VERSION "created by canmatrix"

NS_ :

BS_:

BU_: IPD

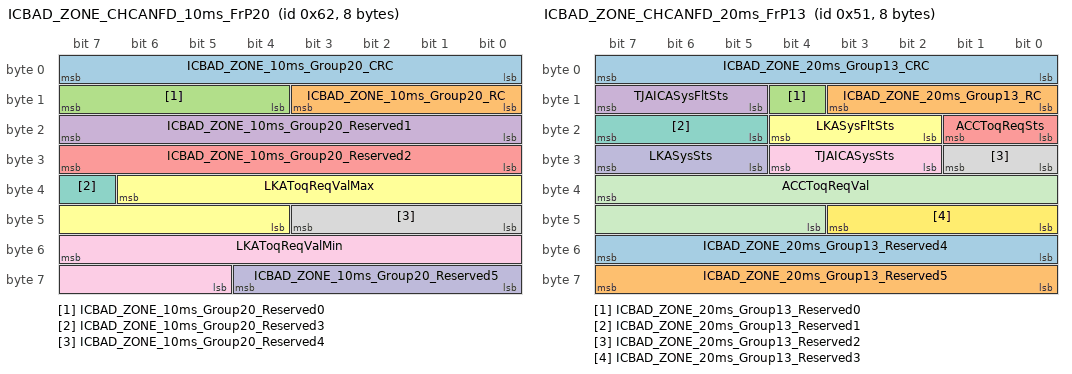
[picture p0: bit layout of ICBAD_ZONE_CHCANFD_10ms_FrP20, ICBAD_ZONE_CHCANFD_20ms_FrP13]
BO_ 98 ICBAD_ZONE_CHCANFD_10ms_FrP20: 8 IPD
 SG_ ICBAD_ZONE_10ms_Group20_CRC : 7|8@0+ (1,0) [0|255] "null" Vector__XXX
 SG_ ICBAD_ZONE_10ms_Group20_RC : 11|4@0+ (1,0) [0|15] "null" Vector__XXX
 SG_ ICBAD_ZONE_10ms_Group20_Reserved0 : 15|4@0+ (1,0) [0|15] "null" Vector__XXX
 SG_ ICBAD_ZONE_10ms_Group20_Reserved1 : 23|8@0+ (1,0) [0|255] "null" Vector__XXX
 SG_ ICBAD_ZONE_10ms_Group20_Reserved2 : 31|8@0+ (1,0) [0|255] "null" Vector__XXX
 SG_ LKAToqReqValMax : 38|11@0+ (0.01,-10.24) [-10.24|10.23] "Nm" Vector__XXX
 SG_ ICBAD_ZONE_10ms_Group20_Reserved3 : 39|1@0+ (1,0) [0|1] "null" Vector__XXX
 SG_ ICBAD_ZONE_10ms_Group20_Reserved4 : 43|4@0+ (1,0) [0|15] "null" Vector__XXX
 SG_ LKAToqReqValMin : 55|11@0+ (0.01,-10.24) [-10.24|10.23] "Nm" Vector__XXX
 SG_ ICBAD_ZONE_10ms_Group20_Reserved5 : 60|5@0+ (1,0) [0|31] "null" Vector__XXX

BO_ 81 ICBAD_ZONE_CHCANFD_20ms_FrP13: 8 IPD
 SG_ ICBAD_ZONE_20ms_Group13_CRC : 7|8@0+ (1,0) [0|255] "null" Vector__XXX
 SG_ ICBAD_ZONE_20ms_Group13_RC : 11|4@0+ (1,0) [0|15] "null" Vector__XXX
 SG_ ICBAD_ZONE_20ms_Group13_Reserved0 : 12|1@0+ (1,0) [0|1] "null" Vector__XXX
 SG_ TJAICASysFltSts : 15|3@0+ (1,0) [0|7] "null" Vector__XXX
 SG_ ACCToqReqSts : 17|2@0+ (1,0) [0|3] "null" Vector__XXX
 SG_ LKASysFltSts : 20|3@0+ (1,0) [0|7] "null" Vector__XXX
 SG_ ICBAD_ZONE_20ms_Group13_Reserved1 : 23|3@0+ (1,0) [0|7] "null" Vector__XXX
 SG_ ICBAD_ZONE_20ms_Group13_Reserved2 : 25|2@0+ (1,0) [0|3] "null" Vector__XXX
 SG_ TJAICASysSts : 28|3@0+ (1,0) [0|7] "null" Vector__XXX
 SG_ LKASysSts : 31|3@0+ (1,0) [0|7] "null" Vector__XXX
 SG_ ACCToqReqVal : 39|12@0+ (0.5,-848) [-848|1199.5] "null" Vector__XXX
 SG_ ICBAD_ZONE_20ms_Group13_Reserved3 : 43|4@0+ (1,0) [0|15] "null" Vector__XXX
 SG_ ICBAD_ZONE_20ms_Group13_Reserved4 : 55|8@0+ (1,0) [0|255] "null" Vector__XXX
 SG_ ICBAD_ZONE_20ms_Group13_Reserved5 : 63|8@0+ (1,0) [0|255] "null" Vector__XXX

BO_ 807 IPD_BKPCANFD_100ms_FrP35: 64 IPD
 SG_ TSRTrgtWarnSign : 23|7@0+ (1,0) [0|127] "null" Vector__XXX
 SG_ SpdAstSysTrgtSpd_IPD : 55|15@0+ (0.015625,0) [0.000000|511.984375] "null" Vector__XXX
 SG_ TSRTrgtBanSign : 77|6@0+ (1,0) [0|63] "null" Vector__XXX
 SG_ TSRSwReqResp : 97|2@0+ (1,0) [0|3] "null" Vector__XXX
 SG_ SLIFSts_IPD : 100|3@0+ (1,0) [0|7] "null" Vector__XXX
 SG_ TSRSts : 111|3@0+ (1,0) [0|7] "null" Vector__XXX
 SG_ PilotSysAVCamrF1FltSts : 244|3@0+ (1,0) [0|7] "null" Vector__XXX
 SG_ PilotSysADASFltSts : 247|3@0+ (1,0) [0|7] "null" Vector__XXX
 SG_ AIParkngSSPLotSwSts : 249|2@0+ (1,0) [0|3] "null" Vector__XXX
 SG_ PilotSysAVCamrRFltSts : 252|3@0+ (1,0) [0|7] "null" Vector__XXX
 SG_ PilotSysAVCamrF3FltSts : 255|3@0+ (1,0) [0|7] "null" Vector__XXX
 SG_ PilotSysAVCamrFRSFltSts : 260|3@0+ (1,0) [0|7] "null" Vector__XXX
 SG_ PilotSysAVCamrFLSFltSts : 263|3@0+ (1,0) [0|7] "null" Vector__XXX
 SG_ PilotSysAVCamrRRSFltSts : 268|3@0+ (1,0) [0|7] "null" Vector__XXX
 SG_ PilotSysAVCamrRLSFltSts : 271|3@0+ (1,0) [0|7] "null" Vector__XXX
 SG_ PilotSysHDAVMCamrRFltSts : 276|3@0+ (1,0) [0|7] "null" Vector__XXX
 SG_ PilotSysHDAVMCamrFFltSts : 279|3@0+ (1,0) [0|7] "null" Vector__XXX
 SG_ PilotSysHDAVMCamrRHFltSts : 284|3@0+ (1,0) [0|7] "null" Vector__XXX
 SG_ PilotSysHDAVMCamrLHFltSts : 287|3@0+ (1,0) [0|7] "null" Vector__XXX
 SG_ SLIFWrnngMdResp : 289|2@0+ (1,0) [0|3] "null" Vector__XXX
 SG_ PilotSysLFSDAFltSts : 292|3@0+ (1,0) [0|7] "null" Vector__XXX
 SG_ PilotSysFDRFltSts : 295|3@0+ (1,0) [0|7] "null" Vector__XXX
 SG_ TrgtSpdSrcSts_IPD : 297|2@0+ (1,0) [0|3] "null" Vector__XXX
 SG_ PilotSysLHRDAFltSts : 300|3@0+ (1,0) [0|7] "null" Vector__XXX
 SG_ PilotSysRFSDAFltSts : 303|3@0+ (1,0) [0|7] "null" Vector__XXX
 SG_ SLIFAudWrnng_IPD : 304|1@0+ (1,0) [0|1] "null" Vector__XXX
 SG_ SLIFUpdtInd_IPD : 305|1@0+ (1,0) [0|1] "null" Vector__XXX
 SG_ PilotSysFLIDARFltSts : 308|3@0+ (1,0) [0|7] "null" Vector__XXX
 SG_ PilotSysRHRDAFltSts : 311|3@0+ (1,0) [0|7] "null" Vector__XXX
 SG_ PilotSysUSSFltSts : 319|3@0+ (1,0) [0|7] "null" Vector__XXX
 SG_ HORWarningEvtSts : 338|3@0+ (1,0) [0|7] "null" Vector__XXX
 SG_ EORWarningEvtSts : 341|3@0+ (1,0) [0|7] "null" Vector__XXX
 SG_ PosALCFailed : 351|8@0+ (1,0) [0|255] "null" Vector__XXX
 SG_ SLIFSysFltSts : 355|3@0+ (1,0) [0|7] "null" Vector__XXX
 SG_ ADS_ISAMsgReq : 359|4@0+ (1,0) [0|15] "null" Vector__XXX
 SG_ SLIFUpdtIndResp_IPD : 361|2@0+ (1,0) [0|3] "null" Vector__XXX
 SG_ ADS_ISASysFltSts : 364|3@0+ (1,0) [0|7] "null" Vector__XXX
 SG_ ADS_ISASysSts : 367|3@0+ (1,0) [0|7] "null" Vector__XXX
 SG_ ParkngSpdSwResp : 375|2@0+ (1,0) [0|3] "null" Vector__XXX

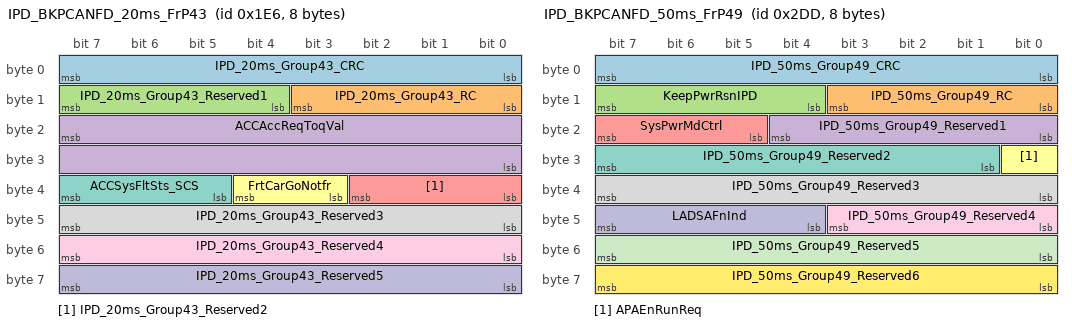
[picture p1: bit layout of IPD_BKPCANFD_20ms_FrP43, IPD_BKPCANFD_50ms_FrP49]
BO_ 486 IPD_BKPCANFD_20ms_FrP43: 8 IPD
 SG_ IPD_20ms_Group43_CRC : 7|8@0+ (1,0) [0|255] "null" Vector__XXX
 SG_ IPD_20ms_Group43_RC : 11|4@0+ (1,0) [0|15] "null" Vector__XXX
 SG_ IPD_20ms_Group43_Reserved1 : 15|4@0+ (1,0) [0|15] "null" Vector__XXX
 SG_ ACCAccReqToqVal : 23|16@0+ (1,0) [0|65535] "Nm" Vector__XXX
 SG_ IPD_20ms_Group43_Reserved2 : 34|3@0+ (1,0) [0|7] "null" Vector__XXX
 SG_ FrtCarGoNotfr : 36|2@0+ (1,0) [0|3] "null" Vector__XXX
 SG_ ACCSysFltSts_SCS : 39|3@0+ (1,0) [0|7] "null" Vector__XXX
 SG_ IPD_20ms_Group43_Reserved3 : 47|8@0+ (1,0) [0|255] "null" Vector__XXX
 SG_ IPD_20ms_Group43_Reserved4 : 55|8@0+ (1,0) [0|255] "null" Vector__XXX
 SG_ IPD_20ms_Group43_Reserved5 : 63|8@0+ (1,0) [0|255] "null" Vector__XXX

BO_ 337 IPD_BKPCANFD_20ms_FrP60: 20 IPD
 SG_ IPD_20ms_Group60_CRC : 7|8@0+ (1,0) [0|255] "null" Vector__XXX
 SG_ IPD_20ms_Group60_RC : 11|4@0+ (1,0) [0|15] "null" Vector__XXX
 SG_ AutoLaneChngRLaneSts : 15|4@0+ (1,0) [0|15] "null" Vector__XXX
 SG_ IPD_20ms_Group60_Reserved1 : 23|8@0+ (1,0) [0|255] "null" Vector__XXX
 SG_ IPD_20ms_Group60_Reserved2 : 31|8@0+ (1,0) [0|255] "null" Vector__XXX
 SG_ APASCSToqReqVal : 39|16@0+ (1,0) [0|65535] "Nm" Vector__XXX
 SG_ APAVehCrdnatPosY : 55|13@0+ (1,-4096) [-4096|4095] "cm" Vector__XXX
 SG_ APAVehCrdnatAzmth : 56|9@0+ (1,0) [0|511] "degree" Vector__XXX
 SG_ ESSDirInd : 58|2@0+ (1,0) [0|3] "null" Vector__XXX
 SG_ PilotTkovMsgReq : 75|4@0+ (1,0) [0|15] "null" Vector__XXX
 SG_ NOPSysSts_ZPD : 79|4@0+ (1,0) [0|15] "null" Vector__XXX
 SG_ PrkgDstCtrlSwResp : 81|2@0+ (1,0) [0|3] "null" Vector__XXX
 SG_ ALCSysSts : 84|3@0+ (1,0) [0|7] "null" Vector__XXX
 SG_ ALCSysFltSts : 87|3@0+ (1,0) [0|7] "null" Vector__XXX
 SG_ APAVehCrdnatPosX : 95|12@0+ (1,-2048) [-2048|2047] "cm" Vector__XXX
 SG_ AutoLaneChngLLaneSts : 99|4@0+ (1,0) [0|15] "null" Vector__XXX
 SG_ IPD_20ms_Group60_Reserved4 : 105|2@0+ (1,0) [0|3] "null" Vector__XXX
 SG_ ESSSysSts : 108|3@0+ (1,0) [0|7] "null" Vector__XXX
 SG_ ESSSysFltSts : 111|3@0+ (1,0) [0|7] "null" Vector__XXX
 SG_ IPD_20ms_Group60_Reserved6 : 112|1@0+ (1,0) [0|1] "null" Vector__XXX
 SG_ ESSDrvrTkovReq : 113|1@0+ (1,0) [0|1] "null" Vector__XXX
 SG_ IPD_20ms_Group60_Reserved5 : 116|3@0+ (1,0) [0|7] "null" Vector__XXX
 SG_ Parkngslottype : 119|3@0+ (1,0) [0|7] "null" Vector__XXX
 SG_ IPD_20ms_Group60_Reserved7 : 124|5@0+ (1,0) [0|31] "null" Vector__XXX
 SG_ NOPSysFltSts : 127|3@0+ (1,0) [0|7] "null" Vector__XXX
 SG_ IPD_20ms_Group60_Reserved8 : 135|8@0+ (1,0) [0|255] "null" Vector__XXX
 SG_ IPD_20ms_Group60_Reserved9 : 143|8@0+ (1,0) [0|255] "null" Vector__XXX
 SG_ IPD_20ms_Group60_Reserved10 : 151|8@0+ (1,0) [0|255] "null" Vector__XXX
 SG_ IPD_20ms_Group60_Reserved11 : 159|8@0+ (1,0) [0|255] "null" Vector__XXX

BO_ 733 IPD_BKPCANFD_50ms_FrP49: 8 IPD
 SG_ IPD_50ms_Group49_CRC : 7|8@0+ (1,0) [0|255] "null" Vector__XXX
 SG_ IPD_50ms_Group49_RC : 11|4@0+ (1,0) [0|15] "null" Vector__XXX
 SG_ KeepPwrRsnIPD : 15|4@0+ (1,0) [0|15] "null" Vector__XXX
 SG_ IPD_50ms_Group49_Reserved1 : 20|5@0+ (1,0) [0|31] "null" Vector__XXX
 SG_ SysPwrMdCtrl : 23|3@0+ (1,0) [0|7] "null" Vector__XXX
 SG_ APAEnRunReq : 24|1@0+ (1,0) [0|1] "null" Vector__XXX
 SG_ IPD_50ms_Group49_Reserved2 : 31|7@0+ (1,0) [0|127] "null" Vector__XXX
 SG_ IPD_50ms_Group49_Reserved3 : 39|8@0+ (1,0) [0|255] "null" Vector__XXX
 SG_ IPD_50ms_Group49_Reserved4 : 43|4@0+ (1,0) [0|15] "null" Vector__XXX
 SG_ LADSAFnInd : 47|4@0+ (1,0) [0|15] "null" Vector__XXX
 SG_ IPD_50ms_Group49_Reserved5 : 55|8@0+ (1,0) [0|255] "null" Vector__XXX
 SG_ IPD_50ms_Group49_Reserved6 : 63|8@0+ (1,0) [0|255] "null" Vector__XXX

BO_ 590 IPD_BKPCANFD_50ms_FrP62: 32 IPD
 SG_ RoadProfileShockDistL1 : 23|10@0+ (0.05,0) [0.00|51.15] "null" Vector__XXX
 SG_ RoadProfileShockDistL2 : 25|10@0+ (0.05,0) [0.00|51.15] "null" Vector__XXX
 SG_ RoadProfileShockDetectedL1 : 29|4@0+ (1,0) [0|15] "null" Vector__XXX
 SG_ RoadProfileShockDistL3 : 47|10@0+ (0.05,0) [0.00|51.15] "null" Vector__XXX
 SG_ RoadProfileShockDistR1 : 49|10@0+ (0.05,0) [0.00|51.15] "null" Vector__XXX
 SG_ RoadProfileShockDetectedL2 : 53|4@0+ (1,0) [0|15] "null" Vector__XXX
 SG_ RoadProfileShockDistR2 : 71|10@0+ (0.05,0) [0.00|51.15] "null" Vector__XXX
 SG_ RoadProfileShockDistR3 : 73|10@0+ (0.05,0) [0.00|51.15] "null" Vector__XXX
 SG_ RoadProfileShockDetectedL3 : 77|4@0+ (1,0) [0|15] "null" Vector__XXX
 SG_ RoadProfileShockHeightL1 : 95|9@0- (0.002,0) [-0.512|0.510] "null" Vector__XXX
 SG_ RoadProfileShockConfidenceL1 : 102|7@0+ (0.01,0) [0.00|1.27] "percent" Vector__XXX
 SG_ RoadProfileShockHeightL2 : 111|9@0- (0.002,0) [-0.512|0.510] "null" Vector__XXX
 SG_ RoadProfileShockConfidenceL2 : 118|7@0+ (0.01,0) [0.00|1.27] "percent" Vector__XXX
 SG_ RoadProfileShockHeightL3 : 127|9@0- (0.002,0) [-0.512|0.510] "null" Vector__XXX
 SG_ RoadProfileShockConfidenceL3 : 134|7@0+ (0.01,0) [0.00|1.27] "percent" Vector__XXX
 SG_ RoadProfileShockHeightR1 : 143|9@0- (0.002,0) [-0.512|0.510] "null" Vector__XXX
 SG_ RoadProfileShockConfidenceR1 : 150|7@0+ (0.01,0) [0.00|1.27] "percent" Vector__XXX
 SG_ RoadProfileShockHeightR2 : 159|9@0- (0.002,0) [-0.512|0.510] "null" Vector__XXX
 SG_ RoadProfileShockConfidenceR2 : 166|7@0+ (0.01,0) [0.00|1.27] "percent" Vector__XXX
 SG_ RoadProfileShockHeightR3 : 175|9@0- (0.002,0) [-0.512|0.510] "null" Vector__XXX
 SG_ RoadProfileShockConfidenceR3 : 182|7@0+ (0.01,0) [0.00|1.27] "percent" Vector__XXX
 SG_ RoadHeightL : 191|9@0- (0.002,0) [-0.512|0.510] "null" Vector__XXX
 SG_ PrvOutSts : 194|2@0+ (1,0) [0|3] "null" Vector__XXX
 SG_ RoadProfileShockDetectedR1 : 198|4@0+ (1,0) [0|15] "null" Vector__XXX
 SG_ RoadHeightR : 207|9@0- (0.002,0) [-0.512|0.510] "null" Vector__XXX
 SG_ RoadProfileShockDetectedR3 : 219|4@0+ (1,0) [0|15] "null" Vector__XXX
 SG_ RoadProfileShockDetectedR2 : 223|4@0+ (1,0) [0|15] "null" Vector__XXX

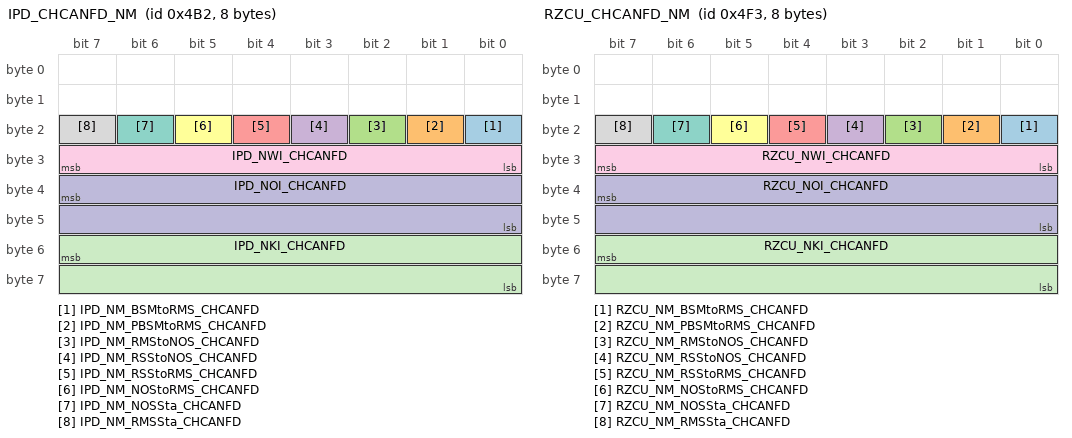
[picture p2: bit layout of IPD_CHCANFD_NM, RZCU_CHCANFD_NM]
BO_ 1202 IPD_CHCANFD_NM: 8 IPD
 SG_ IPD_NM_BSMtoRMS_CHCANFD : 16|1@0+ (1,0) [0|1] "null" Vector__XXX
 SG_ IPD_NM_PBSMtoRMS_CHCANFD : 17|1@0+ (1,0) [0|1] "null" Vector__XXX
 SG_ IPD_NM_RMStoNOS_CHCANFD : 18|1@0+ (1,0) [0|1] "null" Vector__XXX
 SG_ IPD_NM_RSStoNOS_CHCANFD : 19|1@0+ (1,0) [0|1] "null" Vector__XXX
 SG_ IPD_NM_RSStoRMS_CHCANFD : 20|1@0+ (1,0) [0|1] "null" Vector__XXX
 SG_ IPD_NM_NOStoRMS_CHCANFD : 21|1@0+ (1,0) [0|1] "null" Vector__XXX
 SG_ IPD_NM_NOSSta_CHCANFD : 22|1@0+ (1,0) [0|1] "null" Vector__XXX
 SG_ IPD_NM_RMSSta_CHCANFD : 23|1@0+ (1,0) [0|1] "null" Vector__XXX
 SG_ IPD_NWI_CHCANFD : 31|8@0+ (1,0) [0|255] "null" Vector__XXX
 SG_ IPD_NOI_CHCANFD : 39|16@0+ (1,0) [0|65535] "null" Vector__XXX
 SG_ IPD_NKI_CHCANFD : 55|16@0+ (1,0) [0|65535] "null" Vector__XXX

BO_ 1267 RZCU_CHCANFD_NM: 8 Vector__XXX
 SG_ RZCU_NM_BSMtoRMS_CHCANFD : 16|1@0+ (1,0) [0|1] "null" Vector__XXX
 SG_ RZCU_NM_PBSMtoRMS_CHCANFD : 17|1@0+ (1,0) [0|1] "null" Vector__XXX
 SG_ RZCU_NM_RMStoNOS_CHCANFD : 18|1@0+ (1,0) [0|1] "null" Vector__XXX
 SG_ RZCU_NM_RSStoNOS_CHCANFD : 19|1@0+ (1,0) [0|1] "null" Vector__XXX
 SG_ RZCU_NM_RSStoRMS_CHCANFD : 20|1@0+ (1,0) [0|1] "null" Vector__XXX
 SG_ RZCU_NM_NOStoRMS_CHCANFD : 21|1@0+ (1,0) [0|1] "null" Vector__XXX
 SG_ RZCU_NM_NOSSta_CHCANFD : 22|1@0+ (1,0) [0|1] "null" Vector__XXX
 SG_ RZCU_NM_RMSSta_CHCANFD : 23|1@0+ (1,0) [0|1] "null" Vector__XXX
 SG_ RZCU_NWI_CHCANFD : 31|8@0+ (1,0) [0|255] "null" Vector__XXX
 SG_ RZCU_NOI_CHCANFD : 39|16@0+ (1,0) [0|65535] "null" Vector__XXX
 SG_ RZCU_NKI_CHCANFD : 55|16@0+ (1,0) [0|65535] "null" Vector__XXX

BO_ 143 RZCU_RZCUCANFD_10ms_FrP64: 32 Vector__XXX
 SG_ RZCU_ZONE_10ms_Group64_CRC : 7|8@0+ (1,0) [0|255] "null" IPD
 SG_ RZCU_ZONE_10ms_Group64_RC : 11|4@0+ (1,0) [0|15] "null" IPD
 SG_ AngularRateXsecinfoV : 12|1@0+ (1,0) [0|1] "null" IPD
 SG_ AccelerationZsecinfoV : 13|1@0+ (1,0) [0|1] "null" IPD
 SG_ AccelerationYsecinfoV : 14|1@0+ (1,0) [0|1] "null" IPD
 SG_ AccelerationXsecinfoV : 15|1@0+ (1,0) [0|1] "null" IPD
 SG_ AccelerationXsecinfo : 23|24@0- (0.00010,0) [-838.86080|838.86070] "m/s2" IPD
 SG_ AccelerationYsecinfo : 47|24@0- (0.00010,0) [-838.86080|838.86070] "m/s2" IPD
 SG_ AccelerationZsecinfo : 71|24@0- (0.00010,0) [-838.86080|838.86070] "m/s2" IPD
 SG_ AngularRateXsecinfo : 95|24@0- (0.000010,0) [-83.886080|83.886070] "°/s" IPD
 SG_ AngularRateYsecinfo : 119|24@0- (0.000010,0) [-83.886080|83.886070] "°/s" IPD
 SG_ AngularRateZsecinfo : 143|24@0- (0.000010,0) [-83.886080|83.886070] "°/s" IPD
 SG_ IMUTmp : 163|12@0- (0.1,0) [-204.8|204.7] "degreecelslus" IPD
 SG_ TireBlowoutStabCtrlSts : 165|2@0+ (1,0) [0|3] "null" IPD
 SG_ AngularRateZsecinfoV : 166|1@0+ (1,0) [0|1] "null" IPD
 SG_ AngularRateYsecinfoV : 167|1@0+ (1,0) [0|1] "null" IPD
 SG_ IMUseq : 183|32@0+ (1,0) [0|4294967295] "/" IPD
 SG_ RZCU_ZONE_10ms_Group64_Reserved1 : 211|4@0+ (1,0) [0|15] "null" IPD
 SG_ TireBlowoutPos : 215|4@0+ (1,0) [0|15] "null" IPD
 SG_ RZCU_ZONE_10ms_Group64_Reserved2 : 223|8@0+ (1,0) [0|255] "null" IPD
 SG_ RZCU_ZONE_10ms_Group64_Reserved3 : 231|8@0+ (1,0) [0|255] "null" IPD
 SG_ RZCU_ZONE_10ms_Group64_Reserved4 : 239|8@0+ (1,0) [0|255] "null" IPD
 SG_ RZCU_ZONE_10ms_Group64_Reserved5 : 247|8@0+ (1,0) [0|255] "null" IPD
 SG_ RZCU_ZONE_10ms_Group64_Reserved6 : 255|8@0+ (1,0) [0|255] "null" IPD

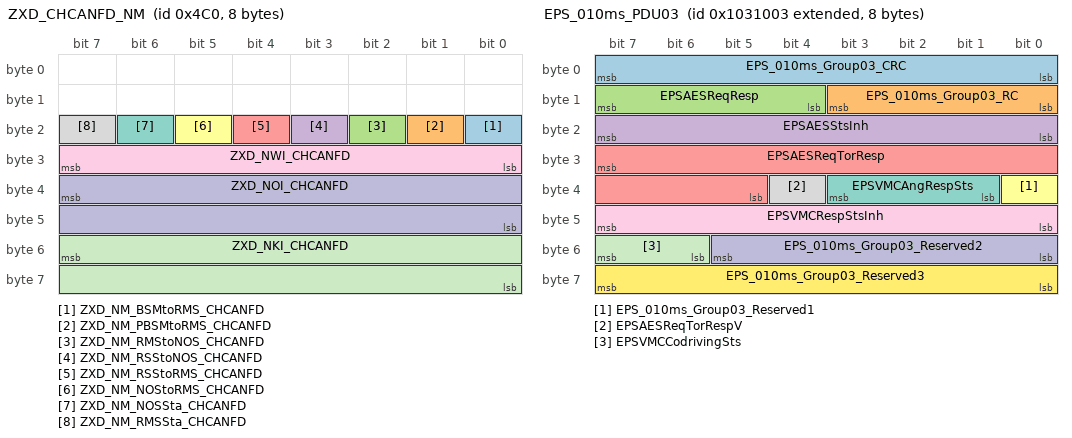
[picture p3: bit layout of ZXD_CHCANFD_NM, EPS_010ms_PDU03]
BO_ 1216 ZXD_CHCANFD_NM: 8 Vector__XXX
 SG_ ZXD_NM_BSMtoRMS_CHCANFD : 16|1@0+ (1,0) [0|1] "null" Vector__XXX
 SG_ ZXD_NM_PBSMtoRMS_CHCANFD : 17|1@0+ (1,0) [0|1] "null" Vector__XXX
 SG_ ZXD_NM_RMStoNOS_CHCANFD : 18|1@0+ (1,0) [0|1] "null" Vector__XXX
 SG_ ZXD_NM_RSStoNOS_CHCANFD : 19|1@0+ (1,0) [0|1] "null" Vector__XXX
 SG_ ZXD_NM_RSStoRMS_CHCANFD : 20|1@0+ (1,0) [0|1] "null" Vector__XXX
 SG_ ZXD_NM_NOStoRMS_CHCANFD : 21|1@0+ (1,0) [0|1] "null" Vector__XXX
 SG_ ZXD_NM_NOSSta_CHCANFD : 22|1@0+ (1,0) [0|1] "null" Vector__XXX
 SG_ ZXD_NM_RMSSta_CHCANFD : 23|1@0+ (1,0) [0|1] "null" Vector__XXX
 SG_ ZXD_NWI_CHCANFD : 31|8@0+ (1,0) [0|255] "null" Vector__XXX
 SG_ ZXD_NOI_CHCANFD : 39|16@0+ (1,0) [0|65535] "null" Vector__XXX
 SG_ ZXD_NKI_CHCANFD : 55|16@0+ (1,0) [0|65535] "null" Vector__XXX

BO_ 2164461571 EPS_010ms_PDU03: 8 Vector__XXX
 SG_ EPS_010ms_Group03_CRC : 7|8@0+ (1,0) [0|255] "null" IPD
 SG_ EPS_010ms_Group03_RC : 11|4@0+ (1,0) [0|15] "null" IPD
 SG_ EPSAESReqResp : 15|4@0+ (1,0) [0|15] "null" IPD
 SG_ EPSAESStsInh : 23|8@0+ (1,0) [0|255] "null" IPD
 SG_ EPSAESReqTorResp : 31|11@0+ (0.01,-10.24) [-10.24|10.23] "Nm" IPD
 SG_ EPS_010ms_Group03_Reserved1 : 32|1@0+ (1,0) [0|1] "null" IPD
 SG_ EPSVMCAngRespSts : 35|3@0+ (1,0) [0|7] "null" IPD
 SG_ EPSAESReqTorRespV : 36|1@0+ (1,0) [0|1] "null" IPD
 SG_ EPSVMCRespStsInh : 47|8@0+ (1,0) [0|255] "null" IPD
 SG_ EPS_010ms_Group03_Reserved2 : 53|6@0+ (1,0) [0|63] "null" IPD
 SG_ EPSVMCCodrivingSts : 55|2@0+ (1,0) [0|3] "null" IPD
 SG_ EPS_010ms_Group03_Reserved3 : 63|8@0+ (1,0) [0|255] "null" IPD

BO_ 2164729093 EPS_10ms_PDU01: 24 Vector__XXX
 SG_ EPS_10ms_Group01_CRC : 7|8@0+ (1,0) [0|255] "null" IPD
 SG_ EPS_10ms_Group01_RC : 11|4@0+ (1,0) [0|15] "null" IPD
 SG_ ActuRoadWhlAngV : 12|1@0+ (1,0) [0|1] "null" IPD
 SG_ ADASStrgDlvrdToqV : 13|1@0+ (1,0) [0|1] "null" IPD
 SG_ EPSDrvngMdCtrlInh : 14|1@0+ (1,0) [0|1] "null" IPD
 SG_ DrvrStrgDlvrdToqV : 15|1@0+ (1,0) [0|1] "null" IPD
 SG_ ActuPnonAng : 23|16@0+ (0.0625,-2048) [-2048.0000|2047.9375] "degree" IPD
 SG_ ActuRoadWhlAng : 39|16@0+ (0.005,-163) [-163.000|164.675] "degree" IPD
 SG_ StrgCustSetngDspCmd : 49|2@0+ (1,0) [0|3] "null" IPD
 SG_ EPSPriyChnlFlrSts : 51|2@0+ (1,0) [0|3] "null" IPD
 SG_ EPSFlrSts : 53|2@0+ (1,0) [0|3] "null" IPD
 SG_ EPSCurntDrvMd : 55|2@0+ (1,0) [0|3] "null" IPD
 SG_ ActuPnonAngV : 56|1@0+ (1,0) [0|1] "null" IPD
 SG_ EPSToqValAldMaxV : 57|1@0+ (1,0) [0|1] "null" IPD
 SG_ EPSLimMotToqV : 58|1@0+ (1,0) [0|1] "null" IPD
 SG_ EPSActRetMotToqV : 59|1@0+ (1,0) [0|1] "null" IPD
 SG_ EPS_10ms_Group01_Reserved1 : 60|1@0+ (1,0) [0|1] "null" IPD
 SG_ ChLKAAngReqResp : 63|3@0+ (1,0) [0|7] "null" IPD
 SG_ EPS_10ms_Group01_Reserved2 : 67|4@0+ (1,0) [0|15] "null" IPD
 SG_ EPSToqValAldMinV : 68|1@0+ (1,0) [0|1] "null" IPD
 SG_ CHLKAHptResp : 71|3@0+ (1,0) [0|7] "null" IPD
 SG_ EPS_10ms_Group01_Reserved3 : 79|8@0+ (1,0) [0|255] "null" IPD
 SG_ ADASStrgDlvrdToq : 82|11@0+ (0.01,-10.24) [-10.24|10.23] "Nm" IPD
 SG_ EPS_10ms_Group01_Reserved4 : 84|2@0+ (1,0) [0|3] "null" IPD
 SG_ ChLKAToqReqResp : 87|3@0+ (1,0) [0|7] "null" IPD
 SG_ EPSToqValAldMax : 98|11@0+ (0.01,-10.24) [-10.24|10.23] "Nm" IPD
 SG_ EPSCoDrivingSts : 100|2@0+ (1,0) [0|3] "null" IPD
 SG_ EPS_10ms_Group01_Reserved5 : 103|3@0+ (1,0) [0|7] "null" IPD
 SG_ EPSToqValAldMin : 114|11@0+ (0.01,-10.24) [-10.24|10.23] "Nm" IPD
 SG_ EPS_10ms_Group01_Reserved6 : 119|5@0+ (1,0) [0|31] "null" IPD
 SG_ EPSActRetMotToq : 135|16@0+ (0.00097656,-32) [-32.00000000|31.99885960] "Nm" IPD
 SG_ EPS_10ms_Group01_Reserved7 : 151|8@0+ (1,0) [0|255] "null" IPD
 SG_ DrvrStrgDlvrdToq : 159|12@0+ (0.01,-20.48) [-20.48|20.47] "Nm" IPD
 SG_ EPS_10ms_Group01_Reserved8 : 163|4@0+ (1,0) [0|15] "null" IPD
 SG_ EPS_10ms_Group01_Reserved9 : 175|8@0+ (1,0) [0|255] "null" IPD
 SG_ EPSLimMotToq : 183|16@0+ (0.00097656,-32) [-32.00000000|31.99885960] "Nm" IPD

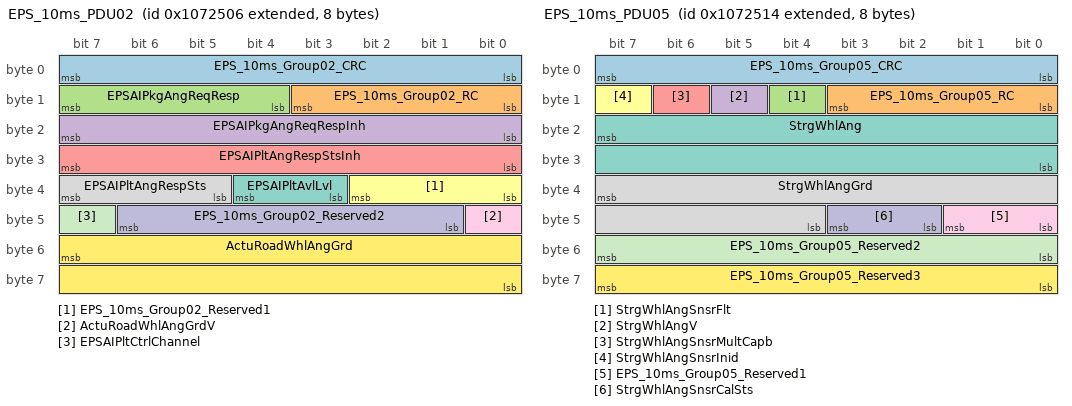
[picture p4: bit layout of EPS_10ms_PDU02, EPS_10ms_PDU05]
BO_ 2164729094 EPS_10ms_PDU02: 8 Vector__XXX
 SG_ EPS_10ms_Group02_CRC : 7|8@0+ (1,0) [0|255] "null" IPD
 SG_ EPS_10ms_Group02_RC : 11|4@0+ (1,0) [0|15] "null" IPD
 SG_ EPSAIPkgAngReqResp : 15|4@0+ (1,0) [0|15] "null" IPD
 SG_ EPSAIPkgAngReqRespInh : 23|8@0+ (1,0) [0|255] "null" IPD
 SG_ EPSAIPltAngRespStsInh : 31|8@0+ (1,0) [0|255] "null" IPD
 SG_ EPS_10ms_Group02_Reserved1 : 34|3@0+ (1,0) [0|7] "null" IPD
 SG_ EPSAIPltAvlLvl : 36|2@0+ (1,0) [0|3] "null" IPD
 SG_ EPSAIPltAngRespSts : 39|3@0+ (1,0) [0|7] "null" IPD
 SG_ ActuRoadWhlAngGrdV : 40|1@0+ (1,0) [0|1] "null" IPD
 SG_ EPS_10ms_Group02_Reserved2 : 46|6@0+ (1,0) [0|63] "null" IPD
 SG_ EPSAIPltCtrlChannel : 47|1@0+ (1,0) [0|1] "null" IPD
 SG_ ActuRoadWhlAngGrd : 55|16@0+ (0.005,-163) [-163.000|164.675] "deg_s" IPD

BO_ 2164729108 EPS_10ms_PDU05: 8 Vector__XXX
 SG_ EPS_10ms_Group05_CRC : 7|8@0+ (1,0) [0|255] "null" IPD
 SG_ EPS_10ms_Group05_RC : 11|4@0+ (1,0) [0|15] "null" IPD
 SG_ StrgWhlAngSnsrFlt : 12|1@0+ (1,0) [0|1] "null" IPD
 SG_ StrgWhlAngV : 13|1@0+ (1,0) [0|1] "null" IPD
 SG_ StrgWhlAngSnsrMultCapb : 14|1@0+ (1,0) [0|1] "null" IPD
 SG_ StrgWhlAngSnsrInid : 15|1@0+ (1,0) [0|1] "null" IPD
 SG_ StrgWhlAng : 23|16@0+ (0.0625,-2048) [-2048.0000|2047.9375] "degree" IPD
 SG_ StrgWhlAngGrd : 39|12@0+ (1,-2048) [-2048|2047] "degree/s" IPD
 SG_ EPS_10ms_Group05_Reserved1 : 41|2@0+ (1,0) [0|3] "null" IPD
 SG_ StrgWhlAngSnsrCalSts : 43|2@0+ (1,0) [0|3] "null" IPD
 SG_ EPS_10ms_Group05_Reserved2 : 55|8@0+ (1,0) [0|255] "null" IPD
 SG_ EPS_10ms_Group05_Reserved3 : 63|8@0+ (1,0) [0|255] "null" IPD

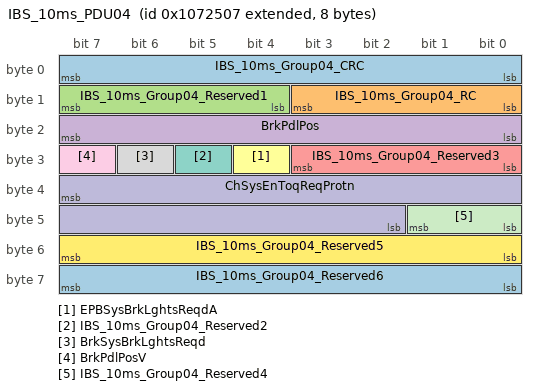
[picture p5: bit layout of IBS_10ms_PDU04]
BO_ 2164729095 IBS_10ms_PDU04: 8 Vector__XXX
 SG_ IBS_10ms_Group04_CRC : 7|8@0+ (1,0) [0|255] "null" IPD
 SG_ IBS_10ms_Group04_RC : 11|4@0+ (1,0) [0|15] "null" IPD
 SG_ IBS_10ms_Group04_Reserved1 : 15|4@0+ (1,0) [0|15] "null" IPD
 SG_ BrkPdlPos : 23|8@0+ (0.392157,0) [0.000000|100.000035] "Percent" IPD
 SG_ IBS_10ms_Group04_Reserved3 : 27|4@0+ (1,0) [0|15] "null" IPD
 SG_ EPBSysBrkLghtsReqdA : 28|1@0+ (1,0) [0|1] "null" IPD
 SG_ IBS_10ms_Group04_Reserved2 : 29|1@0+ (1,0) [0|1] "null" IPD
 SG_ BrkSysBrkLghtsReqd : 30|1@0+ (1,0) [0|1] "null" IPD
 SG_ BrkPdlPosV : 31|1@0+ (1,0) [0|1] "null" IPD
 SG_ ChSysEnToqReqProtn : 39|14@0+ (1,0) [0|16383] "null" IPD
 SG_ IBS_10ms_Group04_Reserved4 : 41|2@0+ (1,0) [0|3] "null" IPD
 SG_ IBS_10ms_Group04_Reserved5 : 55|8@0+ (1,0) [0|255] "null" IPD
 SG_ IBS_10ms_Group04_Reserved6 : 63|8@0+ (1,0) [0|255] "null" IPD

BO_ 2164729097 IBS_20ms_PDU10: 8 Vector__XXX
 SG_ IBS_20ms_Group10_CRC : 7|8@0+ (1,0) [0|255] "null" IPD
 SG_ IBS_20ms_Group10_RC : 11|4@0+ (1,0) [0|15] "null" IPD
 SG_ BrkPdlDrvrAppdPrsV : 12|1@0+ (1,0) [0|1] "null" IPD
 SG_ BrkPdlDrvrAppdPrsDetV : 13|1@0+ (1,0) [0|1] "null" IPD
 SG_ BrkPdlDrvrAppdPrsDet : 14|1@0+ (1,0) [0|1] "null" IPD
 SG_ BrkDiscTemSts : 15|1@0+ (1,0) [0|1] "null" IPD
 SG_ BrkPdlDrvrAppdPrs : 23|8@0+ (75,0) [0|19125] "kPa" IPD
 SG_ BrkPdlMdlSts : 25|2@0+ (1,0) [0|3] "null" IPD
 SG_ DrvrReqOtptRodTrvlSts : 27|2@0+ (1,0) [0|3] "null" IPD
 SG_ BrkPdlSimltdPrsV : 28|1@0+ (1,0) [0|1] "null" IPD
 SG_ BrkPdlAppd : 29|1@0+ (1,0) [0|1] "null" IPD
 SG_ BrkPdlAppdV : 31|2@0+ (1,0) [0|3] "null" IPD
 SG_ BrkPdlSimltdPrs : 39|8@0+ (75,0) [0|19125] "kPa" IPD
 SG_ BrkFludLvlLowV : 40|1@0+ (1,0) [0|1] "null" IPD
 SG_ BrkFludLvlLow : 41|1@0+ (1,0) [0|1] "null" IPD
 SG_ BrkPdlMdlActSts : 43|2@0+ (1,0) [0|3] "null" IPD
 SG_ IBS_20ms_Group10_Reserved1 : 47|4@0+ (1,0) [0|15] "null" IPD
 SG_ DrvrReqOtptRodTrvl : 51|12@0+ (0.015625,-5) [-5.000000|58.984375] "mm" IPD
 SG_ IBS_20ms_Group10_Reserved2 : 55|4@0+ (1,0) [0|15] "null" IPD

BO_ 2164729104 IBS_20ms_PDU13: 8 Vector__XXX
 SG_ IBS_20ms_Group13_CRC : 7|8@0+ (1,0) [0|255] "null" IPD
 SG_ IBS_20ms_Group13_RC : 11|4@0+ (1,0) [0|15] "null" IPD
 SG_ ACCBrkngA : 12|1@0+ (1,0) [0|1] "null" IPD
 SG_ ChAEBDclReqResp : 15|3@0+ (1,0) [0|7] "null" IPD
 SG_ ChACCReqFlrSts : 17|2@0+ (1,0) [0|3] "null" IPD
 SG_ ChACCAccReqResp : 20|3@0+ (1,0) [0|7] "null" IPD
 SG_ ChAEBPrflReqResp : 23|3@0+ (1,0) [0|7] "null" IPD
 SG_ AutodDrvngSysMdReqRespV : 24|1@0+ (1,0) [0|1] "null" IPD
 SG_ AutodDrvngSysMdReqResp : 25|1@0+ (1,0) [0|1] "null" IPD
 SG_ ChAEBHydBrkAstReqResp : 28|3@0+ (1,0) [0|7] "null" IPD
 SG_ ChAEBBrkJerkReqResp : 31|3@0+ (1,0) [0|7] "null" IPD
 SG_ SCSAutodDrvngSysSts : 34|3@0+ (1,0) [0|7] "null" IPD
 SG_ SCSAPAAcclAV : 35|1@0+ (1,0) [0|1] "null" IPD
 SG_ SCSAPAAcclA : 36|1@0+ (1,0) [0|1] "null" IPD
 SG_ ExtnlBrkPrioV : 37|1@0+ (1,0) [0|1] "null" IPD
 SG_ ExtnlBrkPrio : 38|1@0+ (1,0) [0|1] "null" IPD
 SG_ EmgcBrkReqdByIECUSts : 39|1@0+ (1,0) [0|1] "null" IPD
 SG_ TCSDrvrItnt : 40|1@0+ (1,0) [0|1] "null" IPD
 SG_ MultColBrkAvlblySts : 41|1@0+ (1,0) [0|1] "null" IPD
 SG_ ChRCTBDclReqResp : 44|3@0+ (1,0) [0|7] "null" IPD
 SG_ SCSVehHoldAV : 45|1@0+ (1,0) [0|1] "null" IPD
 SG_ SCSVehHoldA : 46|1@0+ (1,0) [0|1] "null" IPD
 SG_ SCSAutodDrvngSysStsV : 47|1@0+ (1,0) [0|1] "null" IPD
 SG_ VehSdslStsV : 48|1@0+ (1,0) [0|1] "null" IPD
 SG_ ChRCTBPrflReqResp : 51|3@0+ (1,0) [0|7] "null" IPD
 SG_ WhlBrkPrsSts : 52|1@0+ (1,0) [0|1] "null" IPD
 SG_ BrkSysRddySysSts : 53|1@0+ (1,0) [0|1] "null" IPD
 SG_ VehSdslSts : 55|2@0+ (1,0) [0|3] "null" IPD
 SG_ ChEBADclReqResp : 60|5@0+ (1,0) [0|31] "null" IPD
 SG_ IBSAPASysFltSts : 63|3@0+ (1,0) [0|7] "null" IPD

BA_DEF_ BO_ "FrameTriggeringName" STRING;
BA_DEF_ BO_ "GenMsgCycleTime" INT 0 65535;
BA_DEF_ BO_ "GenMsgSendType" ENUM  "cyclicX","spontanX","cyclicIfActiveX","spontanWithDelay","cyclicAndSpontanX","cyclicAndSpontanWithDelay","spontanWithRepitition","cyclicIfActiveAndSpontanWD","cyclicIfActiveFast","cyclicWithRepeatOnDemand","none";
BA_DEF_ BO_ "GenMsgStartValue" STRING;
BA_DEF_ BO_ "PduName" STRING;
BA_DEF_ BO_ "VFrameFormat" ENUM  "StandardCAN","ExtendedCAN","reserved","reserved","reserved","reserved","reserved","reserved","reserved","reserved","reserved","reserved","reserved","reserved","StandardCAN_FD","ExtendedCAN_FD";
BA_DEF_ SG_ "CompuMethodName" STRING;
BA_DEF_ SG_ "GenSigStartValue" FLOAT 0 100000000000;
BA_DEF_ SG_ "ISignalName" STRING;
BA_DEF_ SG_ "LongName" STRING;
BA_DEF_ SG_ "SysSignalName" STRING;
BA_DEF_ SG_ "SystemSignalLongSymbol" STRING;
BA_ "FrameTriggeringName" BO_ 98 "ICBAD_ZONE_CHCANFD_10ms_FrP20";
BA_ "GenMsgCycleTime" BO_ 98 10;
BA_ "GenMsgSendType" BO_ 98 0;
BA_ "GenMsgStartValue" BO_ 98 "00f0ffffc00f801f";
BA_ "PduName" BO_ 98 "ICBAD_ZONE_10ms_PDU20";
BA_ "VFrameFormat" BO_ 98 14;
BA_ "FrameTriggeringName" BO_ 81 "ICBAD_ZONE_CHCANFD_20ms_FrP13";
BA_ "GenMsgCycleTime" BO_ 81 20;
BA_ "GenMsgSendType" BO_ 81 0;
BA_ "GenMsgStartValue" BO_ 81 "0010e0036a0fffff";
BA_ "PduName" BO_ 81 "ICBAD_ZONE_20ms_PDU13";
BA_ "VFrameFormat" BO_ 81 14;
BA_ "FrameTriggeringName" BO_ 807 "IPD_BKPCANFD_100ms_FrP35";
BA_ "GenMsgCycleTime" BO_ 807 100;
BA_ "GenMsgSendType" BO_ 807 0;
BA_ "GenMsgStartValue" BO_ 807 "00000000000000000000000000000000000000000000000000000000000000000000000000000000000000000000000000000000000000000000000000000000";
BA_ "PduName" BO_ 807 "IPD_100ms_PDU35";
BA_ "VFrameFormat" BO_ 807 14;
BA_ "FrameTriggeringName" BO_ 486 "IPD_BKPCANFD_20ms_FrP43";
BA_ "GenMsgCycleTime" BO_ 486 20;
BA_ "GenMsgSendType" BO_ 486 0;
BA_ "GenMsgStartValue" BO_ 486 "00f0000007ffffff";
BA_ "PduName" BO_ 486 "IPD_20ms_PDU43";
BA_ "VFrameFormat" BO_ 486 14;
BA_ "FrameTriggeringName" BO_ 337 "IPD_BKPCANFD_20ms_FrP60";
BA_ "GenMsgCycleTime" BO_ 337 20;
BA_ "GenMsgSendType" BO_ 337 0;
BA_ "GenMsgStartValue" BO_ 337 "0000ffff000000000000010000071d1fffffffff";
BA_ "PduName" BO_ 337 "IPD_20ms_PDU60";
BA_ "VFrameFormat" BO_ 337 14;
BA_ "FrameTriggeringName" BO_ 733 "IPD_BKPCANFD_50ms_FrP49";
BA_ "GenMsgCycleTime" BO_ 733 50;
BA_ "GenMsgSendType" BO_ 733 0;
BA_ "GenMsgStartValue" BO_ 733 "00001ffeff0fffff";
BA_ "PduName" BO_ 733 "IPD_50ms_PDU49";
BA_ "VFrameFormat" BO_ 733 14;
BA_ "FrameTriggeringName" BO_ 590 "IPD_BKPCANFD_50ms_FrP62";
BA_ "GenMsgCycleTime" BO_ 590 50;
BA_ "GenMsgSendType" BO_ 590 0;
BA_ "GenMsgStartValue" BO_ 590 "0000000000000000000000000000000000000000000000000000000000000000";
BA_ "PduName" BO_ 590 "IPD_50ms_PDU62";
BA_ "VFrameFormat" BO_ 590 14;
BA_ "FrameTriggeringName" BO_ 1202 "IPD_CHCANFD_NM";
BA_ "GenMsgSendType" BO_ 1202 1;
BA_ "GenMsgStartValue" BO_ 1202 "0000000000000000";
BA_ "PduName" BO_ 1202 "NmPDU_CHCANFD_IPD";
BA_ "VFrameFormat" BO_ 1202 14;
BA_ "FrameTriggeringName" BO_ 1267 "RZCU_CHCANFD_NM";
BA_ "GenMsgSendType" BO_ 1267 1;
BA_ "GenMsgStartValue" BO_ 1267 "0000000000000000";
BA_ "PduName" BO_ 1267 "NmPDU_CHCANFD_RZCU";
BA_ "VFrameFormat" BO_ 1267 14;
BA_ "FrameTriggeringName" BO_ 143 "RZCU_RZCUCANFD_10ms_FrP64";
BA_ "GenMsgCycleTime" BO_ 143 10;
BA_ "GenMsgSendType" BO_ 143 0;
BA_ "GenMsgStartValue" BO_ 143 "00000000000000000000000000000000000000000000000000000fffffffffff";
BA_ "PduName" BO_ 143 "RZCU_10ms_PDU64";
BA_ "VFrameFormat" BO_ 143 14;
BA_ "FrameTriggeringName" BO_ 1216 "ZXD_CHCANFD_NM";
BA_ "GenMsgSendType" BO_ 1216 1;
BA_ "GenMsgStartValue" BO_ 1216 "0000000000000000";
BA_ "PduName" BO_ 1216 "NmPDU_CHCANFD_ZXD";
BA_ "VFrameFormat" BO_ 1216 14;
BA_ "FrameTriggeringName" BO_ 2164461571 "EPS_CHCANFD_10ms_ConFrP01__EPS_010ms_PDU03";
BA_ "GenMsgCycleTime" BO_ 2164461571 10;
BA_ "GenMsgSendType" BO_ 2164461571 1;
BA_ "PduName" BO_ 2164461571 "EPS_010ms_PDU03";
BA_ "VFrameFormat" BO_ 2164461571 15;
BA_ "FrameTriggeringName" BO_ 2164729093 "EPS_CHCANFD_10ms_ConFrP01__EPS_10ms_PDU01";
BA_ "GenMsgCycleTime" BO_ 2164729093 10;
BA_ "GenMsgSendType" BO_ 2164729093 1;
BA_ "PduName" BO_ 2164729093 "EPS_10ms_PDU01";
BA_ "VFrameFormat" BO_ 2164729093 15;
BA_ "FrameTriggeringName" BO_ 2164729094 "EPS_CHCANFD_10ms_ConFrP01__EPS_10ms_PDU02";
BA_ "GenMsgCycleTime" BO_ 2164729094 10;
BA_ "GenMsgSendType" BO_ 2164729094 1;
BA_ "PduName" BO_ 2164729094 "EPS_10ms_PDU02";
BA_ "VFrameFormat" BO_ 2164729094 15;
BA_ "FrameTriggeringName" BO_ 2164729108 "EPS_CHCANFD_10ms_ConFrP05__EPS_10ms_PDU05";
BA_ "GenMsgCycleTime" BO_ 2164729108 10;
BA_ "GenMsgSendType" BO_ 2164729108 1;
BA_ "PduName" BO_ 2164729108 "EPS_10ms_PDU05";
BA_ "VFrameFormat" BO_ 2164729108 15;
BA_ "FrameTriggeringName" BO_ 2164729095 "IBS_CHCANFD_10ms_ConFrP04__IBS_10ms_PDU04";
BA_ "GenMsgCycleTime" BO_ 2164729095 10;
BA_ "GenMsgSendType" BO_ 2164729095 1;
BA_ "PduName" BO_ 2164729095 "IBS_10ms_PDU04";
BA_ "VFrameFormat" BO_ 2164729095 15;
BA_ "FrameTriggeringName" BO_ 2164729097 "IBS_CHCANFD_20ms_ConFrP10__IBS_20ms_PDU10";
BA_ "GenMsgCycleTime" BO_ 2164729097 20;
BA_ "GenMsgSendType" BO_ 2164729097 1;
BA_ "PduName" BO_ 2164729097 "IBS_20ms_PDU10";
BA_ "VFrameFormat" BO_ 2164729097 15;
BA_ "FrameTriggeringName" BO_ 2164729104 "IBS_CHCANFD_20ms_ConFrP10__IBS_20ms_PDU13";
BA_ "GenMsgCycleTime" BO_ 2164729104 20;
BA_ "GenMsgSendType" BO_ 2164729104 1;
BA_ "PduName" BO_ 2164729104 "IBS_20ms_PDU13";
BA_ "VFrameFormat" BO_ 2164729104 15;
BA_ "CompuMethodName" SG_ 98 ICBAD_ZONE_10ms_Group20_CRC "ICBAD_ZONE_10ms_Group20_CRC";
BA_ "ISignalName" SG_ 98 ICBAD_ZONE_10ms_Group20_CRC "IICBAD_ZONE_10ms_Group20_CRC";
BA_ "LongName" SG_ 98 ICBAD_ZONE_10ms_Group20_CRC "ICBAD_ZONE_10ms_Group20_CRC";
BA_ "SysSignalName" SG_ 98 ICBAD_ZONE_10ms_Group20_CRC "ICBAD_ZONE_10ms_Group20_CRC";
BA_ "CompuMethodName" SG_ 98 ICBAD_ZONE_10ms_Group20_RC "ICBAD_ZONE_10ms_Group20_RC";
BA_ "ISignalName" SG_ 98 ICBAD_ZONE_10ms_Group20_RC "IICBAD_ZONE_10ms_Group20_RC";
BA_ "LongName" SG_ 98 ICBAD_ZONE_10ms_Group20_RC "ICBAD_ZONE_10ms_Group20_RC";
BA_ "SysSignalName" SG_ 98 ICBAD_ZONE_10ms_Group20_RC "ICBAD_ZONE_10ms_Group20_RC";
BA_ "CompuMethodName" SG_ 98 ICBAD_ZONE_10ms_Group20_Reserved0 "ICBAD_ZONE_10ms_Group20_Reserved1";
BA_ "GenSigStartValue" SG_ 98 ICBAD_ZONE_10ms_Group20_Reserved0 15;
BA_ "ISignalName" SG_ 98 ICBAD_ZONE_10ms_Group20_Reserved0 "IICBAD_ZONE_10ms_Group20_Reserved1";
BA_ "SysSignalName" SG_ 98 ICBAD_ZONE_10ms_Group20_Reserved0 "ICBAD_ZONE_10ms_Group20_Reserved1";
BA_ "SystemSignalLongSymbol" SG_ 98 ICBAD_ZONE_10ms_Group20_Reserved0 "ICBAD_ZONE_10ms_Group20_Reserved1";
BA_ "CompuMethodName" SG_ 98 ICBAD_ZONE_10ms_Group20_Reserved1 "ICBAD_ZONE_10ms_Group20_Reserved2";
BA_ "GenSigStartValue" SG_ 98 ICBAD_ZONE_10ms_Group20_Reserved1 255;
BA_ "ISignalName" SG_ 98 ICBAD_ZONE_10ms_Group20_Reserved1 "IICBAD_ZONE_10ms_Group20_Reserved2";
BA_ "SysSignalName" SG_ 98 ICBAD_ZONE_10ms_Group20_Reserved1 "ICBAD_ZONE_10ms_Group20_Reserved2";
BA_ "SystemSignalLongSymbol" SG_ 98 ICBAD_ZONE_10ms_Group20_Reserved1 "ICBAD_ZONE_10ms_Group20_Reserved2";
BA_ "CompuMethodName" SG_ 98 ICBAD_ZONE_10ms_Group20_Reserved2 "ICBAD_ZONE_10ms_Group20_Reserved3";
BA_ "GenSigStartValue" SG_ 98 ICBAD_ZONE_10ms_Group20_Reserved2 255;
BA_ "ISignalName" SG_ 98 ICBAD_ZONE_10ms_Group20_Reserved2 "IICBAD_ZONE_10ms_Group20_Reserved3";
BA_ "SysSignalName" SG_ 98 ICBAD_ZONE_10ms_Group20_Reserved2 "ICBAD_ZONE_10ms_Group20_Reserved3";
BA_ "SystemSignalLongSymbol" SG_ 98 ICBAD_ZONE_10ms_Group20_Reserved2 "ICBAD_ZONE_10ms_Group20_Reserved3";
BA_ "CompuMethodName" SG_ 98 LKAToqReqValMax "LKAToqReqValMax";
BA_ "GenSigStartValue" SG_ 98 LKAToqReqValMax 1024;
BA_ "ISignalName" SG_ 98 LKAToqReqValMax "ILKAToqReqValMax";
BA_ "LongName" SG_ 98 LKAToqReqValMax "Lane Keeping Assist Torque Request Value Maximum";
BA_ "SysSignalName" SG_ 98 LKAToqReqValMax "LKAToqReqValMax";
BA_ "CompuMethodName" SG_ 98 ICBAD_ZONE_10ms_Group20_Reserved3 "ICBAD_ZONE_10ms_Group20_Reserved4";
BA_ "GenSigStartValue" SG_ 98 ICBAD_ZONE_10ms_Group20_Reserved3 1;
BA_ "ISignalName" SG_ 98 ICBAD_ZONE_10ms_Group20_Reserved3 "IICBAD_ZONE_10ms_Group20_Reserved4";
BA_ "SysSignalName" SG_ 98 ICBAD_ZONE_10ms_Group20_Reserved3 "ICBAD_ZONE_10ms_Group20_Reserved4";
BA_ "SystemSignalLongSymbol" SG_ 98 ICBAD_ZONE_10ms_Group20_Reserved3 "ICBAD_ZONE_10ms_Group20_Reserved4";
BA_ "CompuMethodName" SG_ 98 ICBAD_ZONE_10ms_Group20_Reserved4 "ICBAD_ZONE_10ms_Group20_Reserved5";
BA_ "GenSigStartValue" SG_ 98 ICBAD_ZONE_10ms_Group20_Reserved4 15;
BA_ "ISignalName" SG_ 98 ICBAD_ZONE_10ms_Group20_Reserved4 "IICBAD_ZONE_10ms_Group20_Reserved5";
BA_ "SysSignalName" SG_ 98 ICBAD_ZONE_10ms_Group20_Reserved4 "ICBAD_ZONE_10ms_Group20_Reserved5";
BA_ "SystemSignalLongSymbol" SG_ 98 ICBAD_ZONE_10ms_Group20_Reserved4 "ICBAD_ZONE_10ms_Group20_Reserved5";
BA_ "CompuMethodName" SG_ 98 LKAToqReqValMin "LKAToqReqValMin";
BA_ "GenSigStartValue" SG_ 98 LKAToqReqValMin 1024;
BA_ "ISignalName" SG_ 98 LKAToqReqValMin "ILKAToqReqValMin";
BA_ "LongName" SG_ 98 LKAToqReqValMin "Lane Keeping Assist Torque Request Value Minimum";
BA_ "SysSignalName" SG_ 98 LKAToqReqValMin "LKAToqReqValMin";
BA_ "CompuMethodName" SG_ 98 ICBAD_ZONE_10ms_Group20_Reserved5 "ICBAD_ZONE_10ms_Group20_Reserved6";
BA_ "GenSigStartValue" SG_ 98 ICBAD_ZONE_10ms_Group20_Reserved5 31;
BA_ "ISignalName" SG_ 98 ICBAD_ZONE_10ms_Group20_Reserved5 "IICBAD_ZONE_10ms_Group20_Reserved6";
BA_ "SysSignalName" SG_ 98 ICBAD_ZONE_10ms_Group20_Reserved5 "ICBAD_ZONE_10ms_Group20_Reserved6";
BA_ "SystemSignalLongSymbol" SG_ 98 ICBAD_ZONE_10ms_Group20_Reserved5 "ICBAD_ZONE_10ms_Group20_Reserved6";
BA_ "CompuMethodName" SG_ 81 ICBAD_ZONE_20ms_Group13_CRC "ICBAD_ZONE_20ms_Group13_CRC";
BA_ "ISignalName" SG_ 81 ICBAD_ZONE_20ms_Group13_CRC "IICBAD_ZONE_20ms_Group13_CRC";
BA_ "LongName" SG_ 81 ICBAD_ZONE_20ms_Group13_CRC "ICBAD_ZONE_20ms_Group13_CRC";
BA_ "SysSignalName" SG_ 81 ICBAD_ZONE_20ms_Group13_CRC "ICBAD_ZONE_20ms_Group13_CRC";
BA_ "CompuMethodName" SG_ 81 ICBAD_ZONE_20ms_Group13_RC "ICBAD_ZONE_20ms_Group13_RC";
BA_ "ISignalName" SG_ 81 ICBAD_ZONE_20ms_Group13_RC "IICBAD_ZONE_20ms_Group13_RC";
BA_ "LongName" SG_ 81 ICBAD_ZONE_20ms_Group13_RC "ICBAD_ZONE_20ms_Group13_RC";
BA_ "SysSignalName" SG_ 81 ICBAD_ZONE_20ms_Group13_RC "ICBAD_ZONE_20ms_Group13_RC";
BA_ "CompuMethodName" SG_ 81 ICBAD_ZONE_20ms_Group13_Reserved0 "ICBAD_ZONE_20ms_Group13_Reserved1";
BA_ "GenSigStartValue" SG_ 81 ICBAD_ZONE_20ms_Group13_Reserved0 1;
BA_ "ISignalName" SG_ 81 ICBAD_ZONE_20ms_Group13_Reserved0 "IICBAD_ZONE_20ms_Group13_Reserved1";
BA_ "SysSignalName" SG_ 81 ICBAD_ZONE_20ms_Group13_Reserved0 "ICBAD_ZONE_20ms_Group13_Reserved1";
BA_ "SystemSignalLongSymbol" SG_ 81 ICBAD_ZONE_20ms_Group13_Reserved0 "ICBAD_ZONE_20ms_Group13_Reserved1";
BA_ "CompuMethodName" SG_ 81 TJAICASysFltSts "TJAICASysFltSts";
BA_ "ISignalName" SG_ 81 TJAICASysFltSts "ITJAICASysFltSts";
BA_ "LongName" SG_ 81 TJAICASysFltSts "Traffic Jam Assist Integrated Cruise Assist Fault Status";
BA_ "SysSignalName" SG_ 81 TJAICASysFltSts "TJAICASysFltSts";
BA_ "CompuMethodName" SG_ 81 ACCToqReqSts "ACCToqReqSts";
BA_ "ISignalName" SG_ 81 ACCToqReqSts "IACCToqReqSts";
BA_ "SysSignalName" SG_ 81 ACCToqReqSts "ACCToqReqSts";
BA_ "CompuMethodName" SG_ 81 LKASysFltSts "LKASysFltSts";
BA_ "ISignalName" SG_ 81 LKASysFltSts "ILKASysFltSts";
BA_ "LongName" SG_ 81 LKASysFltSts "Lane Keeping Assist System Fault Status";
BA_ "SysSignalName" SG_ 81 LKASysFltSts "LKASysFltSts";
BA_ "CompuMethodName" SG_ 81 ICBAD_ZONE_20ms_Group13_Reserved1 "ICBAD_ZONE_20ms_Group13_Reserved2";
BA_ "GenSigStartValue" SG_ 81 ICBAD_ZONE_20ms_Group13_Reserved1 7;
BA_ "ISignalName" SG_ 81 ICBAD_ZONE_20ms_Group13_Reserved1 "IICBAD_ZONE_20ms_Group13_Reserved2";
BA_ "SysSignalName" SG_ 81 ICBAD_ZONE_20ms_Group13_Reserved1 "ICBAD_ZONE_20ms_Group13_Reserved2";
BA_ "SystemSignalLongSymbol" SG_ 81 ICBAD_ZONE_20ms_Group13_Reserved1 "ICBAD_ZONE_20ms_Group13_Reserved2";
BA_ "CompuMethodName" SG_ 81 ICBAD_ZONE_20ms_Group13_Reserved2 "ICBAD_ZONE_20ms_Group13_Reserved3";
BA_ "GenSigStartValue" SG_ 81 ICBAD_ZONE_20ms_Group13_Reserved2 3;
BA_ "ISignalName" SG_ 81 ICBAD_ZONE_20ms_Group13_Reserved2 "IICBAD_ZONE_20ms_Group13_Reserved3";
BA_ "SysSignalName" SG_ 81 ICBAD_ZONE_20ms_Group13_Reserved2 "ICBAD_ZONE_20ms_Group13_Reserved3";
BA_ "SystemSignalLongSymbol" SG_ 81 ICBAD_ZONE_20ms_Group13_Reserved2 "ICBAD_ZONE_20ms_Group13_Reserved3";
BA_ "CompuMethodName" SG_ 81 TJAICASysSts "TJAICASysSts";
BA_ "ISignalName" SG_ 81 TJAICASysSts "ITJAICASysSts";
BA_ "LongName" SG_ 81 TJAICASysSts "Traffic Jam Assist Integrated Cruise Assist System Status";
BA_ "SysSignalName" SG_ 81 TJAICASysSts "TJAICASysSts";
BA_ "CompuMethodName" SG_ 81 LKASysSts "LKASysSts";
BA_ "ISignalName" SG_ 81 LKASysSts "ILKASysSts";
BA_ "LongName" SG_ 81 LKASysSts "Lane Keeping Assist System Status";
BA_ "SysSignalName" SG_ 81 LKASysSts "LKASysSts";
BA_ "CompuMethodName" SG_ 81 ACCToqReqVal "ACCToqReqVal";
BA_ "GenSigStartValue" SG_ 81 ACCToqReqVal 1696;
BA_ "ISignalName" SG_ 81 ACCToqReqVal "IACCToqReqVal";
BA_ "SysSignalName" SG_ 81 ACCToqReqVal "ACCToqReqVal";
BA_ "CompuMethodName" SG_ 81 ICBAD_ZONE_20ms_Group13_Reserved3 "ICBAD_ZONE_20ms_Group13_Reserved4";
BA_ "GenSigStartValue" SG_ 81 ICBAD_ZONE_20ms_Group13_Reserved3 15;
BA_ "ISignalName" SG_ 81 ICBAD_ZONE_20ms_Group13_Reserved3 "IICBAD_ZONE_20ms_Group13_Reserved4";
BA_ "SysSignalName" SG_ 81 ICBAD_ZONE_20ms_Group13_Reserved3 "ICBAD_ZONE_20ms_Group13_Reserved4";
BA_ "SystemSignalLongSymbol" SG_ 81 ICBAD_ZONE_20ms_Group13_Reserved3 "ICBAD_ZONE_20ms_Group13_Reserved4";
BA_ "CompuMethodName" SG_ 81 ICBAD_ZONE_20ms_Group13_Reserved4 "ICBAD_ZONE_20ms_Group13_Reserved5";
BA_ "GenSigStartValue" SG_ 81 ICBAD_ZONE_20ms_Group13_Reserved4 255;
BA_ "ISignalName" SG_ 81 ICBAD_ZONE_20ms_Group13_Reserved4 "IICBAD_ZONE_20ms_Group13_Reserved5";
BA_ "SysSignalName" SG_ 81 ICBAD_ZONE_20ms_Group13_Reserved4 "ICBAD_ZONE_20ms_Group13_Reserved5";
BA_ "SystemSignalLongSymbol" SG_ 81 ICBAD_ZONE_20ms_Group13_Reserved4 "ICBAD_ZONE_20ms_Group13_Reserved5";
BA_ "CompuMethodName" SG_ 81 ICBAD_ZONE_20ms_Group13_Reserved5 "ICBAD_ZONE_20ms_Group13_Reserved6";
BA_ "GenSigStartValue" SG_ 81 ICBAD_ZONE_20ms_Group13_Reserved5 255;
BA_ "ISignalName" SG_ 81 ICBAD_ZONE_20ms_Group13_Reserved5 "IICBAD_ZONE_20ms_Group13_Reserved6";
BA_ "SysSignalName" SG_ 81 ICBAD_ZONE_20ms_Group13_Reserved5 "ICBAD_ZONE_20ms_Group13_Reserved6";
BA_ "SystemSignalLongSymbol" SG_ 81 ICBAD_ZONE_20ms_Group13_Reserved5 "ICBAD_ZONE_20ms_Group13_Reserved6";
BA_ "CompuMethodName" SG_ 807 TSRTrgtWarnSign "TSRTrgtWarnSign";
BA_ "ISignalName" SG_ 807 TSRTrgtWarnSign "ITSRTrgtWarnSign";
BA_ "LongName" SG_ 807 TSRTrgtWarnSign "Traffic Sign Recognization Target Warning Sign";
BA_ "SysSignalName" SG_ 807 TSRTrgtWarnSign "TSRTrgtWarnSign";
BA_ "CompuMethodName" SG_ 807 SpdAstSysTrgtSpd_IPD "SpdAstSysTrgtSpd_IPD";
BA_ "ISignalName" SG_ 807 SpdAstSysTrgtSpd_IPD "ISpdAstSysTrgtSpd_IPD";
BA_ "LongName" SG_ 807 SpdAstSysTrgtSpd_IPD "Speed_Assist_System_Target_Speed";
BA_ "SysSignalName" SG_ 807 SpdAstSysTrgtSpd_IPD "SpdAstSysTrgtSpd_IPD";
BA_ "CompuMethodName" SG_ 807 TSRTrgtBanSign "TSRTrgtBanSign";
BA_ "ISignalName" SG_ 807 TSRTrgtBanSign "ITSRTrgtBanSign";
BA_ "LongName" SG_ 807 TSRTrgtBanSign "Traffic Sign Recognization Target Ban Sign";
BA_ "SysSignalName" SG_ 807 TSRTrgtBanSign "TSRTrgtBanSign";
BA_ "CompuMethodName" SG_ 807 TSRSwReqResp "TSRSwReqResp";
BA_ "ISignalName" SG_ 807 TSRSwReqResp "ITSRSwReqResp";
BA_ "LongName" SG_ 807 TSRSwReqResp "TSR_Switch_Request_Response";
BA_ "SysSignalName" SG_ 807 TSRSwReqResp "TSRSwReqResp";
BA_ "CompuMethodName" SG_ 807 SLIFSts_IPD "SLIFSts_IPD";
BA_ "ISignalName" SG_ 807 SLIFSts_IPD "ISLIFSts_IPD";
BA_ "LongName" SG_ 807 SLIFSts_IPD "Speed Limit Information Function Status";
BA_ "SysSignalName" SG_ 807 SLIFSts_IPD "SLIFSts_IPD";
BA_ "CompuMethodName" SG_ 807 TSRSts "TSRSts";
BA_ "ISignalName" SG_ 807 TSRSts "ITSRSts";
BA_ "LongName" SG_ 807 TSRSts "Traffic Sign Recognization Function Status";
BA_ "SysSignalName" SG_ 807 TSRSts "TSRSts";
BA_ "CompuMethodName" SG_ 807 PilotSysAVCamrF1FltSts "PilotSysAVCamrF1FltSts";
BA_ "ISignalName" SG_ 807 PilotSysAVCamrF1FltSts "IPilotSysAVCamrF1FltSts";
BA_ "LongName" SG_ 807 PilotSysAVCamrF1FltSts "Pilot System AVCamr_F1 Fault Status";
BA_ "SysSignalName" SG_ 807 PilotSysAVCamrF1FltSts "PilotSysAVCamrF1FltSts";
BA_ "CompuMethodName" SG_ 807 PilotSysADASFltSts "PilotSysADASFltSts";
BA_ "ISignalName" SG_ 807 PilotSysADASFltSts "IPilotSysADASFltSts";
BA_ "LongName" SG_ 807 PilotSysADASFltSts "Pilot System ADAS Fault Status";
BA_ "SysSignalName" SG_ 807 PilotSysADASFltSts "PilotSysADASFltSts";
BA_ "CompuMethodName" SG_ 807 AIParkngSSPLotSwSts "AIParkngSSPLotSwSts";
BA_ "ISignalName" SG_ 807 AIParkngSSPLotSwSts "IAIParkngSSPLotSwSts";
BA_ "LongName" SG_ 807 AIParkngSSPLotSwSts "Ai Parking Silent Search Parking Slot Switch Status";
BA_ "SysSignalName" SG_ 807 AIParkngSSPLotSwSts "AIParkngSSPLotSwSts";
BA_ "CompuMethodName" SG_ 807 PilotSysAVCamrRFltSts "PilotSysAVCamrRFltSts";
BA_ "ISignalName" SG_ 807 PilotSysAVCamrRFltSts "IPilotSysAVCamrRFltSts";
BA_ "LongName" SG_ 807 PilotSysAVCamrRFltSts "Pilot System AVCamr_R Fault Status";
BA_ "SysSignalName" SG_ 807 PilotSysAVCamrRFltSts "PilotSysAVCamrRFltSts";
BA_ "CompuMethodName" SG_ 807 PilotSysAVCamrF3FltSts "PilotSysAVCamrF3FltSts";
BA_ "ISignalName" SG_ 807 PilotSysAVCamrF3FltSts "IPilotSysAVCamrF3FltSts";
BA_ "LongName" SG_ 807 PilotSysAVCamrF3FltSts "Pilot System AVCamr_F3 Fault Status";
BA_ "SysSignalName" SG_ 807 PilotSysAVCamrF3FltSts "PilotSysAVCamrF3FltSts";
BA_ "CompuMethodName" SG_ 807 PilotSysAVCamrFRSFltSts "PilotSysAVCamrFRSFltSts";
BA_ "ISignalName" SG_ 807 PilotSysAVCamrFRSFltSts "IPilotSysAVCamrFRSFltSts";
BA_ "LongName" SG_ 807 PilotSysAVCamrFRSFltSts "Pilot System AVCamr_FRS Fault Status";
BA_ "SysSignalName" SG_ 807 PilotSysAVCamrFRSFltSts "PilotSysAVCamrFRSFltSts";
BA_ "CompuMethodName" SG_ 807 PilotSysAVCamrFLSFltSts "PilotSysAVCamrFLSFltSts";
BA_ "ISignalName" SG_ 807 PilotSysAVCamrFLSFltSts "IPilotSysAVCamrFLSFltSts";
BA_ "LongName" SG_ 807 PilotSysAVCamrFLSFltSts "Pilot System AVCamr_FLS Fault Status";
BA_ "SysSignalName" SG_ 807 PilotSysAVCamrFLSFltSts "PilotSysAVCamrFLSFltSts";
BA_ "CompuMethodName" SG_ 807 PilotSysAVCamrRRSFltSts "PilotSysAVCamrRRSFltSts";
BA_ "ISignalName" SG_ 807 PilotSysAVCamrRRSFltSts "IPilotSysAVCamrRRSFltSts";
BA_ "LongName" SG_ 807 PilotSysAVCamrRRSFltSts "Pilot System AVCamr_RRS Fault Status";
BA_ "SysSignalName" SG_ 807 PilotSysAVCamrRRSFltSts "PilotSysAVCamrRRSFltSts";
BA_ "CompuMethodName" SG_ 807 PilotSysAVCamrRLSFltSts "PilotSysAVCamrRLSFltSts";
BA_ "ISignalName" SG_ 807 PilotSysAVCamrRLSFltSts "IPilotSysAVCamrRLSFltSts";
BA_ "LongName" SG_ 807 PilotSysAVCamrRLSFltSts "Pilot System AVCamr_RLS Fault Status";
BA_ "SysSignalName" SG_ 807 PilotSysAVCamrRLSFltSts "PilotSysAVCamrRLSFltSts";
BA_ "CompuMethodName" SG_ 807 PilotSysHDAVMCamrRFltSts "PilotSysHDAVMCamrRFltSts";
BA_ "ISignalName" SG_ 807 PilotSysHDAVMCamrRFltSts "IPilotSysHDAVMCamrRFltSts";
BA_ "LongName" SG_ 807 PilotSysHDAVMCamrRFltSts "Pilot System HDAVMCamr_R Fault Status";
BA_ "SysSignalName" SG_ 807 PilotSysHDAVMCamrRFltSts "PilotSysHDAVMCamrRFltSts";
BA_ "CompuMethodName" SG_ 807 PilotSysHDAVMCamrFFltSts "PilotSysHDAVMCamrFFltSts";
BA_ "ISignalName" SG_ 807 PilotSysHDAVMCamrFFltSts "IPilotSysHDAVMCamrFFltSts";
BA_ "LongName" SG_ 807 PilotSysHDAVMCamrFFltSts "Pilot System HDAVMCamr_F Fault Status";
BA_ "SysSignalName" SG_ 807 PilotSysHDAVMCamrFFltSts "PilotSysHDAVMCamrFFltSts";
BA_ "CompuMethodName" SG_ 807 PilotSysHDAVMCamrRHFltSts "PilotSysHDAVMCamrRHFltSts";
BA_ "ISignalName" SG_ 807 PilotSysHDAVMCamrRHFltSts "IPilotSysHDAVMCamrRHFltSts";
BA_ "LongName" SG_ 807 PilotSysHDAVMCamrRHFltSts "Pilot System HDAVMCamr_RH Fault Status";
BA_ "SysSignalName" SG_ 807 PilotSysHDAVMCamrRHFltSts "PilotSysHDAVMCamrRHFltSts";
BA_ "CompuMethodName" SG_ 807 PilotSysHDAVMCamrLHFltSts "PilotSysHDAVMCamrLHFltSts";
BA_ "ISignalName" SG_ 807 PilotSysHDAVMCamrLHFltSts "IPilotSysHDAVMCamrLHFltSts";
BA_ "LongName" SG_ 807 PilotSysHDAVMCamrLHFltSts "Pilot System HDAVMCamr_LH Fault Status";
BA_ "SysSignalName" SG_ 807 PilotSysHDAVMCamrLHFltSts "PilotSysHDAVMCamrLHFltSts";
BA_ "CompuMethodName" SG_ 807 SLIFWrnngMdResp "SLIFWrnngMdResp";
BA_ "ISignalName" SG_ 807 SLIFWrnngMdResp "ISLIFWrnngMdResp";
BA_ "LongName" SG_ 807 SLIFWrnngMdResp "Speed Limit Information Function Warning Mode Response";
BA_ "SysSignalName" SG_ 807 SLIFWrnngMdResp "SLIFWrnngMdResp";
BA_ "CompuMethodName" SG_ 807 PilotSysLFSDAFltSts "PilotSysLFSDAFltSts";
BA_ "ISignalName" SG_ 807 PilotSysLFSDAFltSts "IPilotSysLFSDAFltSts";
BA_ "LongName" SG_ 807 PilotSysLFSDAFltSts "Pilot System LFSDA Fault Status";
BA_ "SysSignalName" SG_ 807 PilotSysLFSDAFltSts "PilotSysLFSDAFltSts";
BA_ "CompuMethodName" SG_ 807 PilotSysFDRFltSts "PilotSysFDRFltSts";
BA_ "ISignalName" SG_ 807 PilotSysFDRFltSts "IPilotSysFDRFltSts";
BA_ "LongName" SG_ 807 PilotSysFDRFltSts "Pilot System FDR Fault Status";
BA_ "SysSignalName" SG_ 807 PilotSysFDRFltSts "PilotSysFDRFltSts";
BA_ "CompuMethodName" SG_ 807 TrgtSpdSrcSts_IPD "TrgtSpdSrcSts_IPD";
BA_ "ISignalName" SG_ 807 TrgtSpdSrcSts_IPD "ITrgtSpdSrcSts_IPD";
BA_ "LongName" SG_ 807 TrgtSpdSrcSts_IPD "Target Speed Source Status";
BA_ "SysSignalName" SG_ 807 TrgtSpdSrcSts_IPD "TrgtSpdSrcSts_IPD";
BA_ "CompuMethodName" SG_ 807 PilotSysLHRDAFltSts "PilotSysLHRDAFltSts";
BA_ "ISignalName" SG_ 807 PilotSysLHRDAFltSts "IPilotSysLHRDAFltSts";
BA_ "LongName" SG_ 807 PilotSysLHRDAFltSts "Pilot System LHRDA Fault Status";
BA_ "SysSignalName" SG_ 807 PilotSysLHRDAFltSts "PilotSysLHRDAFltSts";
BA_ "CompuMethodName" SG_ 807 PilotSysRFSDAFltSts "PilotSysRFSDAFltSts";
BA_ "ISignalName" SG_ 807 PilotSysRFSDAFltSts "IPilotSysRFSDAFltSts";
BA_ "LongName" SG_ 807 PilotSysRFSDAFltSts "Pilot System RFSDA Fault Status";
BA_ "SysSignalName" SG_ 807 PilotSysRFSDAFltSts "PilotSysRFSDAFltSts";
BA_ "CompuMethodName" SG_ 807 SLIFAudWrnng_IPD "SLIFAudWrnng_IPD";
BA_ "ISignalName" SG_ 807 SLIFAudWrnng_IPD "ISLIFAudWrnng_IPD";
BA_ "LongName" SG_ 807 SLIFAudWrnng_IPD "Speed Limit Information Function Audible Warning";
BA_ "SysSignalName" SG_ 807 SLIFAudWrnng_IPD "SLIFAudWrnng_IPD";
BA_ "CompuMethodName" SG_ 807 SLIFUpdtInd_IPD "SLIFUpdtInd_IPD";
BA_ "ISignalName" SG_ 807 SLIFUpdtInd_IPD "ISLIFUpdtInd_IPD";
BA_ "LongName" SG_ 807 SLIFUpdtInd_IPD "Speed Limit Information Function Update Indication";
BA_ "SysSignalName" SG_ 807 SLIFUpdtInd_IPD "SLIFUpdtInd_IPD";
BA_ "CompuMethodName" SG_ 807 PilotSysFLIDARFltSts "PilotSysFLIDARFltSts";
BA_ "ISignalName" SG_ 807 PilotSysFLIDARFltSts "IPilotSysFLIDARFltSts";
BA_ "LongName" SG_ 807 PilotSysFLIDARFltSts "Pilot System FLIDAR Fault Status";
BA_ "SysSignalName" SG_ 807 PilotSysFLIDARFltSts "PilotSysFLIDARFltSts";
BA_ "CompuMethodName" SG_ 807 PilotSysRHRDAFltSts "PilotSysRHRDAFltSts";
BA_ "ISignalName" SG_ 807 PilotSysRHRDAFltSts "IPilotSysRHRDAFltSts";
BA_ "LongName" SG_ 807 PilotSysRHRDAFltSts "Pilot System RHRDA Fault Status";
BA_ "SysSignalName" SG_ 807 PilotSysRHRDAFltSts "PilotSysRHRDAFltSts";
BA_ "CompuMethodName" SG_ 807 PilotSysUSSFltSts "PilotSysUSSFltSts";
BA_ "ISignalName" SG_ 807 PilotSysUSSFltSts "IPilotSysUSSFltSts";
BA_ "LongName" SG_ 807 PilotSysUSSFltSts "Pilot System USS Fault Status";
BA_ "SysSignalName" SG_ 807 PilotSysUSSFltSts "PilotSysUSSFltSts";
BA_ "CompuMethodName" SG_ 807 HORWarningEvtSts "HORWarningEvtSts";
BA_ "ISignalName" SG_ 807 HORWarningEvtSts "IHORWarningEvtSts";
BA_ "LongName" SG_ 807 HORWarningEvtSts "HOR Warning Event Status";
BA_ "SysSignalName" SG_ 807 HORWarningEvtSts "HORWarningEvtSts";
BA_ "CompuMethodName" SG_ 807 EORWarningEvtSts "EORWarningEvtSts";
BA_ "ISignalName" SG_ 807 EORWarningEvtSts "IEORWarningEvtSts";
BA_ "LongName" SG_ 807 EORWarningEvtSts "EOR Warning Event Status";
BA_ "SysSignalName" SG_ 807 EORWarningEvtSts "EORWarningEvtSts";
BA_ "CompuMethodName" SG_ 807 PosALCFailed "PosALCFailed";
BA_ "ISignalName" SG_ 807 PosALCFailed "IPosALCFailed";
BA_ "LongName" SG_ 807 PosALCFailed "Positive ALC Failed";
BA_ "SysSignalName" SG_ 807 PosALCFailed "PosALCFailed";
BA_ "CompuMethodName" SG_ 807 SLIFSysFltSts "SLIFSysFltSts";
BA_ "ISignalName" SG_ 807 SLIFSysFltSts "ISLIFSysFltSts";
BA_ "LongName" SG_ 807 SLIFSysFltSts "Speed_Limit_Information_Function_System_Fault_Status";
BA_ "SysSignalName" SG_ 807 SLIFSysFltSts "SLIFSysFltSts";
BA_ "CompuMethodName" SG_ 807 ADS_ISAMsgReq "ADS_ISAMsgReq";
BA_ "ISignalName" SG_ 807 ADS_ISAMsgReq "IADS_ISAMsgReq";
BA_ "LongName" SG_ 807 ADS_ISAMsgReq "ADAS_Intelligence_Speed_Assist _System_Message_Request";
BA_ "SysSignalName" SG_ 807 ADS_ISAMsgReq "ADS_ISAMsgReq";
BA_ "CompuMethodName" SG_ 807 SLIFUpdtIndResp_IPD "SLIFUpdtIndResp_IPD";
BA_ "ISignalName" SG_ 807 SLIFUpdtIndResp_IPD "ISLIFUpdtIndResp_IPD";
BA_ "LongName" SG_ 807 SLIFUpdtIndResp_IPD "Speed Limit Information Function Update Indication Response";
BA_ "SysSignalName" SG_ 807 SLIFUpdtIndResp_IPD "SLIFUpdtIndResp_IPD";
BA_ "CompuMethodName" SG_ 807 ADS_ISASysFltSts "ADS_ISASysFltSts";
BA_ "ISignalName" SG_ 807 ADS_ISASysFltSts "IADS_ISASysFltSts";
BA_ "LongName" SG_ 807 ADS_ISASysFltSts "ADAS_Intelligence_Speed_Assist _System_Fault_Status";
BA_ "SysSignalName" SG_ 807 ADS_ISASysFltSts "ADS_ISASysFltSts";
BA_ "CompuMethodName" SG_ 807 ADS_ISASysSts "ADS_ISASysSts";
BA_ "ISignalName" SG_ 807 ADS_ISASysSts "IADS_ISASysSts";
BA_ "LongName" SG_ 807 ADS_ISASysSts "ADAS_Intelligence_Speed_Assist _System_Status";
BA_ "SysSignalName" SG_ 807 ADS_ISASysSts "ADS_ISASysSts";
BA_ "CompuMethodName" SG_ 807 ParkngSpdSwResp "ParkngSpdSwResp";
BA_ "ISignalName" SG_ 807 ParkngSpdSwResp "IParkngSpdSwResp";
BA_ "LongName" SG_ 807 ParkngSpdSwResp "Parking_Speed_Switch_Response";
BA_ "SysSignalName" SG_ 807 ParkngSpdSwResp "ParkngSpdSwResp";
BA_ "CompuMethodName" SG_ 486 IPD_20ms_Group43_CRC "IPD_20ms_Group43_CRC";
BA_ "ISignalName" SG_ 486 IPD_20ms_Group43_CRC "IIPD_20ms_Group43_CRC";
BA_ "LongName" SG_ 486 IPD_20ms_Group43_CRC "IPD_20ms_Group43_CRC";
BA_ "SysSignalName" SG_ 486 IPD_20ms_Group43_CRC "IPD_20ms_Group43_CRC";
BA_ "CompuMethodName" SG_ 486 IPD_20ms_Group43_RC "IPD_20ms_Group43_RC";
BA_ "ISignalName" SG_ 486 IPD_20ms_Group43_RC "IIPD_20ms_Group43_RC";
BA_ "LongName" SG_ 486 IPD_20ms_Group43_RC "IPD_20ms_Group43_RC";
BA_ "SysSignalName" SG_ 486 IPD_20ms_Group43_RC "IPD_20ms_Group43_RC";
BA_ "CompuMethodName" SG_ 486 IPD_20ms_Group43_Reserved1 "IPD_20ms_Group43_Reserved1";
BA_ "GenSigStartValue" SG_ 486 IPD_20ms_Group43_Reserved1 15;
BA_ "ISignalName" SG_ 486 IPD_20ms_Group43_Reserved1 "IIPD_20ms_Group43_Reserved1";
BA_ "SysSignalName" SG_ 486 IPD_20ms_Group43_Reserved1 "IPD_20ms_Group43_Reserved1";
BA_ "CompuMethodName" SG_ 486 ACCAccReqToqVal "ACCAccReqToqVal";
BA_ "ISignalName" SG_ 486 ACCAccReqToqVal "IACCAccReqToqVal";
BA_ "LongName" SG_ 486 ACCAccReqToqVal "Adaptive Cruise Control Acceleration Request Torque Value";
BA_ "SysSignalName" SG_ 486 ACCAccReqToqVal "ACCAccReqToqVal";
BA_ "CompuMethodName" SG_ 486 IPD_20ms_Group43_Reserved2 "IPD_20ms_Group43_Reserved2";
BA_ "GenSigStartValue" SG_ 486 IPD_20ms_Group43_Reserved2 7;
BA_ "ISignalName" SG_ 486 IPD_20ms_Group43_Reserved2 "IIPD_20ms_Group43_Reserved2";
BA_ "SysSignalName" SG_ 486 IPD_20ms_Group43_Reserved2 "IPD_20ms_Group43_Reserved2";
BA_ "CompuMethodName" SG_ 486 FrtCarGoNotfr "FrtCarGoNotfr";
BA_ "ISignalName" SG_ 486 FrtCarGoNotfr "IFrtCarGoNotfr";
BA_ "LongName" SG_ 486 FrtCarGoNotfr "FrontCar GoNotifier";
BA_ "SysSignalName" SG_ 486 FrtCarGoNotfr "FrtCarGoNotfr";
BA_ "CompuMethodName" SG_ 486 ACCSysFltSts_SCS "ACCSysFltSts_SCS";
BA_ "ISignalName" SG_ 486 ACCSysFltSts_SCS "IACCSysFltSts_SCS";
BA_ "LongName" SG_ 486 ACCSysFltSts_SCS "Adaptive_Cruise_Control_System_Fault_Status";
BA_ "SysSignalName" SG_ 486 ACCSysFltSts_SCS "ACCSysFltSts_SCS";
BA_ "CompuMethodName" SG_ 486 IPD_20ms_Group43_Reserved3 "IPD_20ms_Group43_Reserved3";
BA_ "GenSigStartValue" SG_ 486 IPD_20ms_Group43_Reserved3 255;
BA_ "ISignalName" SG_ 486 IPD_20ms_Group43_Reserved3 "IIPD_20ms_Group43_Reserved3";
BA_ "SysSignalName" SG_ 486 IPD_20ms_Group43_Reserved3 "IPD_20ms_Group43_Reserved3";
BA_ "CompuMethodName" SG_ 486 IPD_20ms_Group43_Reserved4 "IPD_20ms_Group43_Reserved4";
BA_ "GenSigStartValue" SG_ 486 IPD_20ms_Group43_Reserved4 255;
BA_ "ISignalName" SG_ 486 IPD_20ms_Group43_Reserved4 "IIPD_20ms_Group43_Reserved4";
BA_ "SysSignalName" SG_ 486 IPD_20ms_Group43_Reserved4 "IPD_20ms_Group43_Reserved4";
BA_ "CompuMethodName" SG_ 486 IPD_20ms_Group43_Reserved5 "IPD_20ms_Group43_Reserved5";
BA_ "GenSigStartValue" SG_ 486 IPD_20ms_Group43_Reserved5 255;
BA_ "ISignalName" SG_ 486 IPD_20ms_Group43_Reserved5 "IIPD_20ms_Group43_Reserved5";
BA_ "SysSignalName" SG_ 486 IPD_20ms_Group43_Reserved5 "IPD_20ms_Group43_Reserved5";
BA_ "CompuMethodName" SG_ 337 IPD_20ms_Group60_CRC "IPD_20ms_Group60_CRC";
BA_ "ISignalName" SG_ 337 IPD_20ms_Group60_CRC "IIPD_20ms_Group60_CRC";
BA_ "LongName" SG_ 337 IPD_20ms_Group60_CRC "IPD_20ms_Group60_CRC";
BA_ "SysSignalName" SG_ 337 IPD_20ms_Group60_CRC "IPD_20ms_Group60_CRC";
BA_ "CompuMethodName" SG_ 337 IPD_20ms_Group60_RC "IPD_20ms_Group60_RC";
BA_ "ISignalName" SG_ 337 IPD_20ms_Group60_RC "IIPD_20ms_Group60_RC";
BA_ "LongName" SG_ 337 IPD_20ms_Group60_RC "IPD_20ms_Group60_RC";
BA_ "SysSignalName" SG_ 337 IPD_20ms_Group60_RC "IPD_20ms_Group60_RC";
BA_ "CompuMethodName" SG_ 337 AutoLaneChngRLaneSts "AutoLaneChngRLaneSts";
BA_ "ISignalName" SG_ 337 AutoLaneChngRLaneSts "IAutoLaneChngRLaneSts";
BA_ "LongName" SG_ 337 AutoLaneChngRLaneSts "Auto_Lane_Change_Right_Lane_Status";
BA_ "SysSignalName" SG_ 337 AutoLaneChngRLaneSts "AutoLaneChngRLaneSts";
BA_ "CompuMethodName" SG_ 337 IPD_20ms_Group60_Reserved1 "IPD_20ms_Group60_Reserved1";
BA_ "GenSigStartValue" SG_ 337 IPD_20ms_Group60_Reserved1 255;
BA_ "ISignalName" SG_ 337 IPD_20ms_Group60_Reserved1 "IIPD_20ms_Group60_Reserved1";
BA_ "SysSignalName" SG_ 337 IPD_20ms_Group60_Reserved1 "IPD_20ms_Group60_Reserved1";
BA_ "CompuMethodName" SG_ 337 IPD_20ms_Group60_Reserved2 "IPD_20ms_Group60_Reserved2";
BA_ "GenSigStartValue" SG_ 337 IPD_20ms_Group60_Reserved2 255;
BA_ "ISignalName" SG_ 337 IPD_20ms_Group60_Reserved2 "IIPD_20ms_Group60_Reserved2";
BA_ "SysSignalName" SG_ 337 IPD_20ms_Group60_Reserved2 "IPD_20ms_Group60_Reserved2";
BA_ "CompuMethodName" SG_ 337 APASCSToqReqVal "APASCSToqReqVal";
BA_ "ISignalName" SG_ 337 APASCSToqReqVal "IAPASCSToqReqVal";
BA_ "LongName" SG_ 337 APASCSToqReqVal "Advance Park Assist Stability Control System Torque Request Value";
BA_ "SysSignalName" SG_ 337 APASCSToqReqVal "APASCSToqReqVal";
BA_ "CompuMethodName" SG_ 337 APAVehCrdnatPosY "APAVehCrdnatPosY";
BA_ "ISignalName" SG_ 337 APAVehCrdnatPosY "IAPAVehCrdnatPosY";
BA_ "LongName" SG_ 337 APAVehCrdnatPosY "Advanced_Park_Assist_Vehicle_Coordinate_Position_Y";
BA_ "SysSignalName" SG_ 337 APAVehCrdnatPosY "APAVehCrdnatPosY";
BA_ "CompuMethodName" SG_ 337 APAVehCrdnatAzmth "APAVehCrdnatAzmth";
BA_ "ISignalName" SG_ 337 APAVehCrdnatAzmth "IAPAVehCrdnatAzmth";
BA_ "LongName" SG_ 337 APAVehCrdnatAzmth "Advanced_Park_Assist_Vehicle_Coordinate_Azimuth";
BA_ "SysSignalName" SG_ 337 APAVehCrdnatAzmth "APAVehCrdnatAzmth";
BA_ "CompuMethodName" SG_ 337 ESSDirInd "ESSDirInd";
BA_ "ISignalName" SG_ 337 ESSDirInd "IESSDirInd";
BA_ "LongName" SG_ 337 ESSDirInd "Emergency_Steering_System _Direction_Indication";
BA_ "SysSignalName" SG_ 337 ESSDirInd "ESSDirInd";
BA_ "CompuMethodName" SG_ 337 PilotTkovMsgReq "PilotTkovMsgReq";
BA_ "ISignalName" SG_ 337 PilotTkovMsgReq "IPilotTkovMsgReq";
BA_ "LongName" SG_ 337 PilotTkovMsgReq "Pilot Take Over Message Request";
BA_ "SysSignalName" SG_ 337 PilotTkovMsgReq "PilotTkovMsgReq";
BA_ "CompuMethodName" SG_ 337 NOPSysSts_ZPD "NOPSysSts_ZPD";
BA_ "ISignalName" SG_ 337 NOPSysSts_ZPD "INOPSysSts_ZPD";
BA_ "LongName" SG_ 337 NOPSysSts_ZPD "Navigation On Pilot System Status";
BA_ "SysSignalName" SG_ 337 NOPSysSts_ZPD "NOPSysSts_ZPD";
BA_ "CompuMethodName" SG_ 337 PrkgDstCtrlSwResp "PrkgDstCtrlSwResp";
BA_ "GenSigStartValue" SG_ 337 PrkgDstCtrlSwResp 1;
BA_ "ISignalName" SG_ 337 PrkgDstCtrlSwResp "IPrkgDstCtrlSwResp";
BA_ "LongName" SG_ 337 PrkgDstCtrlSwResp "Parking Distance Ctrl Switch Response";
BA_ "SysSignalName" SG_ 337 PrkgDstCtrlSwResp "PrkgDstCtrlSwResp";
BA_ "CompuMethodName" SG_ 337 ALCSysSts "ALCSysSts";
BA_ "ISignalName" SG_ 337 ALCSysSts "IALCSysSts";
BA_ "LongName" SG_ 337 ALCSysSts "Auto_Lane_Change_System_Status";
BA_ "SysSignalName" SG_ 337 ALCSysSts "ALCSysSts";
BA_ "CompuMethodName" SG_ 337 ALCSysFltSts "ALCSysFltSts";
BA_ "ISignalName" SG_ 337 ALCSysFltSts "IALCSysFltSts";
BA_ "LongName" SG_ 337 ALCSysFltSts "ALC System Failure Status";
BA_ "SysSignalName" SG_ 337 ALCSysFltSts "ALCSysFltSts";
BA_ "CompuMethodName" SG_ 337 APAVehCrdnatPosX "APAVehCrdnatPosX";
BA_ "ISignalName" SG_ 337 APAVehCrdnatPosX "IAPAVehCrdnatPosX";
BA_ "LongName" SG_ 337 APAVehCrdnatPosX "Advanced_Park_Assist_Vehicle_Coordinate_Position_X";
BA_ "SysSignalName" SG_ 337 APAVehCrdnatPosX "APAVehCrdnatPosX";
BA_ "CompuMethodName" SG_ 337 AutoLaneChngLLaneSts "AutoLaneChngLLaneSts";
BA_ "ISignalName" SG_ 337 AutoLaneChngLLaneSts "IAutoLaneChngLLaneSts";
BA_ "LongName" SG_ 337 AutoLaneChngLLaneSts "Auto_Lane_Change_Left_Lane_Status";
BA_ "SysSignalName" SG_ 337 AutoLaneChngLLaneSts "AutoLaneChngLLaneSts";
BA_ "CompuMethodName" SG_ 337 IPD_20ms_Group60_Reserved4 "IPD_20ms_Group60_Reserved4";
BA_ "GenSigStartValue" SG_ 337 IPD_20ms_Group60_Reserved4 3;
BA_ "ISignalName" SG_ 337 IPD_20ms_Group60_Reserved4 "IIPD_20ms_Group60_Reserved4";
BA_ "SysSignalName" SG_ 337 IPD_20ms_Group60_Reserved4 "IPD_20ms_Group60_Reserved4";
BA_ "CompuMethodName" SG_ 337 ESSSysSts "ESSSysSts";
BA_ "GenSigStartValue" SG_ 337 ESSSysSts 1;
BA_ "ISignalName" SG_ 337 ESSSysSts "IESSSysSts";
BA_ "LongName" SG_ 337 ESSSysSts "Emergency_Steering_System_Status";
BA_ "SysSignalName" SG_ 337 ESSSysSts "ESSSysSts";
BA_ "CompuMethodName" SG_ 337 ESSSysFltSts "ESSSysFltSts";
BA_ "ISignalName" SG_ 337 ESSSysFltSts "IESSSysFltSts";
BA_ "LongName" SG_ 337 ESSSysFltSts "Emergency_Steering_System_Fault_Status";
BA_ "SysSignalName" SG_ 337 ESSSysFltSts "ESSSysFltSts";
BA_ "CompuMethodName" SG_ 337 IPD_20ms_Group60_Reserved6 "IPD_20ms_Group60_Reserved6";
BA_ "GenSigStartValue" SG_ 337 IPD_20ms_Group60_Reserved6 1;
BA_ "ISignalName" SG_ 337 IPD_20ms_Group60_Reserved6 "IIPD_20ms_Group60_Reserved6";
BA_ "SysSignalName" SG_ 337 IPD_20ms_Group60_Reserved6 "IPD_20ms_Group60_Reserved6";
BA_ "CompuMethodName" SG_ 337 ESSDrvrTkovReq "ESSDrvrTkovReq";
BA_ "ISignalName" SG_ 337 ESSDrvrTkovReq "IESSDrvrTkovReq";
BA_ "LongName" SG_ 337 ESSDrvrTkovReq "Emergency_Steering_System_Takeover_Request";
BA_ "SysSignalName" SG_ 337 ESSDrvrTkovReq "ESSDrvrTkovReq";
BA_ "CompuMethodName" SG_ 337 IPD_20ms_Group60_Reserved5 "IPD_20ms_Group60_Reserved5";
BA_ "GenSigStartValue" SG_ 337 IPD_20ms_Group60_Reserved5 7;
BA_ "ISignalName" SG_ 337 IPD_20ms_Group60_Reserved5 "IIPD_20ms_Group60_Reserved5";
BA_ "SysSignalName" SG_ 337 IPD_20ms_Group60_Reserved5 "IPD_20ms_Group60_Reserved5";
BA_ "CompuMethodName" SG_ 337 Parkngslottype "Parkngslottype";
BA_ "ISignalName" SG_ 337 Parkngslottype "IParkngslottype";
BA_ "LongName" SG_ 337 Parkngslottype "Parking Slot Type";
BA_ "SysSignalName" SG_ 337 Parkngslottype "Parkngslottype";
BA_ "CompuMethodName" SG_ 337 IPD_20ms_Group60_Reserved7 "IPD_20ms_Group60_Reserved7";
BA_ "GenSigStartValue" SG_ 337 IPD_20ms_Group60_Reserved7 31;
BA_ "ISignalName" SG_ 337 IPD_20ms_Group60_Reserved7 "IIPD_20ms_Group60_Reserved7";
BA_ "SysSignalName" SG_ 337 IPD_20ms_Group60_Reserved7 "IPD_20ms_Group60_Reserved7";
BA_ "CompuMethodName" SG_ 337 NOPSysFltSts "NOPSysFltSts";
BA_ "ISignalName" SG_ 337 NOPSysFltSts "INOPSysFltSts";
BA_ "LongName" SG_ 337 NOPSysFltSts "Nop System Failure Status";
BA_ "SysSignalName" SG_ 337 NOPSysFltSts "NOPSysFltSts";
BA_ "CompuMethodName" SG_ 337 IPD_20ms_Group60_Reserved8 "IPD_20ms_Group60_Reserved8";
BA_ "GenSigStartValue" SG_ 337 IPD_20ms_Group60_Reserved8 255;
BA_ "ISignalName" SG_ 337 IPD_20ms_Group60_Reserved8 "IIPD_20ms_Group60_Reserved8";
BA_ "SysSignalName" SG_ 337 IPD_20ms_Group60_Reserved8 "IPD_20ms_Group60_Reserved8";
BA_ "CompuMethodName" SG_ 337 IPD_20ms_Group60_Reserved9 "IPD_20ms_Group60_Reserved9";
BA_ "GenSigStartValue" SG_ 337 IPD_20ms_Group60_Reserved9 255;
BA_ "ISignalName" SG_ 337 IPD_20ms_Group60_Reserved9 "IIPD_20ms_Group60_Reserved9";
BA_ "SysSignalName" SG_ 337 IPD_20ms_Group60_Reserved9 "IPD_20ms_Group60_Reserved9";
BA_ "CompuMethodName" SG_ 337 IPD_20ms_Group60_Reserved10 "IPD_20ms_Group60_Reserved10";
BA_ "GenSigStartValue" SG_ 337 IPD_20ms_Group60_Reserved10 255;
BA_ "ISignalName" SG_ 337 IPD_20ms_Group60_Reserved10 "IIPD_20ms_Group60_Reserved10";
BA_ "SysSignalName" SG_ 337 IPD_20ms_Group60_Reserved10 "IPD_20ms_Group60_Reserved10";
BA_ "CompuMethodName" SG_ 337 IPD_20ms_Group60_Reserved11 "IPD_20ms_Group60_Reserved11";
BA_ "GenSigStartValue" SG_ 337 IPD_20ms_Group60_Reserved11 255;
BA_ "ISignalName" SG_ 337 IPD_20ms_Group60_Reserved11 "IIPD_20ms_Group60_Reserved11";
BA_ "SysSignalName" SG_ 337 IPD_20ms_Group60_Reserved11 "IPD_20ms_Group60_Reserved11";
BA_ "CompuMethodName" SG_ 733 IPD_50ms_Group49_CRC "IPD_50ms_Group49_CRC";
BA_ "ISignalName" SG_ 733 IPD_50ms_Group49_CRC "IIPD_50ms_Group49_CRC";
BA_ "SysSignalName" SG_ 733 IPD_50ms_Group49_CRC "IPD_50ms_Group49_CRC";
BA_ "CompuMethodName" SG_ 733 IPD_50ms_Group49_RC "IPD_50ms_Group49_RC";
BA_ "ISignalName" SG_ 733 IPD_50ms_Group49_RC "IIPD_50ms_Group49_RC";
BA_ "SysSignalName" SG_ 733 IPD_50ms_Group49_RC "IPD_50ms_Group49_RC";
BA_ "CompuMethodName" SG_ 733 KeepPwrRsnIPD "KeepPwrRsnIPD";
BA_ "ISignalName" SG_ 733 KeepPwrRsnIPD "IKeepPwrRsnIPD";
BA_ "LongName" SG_ 733 KeepPwrRsnIPD "Keep Power Reason IPD";
BA_ "SysSignalName" SG_ 733 KeepPwrRsnIPD "KeepPwrRsnIPD";
BA_ "CompuMethodName" SG_ 733 IPD_50ms_Group49_Reserved1 "IPD_50ms_Group49_Reserved1";
BA_ "GenSigStartValue" SG_ 733 IPD_50ms_Group49_Reserved1 31;
BA_ "ISignalName" SG_ 733 IPD_50ms_Group49_Reserved1 "IIPD_50ms_Group49_Reserved1";
BA_ "SysSignalName" SG_ 733 IPD_50ms_Group49_Reserved1 "IPD_50ms_Group49_Reserved1";
BA_ "CompuMethodName" SG_ 733 SysPwrMdCtrl "SysPwrMdCtrl";
BA_ "ISignalName" SG_ 733 SysPwrMdCtrl "ISysPwrMdCtrl";
BA_ "LongName" SG_ 733 SysPwrMdCtrl "System power mode control";
BA_ "SysSignalName" SG_ 733 SysPwrMdCtrl "SysPwrMdCtrl";
BA_ "CompuMethodName" SG_ 733 APAEnRunReq "APAEnRunReq";
BA_ "ISignalName" SG_ 733 APAEnRunReq "IAPAEnRunReq";
BA_ "LongName" SG_ 733 APAEnRunReq "Advanced Park Assist Engine Run Request";
BA_ "SysSignalName" SG_ 733 APAEnRunReq "APAEnRunReq";
BA_ "CompuMethodName" SG_ 733 IPD_50ms_Group49_Reserved2 "IPD_50ms_Group49_Reserved2";
BA_ "GenSigStartValue" SG_ 733 IPD_50ms_Group49_Reserved2 127;
BA_ "ISignalName" SG_ 733 IPD_50ms_Group49_Reserved2 "IIPD_50ms_Group49_Reserved2";
BA_ "SysSignalName" SG_ 733 IPD_50ms_Group49_Reserved2 "IPD_50ms_Group49_Reserved2";
BA_ "CompuMethodName" SG_ 733 IPD_50ms_Group49_Reserved3 "IPD_50ms_Group49_Reserved3";
BA_ "GenSigStartValue" SG_ 733 IPD_50ms_Group49_Reserved3 255;
BA_ "ISignalName" SG_ 733 IPD_50ms_Group49_Reserved3 "IIPD_50ms_Group49_Reserved3";
BA_ "SysSignalName" SG_ 733 IPD_50ms_Group49_Reserved3 "IPD_50ms_Group49_Reserved3";
BA_ "CompuMethodName" SG_ 733 IPD_50ms_Group49_Reserved4 "IPD_50ms_Group49_Reserved4";
BA_ "GenSigStartValue" SG_ 733 IPD_50ms_Group49_Reserved4 15;
BA_ "ISignalName" SG_ 733 IPD_50ms_Group49_Reserved4 "IIPD_50ms_Group49_Reserved4";
BA_ "SysSignalName" SG_ 733 IPD_50ms_Group49_Reserved4 "IPD_50ms_Group49_Reserved4";
BA_ "CompuMethodName" SG_ 733 LADSAFnInd "LADSAFnInd";
BA_ "ISignalName" SG_ 733 LADSAFnInd "ILADSAFnInd";
BA_ "LongName" SG_ 733 LADSAFnInd "Advanced Park Assist Active Function Indication";
BA_ "SysSignalName" SG_ 733 LADSAFnInd "LADSAFnInd";
BA_ "CompuMethodName" SG_ 733 IPD_50ms_Group49_Reserved5 "IPD_50ms_Group49_Reserved5";
BA_ "GenSigStartValue" SG_ 733 IPD_50ms_Group49_Reserved5 255;
BA_ "ISignalName" SG_ 733 IPD_50ms_Group49_Reserved5 "IIPD_50ms_Group49_Reserved5";
BA_ "SysSignalName" SG_ 733 IPD_50ms_Group49_Reserved5 "IPD_50ms_Group49_Reserved5";
BA_ "CompuMethodName" SG_ 733 IPD_50ms_Group49_Reserved6 "IPD_50ms_Group49_Reserved6";
BA_ "GenSigStartValue" SG_ 733 IPD_50ms_Group49_Reserved6 255;
BA_ "ISignalName" SG_ 733 IPD_50ms_Group49_Reserved6 "IIPD_50ms_Group49_Reserved6";
BA_ "SysSignalName" SG_ 733 IPD_50ms_Group49_Reserved6 "IPD_50ms_Group49_Reserved6";
BA_ "CompuMethodName" SG_ 590 RoadProfileShockDistL1 "RoadProfileShockDistL1";
BA_ "ISignalName" SG_ 590 RoadProfileShockDistL1 "IRoadProfileShockDistL1";
BA_ "LongName" SG_ 590 RoadProfileShockDistL1 "Distance To The Leading Edge Of The First Shock Feature Along The Rolling Path L";
BA_ "SysSignalName" SG_ 590 RoadProfileShockDistL1 "RoadProfileShockDistL1";
BA_ "CompuMethodName" SG_ 590 RoadProfileShockDistL2 "RoadProfileShockDistL2";
BA_ "ISignalName" SG_ 590 RoadProfileShockDistL2 "IRoadProfileShockDistL2";
BA_ "LongName" SG_ 590 RoadProfileShockDistL2 "Distance To The Leading Edge Of The Second Shock Feature Along The Rolling Path L";
BA_ "SysSignalName" SG_ 590 RoadProfileShockDistL2 "RoadProfileShockDistL2";
BA_ "CompuMethodName" SG_ 590 RoadProfileShockDetectedL1 "RoadProfileShockDetectedL1";
BA_ "ISignalName" SG_ 590 RoadProfileShockDetectedL1 "IRoadProfileShockDetectedL1";
BA_ "LongName" SG_ 590 RoadProfileShockDetectedL1 "An Indication That A Shock Feature Has Been Detected_L_1";
BA_ "SysSignalName" SG_ 590 RoadProfileShockDetectedL1 "RoadProfileShockDetectedL1";
BA_ "CompuMethodName" SG_ 590 RoadProfileShockDistL3 "RoadProfileShockDistL3";
BA_ "ISignalName" SG_ 590 RoadProfileShockDistL3 "IRoadProfileShockDistL3";
BA_ "LongName" SG_ 590 RoadProfileShockDistL3 "Distance To The Leading Edge Of The Third Shock Feature Along The Rolling Path L";
BA_ "SysSignalName" SG_ 590 RoadProfileShockDistL3 "RoadProfileShockDistL3";
BA_ "CompuMethodName" SG_ 590 RoadProfileShockDistR1 "RoadProfileShockDistR1";
BA_ "ISignalName" SG_ 590 RoadProfileShockDistR1 "IRoadProfileShockDistR1";
BA_ "LongName" SG_ 590 RoadProfileShockDistR1 "Distance To The Leading Edge Of The First Shock Feature Along The Rolling Path R";
BA_ "SysSignalName" SG_ 590 RoadProfileShockDistR1 "RoadProfileShockDistR1";
BA_ "CompuMethodName" SG_ 590 RoadProfileShockDetectedL2 "RoadProfileShockDetectedL2";
BA_ "ISignalName" SG_ 590 RoadProfileShockDetectedL2 "IRoadProfileShockDetectedL2";
BA_ "LongName" SG_ 590 RoadProfileShockDetectedL2 "An Indication That A Shock Feature Has Been Detected_L_2";
BA_ "SysSignalName" SG_ 590 RoadProfileShockDetectedL2 "RoadProfileShockDetectedL2";
BA_ "CompuMethodName" SG_ 590 RoadProfileShockDistR2 "RoadProfileShockDistR2";
BA_ "ISignalName" SG_ 590 RoadProfileShockDistR2 "IRoadProfileShockDistR2";
BA_ "LongName" SG_ 590 RoadProfileShockDistR2 "Distance To The Leading Edge Of The Second Shock Feature Along The Rolling Path R";
BA_ "SysSignalName" SG_ 590 RoadProfileShockDistR2 "RoadProfileShockDistR2";
BA_ "CompuMethodName" SG_ 590 RoadProfileShockDistR3 "RoadProfileShockDistR3";
BA_ "ISignalName" SG_ 590 RoadProfileShockDistR3 "IRoadProfileShockDistR3";
BA_ "LongName" SG_ 590 RoadProfileShockDistR3 "Distance To The Leading Edge Of The Third Shock Feature Along The Rolling Path R";
BA_ "SysSignalName" SG_ 590 RoadProfileShockDistR3 "RoadProfileShockDistR3";
BA_ "CompuMethodName" SG_ 590 RoadProfileShockDetectedL3 "RoadProfileShockDetectedL3";
BA_ "ISignalName" SG_ 590 RoadProfileShockDetectedL3 "IRoadProfileShockDetectedL3";
BA_ "LongName" SG_ 590 RoadProfileShockDetectedL3 "An Indication That A Shock Feature Has Been Detected_L_3";
BA_ "SysSignalName" SG_ 590 RoadProfileShockDetectedL3 "RoadProfileShockDetectedL3";
BA_ "CompuMethodName" SG_ 590 RoadProfileShockHeightL1 "RoadProfileShockHeightL1";
BA_ "ISignalName" SG_ 590 RoadProfileShockHeightL1 "IRoadProfileShockHeightL1";
BA_ "LongName" SG_ 590 RoadProfileShockHeightL1 "The Height Of The Shock Feature_L_1";
BA_ "SysSignalName" SG_ 590 RoadProfileShockHeightL1 "RoadProfileShockHeightL1";
BA_ "CompuMethodName" SG_ 590 RoadProfileShockConfidenceL1 "RoadProfileShockConfidenceL1";
BA_ "ISignalName" SG_ 590 RoadProfileShockConfidenceL1 "IRoadProfileShockConfidenceL1";
BA_ "LongName" SG_ 590 RoadProfileShockConfidenceL1 "The Confidence Of The Shock Detection_L_1";
BA_ "SysSignalName" SG_ 590 RoadProfileShockConfidenceL1 "RoadProfileShockConfidenceL1";
BA_ "CompuMethodName" SG_ 590 RoadProfileShockHeightL2 "RoadProfileShockHeightL2";
BA_ "ISignalName" SG_ 590 RoadProfileShockHeightL2 "IRoadProfileShockHeightL2";
BA_ "LongName" SG_ 590 RoadProfileShockHeightL2 "The Height Of The Shock Feature_L_2";
BA_ "SysSignalName" SG_ 590 RoadProfileShockHeightL2 "RoadProfileShockHeightL2";
BA_ "CompuMethodName" SG_ 590 RoadProfileShockConfidenceL2 "RoadProfileShockConfidenceL2";
BA_ "ISignalName" SG_ 590 RoadProfileShockConfidenceL2 "IRoadProfileShockConfidenceL2";
BA_ "LongName" SG_ 590 RoadProfileShockConfidenceL2 "The Confidence Of The Shock Detection_L_2";
BA_ "SysSignalName" SG_ 590 RoadProfileShockConfidenceL2 "RoadProfileShockConfidenceL2";
BA_ "CompuMethodName" SG_ 590 RoadProfileShockHeightL3 "RoadProfileShockHeightL3";
BA_ "ISignalName" SG_ 590 RoadProfileShockHeightL3 "IRoadProfileShockHeightL3";
BA_ "LongName" SG_ 590 RoadProfileShockHeightL3 "The Height Of The Shock Feature_L_3";
BA_ "SysSignalName" SG_ 590 RoadProfileShockHeightL3 "RoadProfileShockHeightL3";
BA_ "CompuMethodName" SG_ 590 RoadProfileShockConfidenceL3 "RoadProfileShockConfidenceL3";
BA_ "ISignalName" SG_ 590 RoadProfileShockConfidenceL3 "IRoadProfileShockConfidenceL3";
BA_ "LongName" SG_ 590 RoadProfileShockConfidenceL3 "The Confidence Of The Shock Detection_L_3";
BA_ "SysSignalName" SG_ 590 RoadProfileShockConfidenceL3 "RoadProfileShockConfidenceL3";
BA_ "CompuMethodName" SG_ 590 RoadProfileShockHeightR1 "RoadProfileShockHeightR1";
BA_ "ISignalName" SG_ 590 RoadProfileShockHeightR1 "IRoadProfileShockHeightR1";
BA_ "LongName" SG_ 590 RoadProfileShockHeightR1 "The Height Of The Shock Feature_R_1";
BA_ "SysSignalName" SG_ 590 RoadProfileShockHeightR1 "RoadProfileShockHeightR1";
BA_ "CompuMethodName" SG_ 590 RoadProfileShockConfidenceR1 "RoadProfileShockConfidenceR1";
BA_ "ISignalName" SG_ 590 RoadProfileShockConfidenceR1 "IRoadProfileShockConfidenceR1";
BA_ "LongName" SG_ 590 RoadProfileShockConfidenceR1 "The Confidence Of The Shock Detection_R_1";
BA_ "SysSignalName" SG_ 590 RoadProfileShockConfidenceR1 "RoadProfileShockConfidenceR1";
BA_ "CompuMethodName" SG_ 590 RoadProfileShockHeightR2 "RoadProfileShockHeightR2";
BA_ "ISignalName" SG_ 590 RoadProfileShockHeightR2 "IRoadProfileShockHeightR2";
BA_ "LongName" SG_ 590 RoadProfileShockHeightR2 "The Height Of The Shock Feature_R_2";
BA_ "SysSignalName" SG_ 590 RoadProfileShockHeightR2 "RoadProfileShockHeightR2";
BA_ "CompuMethodName" SG_ 590 RoadProfileShockConfidenceR2 "RoadProfileShockConfidenceR2";
BA_ "ISignalName" SG_ 590 RoadProfileShockConfidenceR2 "IRoadProfileShockConfidenceR2";
BA_ "LongName" SG_ 590 RoadProfileShockConfidenceR2 "The Confidence Of The Shock Detection_R_2";
BA_ "SysSignalName" SG_ 590 RoadProfileShockConfidenceR2 "RoadProfileShockConfidenceR2";
BA_ "CompuMethodName" SG_ 590 RoadProfileShockHeightR3 "RoadProfileShockHeightR3";
BA_ "ISignalName" SG_ 590 RoadProfileShockHeightR3 "IRoadProfileShockHeightR3";
BA_ "LongName" SG_ 590 RoadProfileShockHeightR3 "The Height Of The Shock Feature_R_3";
BA_ "SysSignalName" SG_ 590 RoadProfileShockHeightR3 "RoadProfileShockHeightR3";
BA_ "CompuMethodName" SG_ 590 RoadProfileShockConfidenceR3 "RoadProfileShockConfidenceR3";
BA_ "ISignalName" SG_ 590 RoadProfileShockConfidenceR3 "IRoadProfileShockConfidenceR3";
BA_ "LongName" SG_ 590 RoadProfileShockConfidenceR3 "The Confidence Of The Shock Detection_R_3";
BA_ "SysSignalName" SG_ 590 RoadProfileShockConfidenceR3 "RoadProfileShockConfidenceR3";
BA_ "CompuMethodName" SG_ 590 RoadHeightL "RoadHeightL";
BA_ "ISignalName" SG_ 590 RoadHeightL "IRoadHeightL";
BA_ "LongName" SG_ 590 RoadHeightL "The Height Of road Feature L";
BA_ "SysSignalName" SG_ 590 RoadHeightL "RoadHeightL";
BA_ "CompuMethodName" SG_ 590 PrvOutSts "PrvOutSts";
BA_ "ISignalName" SG_ 590 PrvOutSts "IPrvOutSts";
BA_ "LongName" SG_ 590 PrvOutSts "Preview_Output_status";
BA_ "SysSignalName" SG_ 590 PrvOutSts "PrvOutSts";
BA_ "CompuMethodName" SG_ 590 RoadProfileShockDetectedR1 "RoadProfileShockDetectedR1";
BA_ "ISignalName" SG_ 590 RoadProfileShockDetectedR1 "IRoadProfileShockDetectedR1";
BA_ "LongName" SG_ 590 RoadProfileShockDetectedR1 "An Indication That A Shock Feature Has Been Detected_R_1";
BA_ "SysSignalName" SG_ 590 RoadProfileShockDetectedR1 "RoadProfileShockDetectedR1";
BA_ "CompuMethodName" SG_ 590 RoadHeightR "RoadHeightR";
BA_ "ISignalName" SG_ 590 RoadHeightR "IRoadHeightR";
BA_ "LongName" SG_ 590 RoadHeightR "The Height Of road Feature R";
BA_ "SysSignalName" SG_ 590 RoadHeightR "RoadHeightR";
BA_ "CompuMethodName" SG_ 590 RoadProfileShockDetectedR3 "RoadProfileShockDetectedR3";
BA_ "ISignalName" SG_ 590 RoadProfileShockDetectedR3 "IRoadProfileShockDetectedR3";
BA_ "LongName" SG_ 590 RoadProfileShockDetectedR3 "An Indication That A Shock Feature Has Been Detected_R_3";
BA_ "SysSignalName" SG_ 590 RoadProfileShockDetectedR3 "RoadProfileShockDetectedR3";
BA_ "CompuMethodName" SG_ 590 RoadProfileShockDetectedR2 "RoadProfileShockDetectedR2";
BA_ "ISignalName" SG_ 590 RoadProfileShockDetectedR2 "IRoadProfileShockDetectedR2";
BA_ "LongName" SG_ 590 RoadProfileShockDetectedR2 "An Indication That A Shock Feature Has Been Detected_R_2";
BA_ "SysSignalName" SG_ 590 RoadProfileShockDetectedR2 "RoadProfileShockDetectedR2";
BA_ "CompuMethodName" SG_ 1202 IPD_NM_BSMtoRMS_CHCANFD "IPD_NM_BSMtoRMS_CHCANFD";
BA_ "ISignalName" SG_ 1202 IPD_NM_BSMtoRMS_CHCANFD "IIPD_NM_BSMtoRMS_CHCANFD";
BA_ "LongName" SG_ 1202 IPD_NM_BSMtoRMS_CHCANFD "IPD_NM_BSMtoRMS_CHCANFD";
BA_ "SysSignalName" SG_ 1202 IPD_NM_BSMtoRMS_CHCANFD "IPD_NM_BSMtoRMS_CHCANFD";
BA_ "CompuMethodName" SG_ 1202 IPD_NM_PBSMtoRMS_CHCANFD "IPD_NM_PBSMtoRMS_CHCANFD";
BA_ "ISignalName" SG_ 1202 IPD_NM_PBSMtoRMS_CHCANFD "IIPD_NM_PBSMtoRMS_CHCANFD";
BA_ "LongName" SG_ 1202 IPD_NM_PBSMtoRMS_CHCANFD "IPD_NM_PBSMtoRMS_CHCANFD";
BA_ "SysSignalName" SG_ 1202 IPD_NM_PBSMtoRMS_CHCANFD "IPD_NM_PBSMtoRMS_CHCANFD";
BA_ "CompuMethodName" SG_ 1202 IPD_NM_RMStoNOS_CHCANFD "IPD_NM_RMStoNOS_CHCANFD";
BA_ "ISignalName" SG_ 1202 IPD_NM_RMStoNOS_CHCANFD "IIPD_NM_RMStoNOS_CHCANFD";
BA_ "LongName" SG_ 1202 IPD_NM_RMStoNOS_CHCANFD "IPD_NM_RMStoNOS_CHCANFD";
BA_ "SysSignalName" SG_ 1202 IPD_NM_RMStoNOS_CHCANFD "IPD_NM_RMStoNOS_CHCANFD";
BA_ "CompuMethodName" SG_ 1202 IPD_NM_RSStoNOS_CHCANFD "IPD_NM_RSStoNOS_CHCANFD";
BA_ "ISignalName" SG_ 1202 IPD_NM_RSStoNOS_CHCANFD "IIPD_NM_RSStoNOS_CHCANFD";
BA_ "LongName" SG_ 1202 IPD_NM_RSStoNOS_CHCANFD "IPD_NM_RSStoNOS_CHCANFD";
BA_ "SysSignalName" SG_ 1202 IPD_NM_RSStoNOS_CHCANFD "IPD_NM_RSStoNOS_CHCANFD";
BA_ "CompuMethodName" SG_ 1202 IPD_NM_RSStoRMS_CHCANFD "IPD_NM_RSStoRMS_CHCANFD";
BA_ "ISignalName" SG_ 1202 IPD_NM_RSStoRMS_CHCANFD "IIPD_NM_RSStoRMS_CHCANFD";
BA_ "LongName" SG_ 1202 IPD_NM_RSStoRMS_CHCANFD "IPD_NM_RSStoRMS_CHCANFD";
BA_ "SysSignalName" SG_ 1202 IPD_NM_RSStoRMS_CHCANFD "IPD_NM_RSStoRMS_CHCANFD";
BA_ "CompuMethodName" SG_ 1202 IPD_NM_NOStoRMS_CHCANFD "IPD_NM_NOStoRMS_CHCANFD";
BA_ "ISignalName" SG_ 1202 IPD_NM_NOStoRMS_CHCANFD "IIPD_NM_NOStoRMS_CHCANFD";
BA_ "LongName" SG_ 1202 IPD_NM_NOStoRMS_CHCANFD "IPD_NM_NOStoRMS_CHCANFD";
BA_ "SysSignalName" SG_ 1202 IPD_NM_NOStoRMS_CHCANFD "IPD_NM_NOStoRMS_CHCANFD";
BA_ "CompuMethodName" SG_ 1202 IPD_NM_NOSSta_CHCANFD "IPD_NM_NOSSta_CHCANFD";
BA_ "ISignalName" SG_ 1202 IPD_NM_NOSSta_CHCANFD "IIPD_NM_NOSSta_CHCANFD";
BA_ "LongName" SG_ 1202 IPD_NM_NOSSta_CHCANFD "IPD_NM_NOSSta_CHCANFD";
BA_ "SysSignalName" SG_ 1202 IPD_NM_NOSSta_CHCANFD "IPD_NM_NOSSta_CHCANFD";
BA_ "CompuMethodName" SG_ 1202 IPD_NM_RMSSta_CHCANFD "IPD_NM_RMSSta_CHCANFD";
BA_ "ISignalName" SG_ 1202 IPD_NM_RMSSta_CHCANFD "IIPD_NM_RMSSta_CHCANFD";
BA_ "LongName" SG_ 1202 IPD_NM_RMSSta_CHCANFD "IPD_NM_RMSSta_CHCANFD";
BA_ "SysSignalName" SG_ 1202 IPD_NM_RMSSta_CHCANFD "IPD_NM_RMSSta_CHCANFD";
BA_ "CompuMethodName" SG_ 1202 IPD_NWI_CHCANFD "IPD_NWI_CHCANFD";
BA_ "ISignalName" SG_ 1202 IPD_NWI_CHCANFD "IIPD_NWI_CHCANFD";
BA_ "LongName" SG_ 1202 IPD_NWI_CHCANFD "IPD CHCANFD Network_Wakeup_Indication";
BA_ "SysSignalName" SG_ 1202 IPD_NWI_CHCANFD "IPD_NWI_CHCANFD";
BA_ "CompuMethodName" SG_ 1202 IPD_NOI_CHCANFD "IPD_NOI_CHCANFD";
BA_ "ISignalName" SG_ 1202 IPD_NOI_CHCANFD "IIPD_NOI_CHCANFD";
BA_ "LongName" SG_ 1202 IPD_NOI_CHCANFD "IPD CHCANFD Network Operation Indication";
BA_ "SysSignalName" SG_ 1202 IPD_NOI_CHCANFD "IPD_NOI_CHCANFD";
BA_ "CompuMethodName" SG_ 1202 IPD_NKI_CHCANFD "IPD_NKI_CHCANFD";
BA_ "ISignalName" SG_ 1202 IPD_NKI_CHCANFD "IIPD_NKI_CHCANFD";
BA_ "LongName" SG_ 1202 IPD_NKI_CHCANFD "IPD CHCANFD Network Keep Indication";
BA_ "SysSignalName" SG_ 1202 IPD_NKI_CHCANFD "IPD_NKI_CHCANFD";
BA_ "CompuMethodName" SG_ 1267 RZCU_NM_BSMtoRMS_CHCANFD "RZCU_NM_BSMtoRMS_CHCANFD";
BA_ "ISignalName" SG_ 1267 RZCU_NM_BSMtoRMS_CHCANFD "IRZCU_NM_BSMtoRMS_CHCANFD";
BA_ "SysSignalName" SG_ 1267 RZCU_NM_BSMtoRMS_CHCANFD "RZCU_NM_BSMtoRMS_CHCANFD";
BA_ "CompuMethodName" SG_ 1267 RZCU_NM_PBSMtoRMS_CHCANFD "RZCU_NM_PBSMtoRMS_CHCANFD";
BA_ "ISignalName" SG_ 1267 RZCU_NM_PBSMtoRMS_CHCANFD "IRZCU_NM_PBSMtoRMS_CHCANFD";
BA_ "SysSignalName" SG_ 1267 RZCU_NM_PBSMtoRMS_CHCANFD "RZCU_NM_PBSMtoRMS_CHCANFD";
BA_ "CompuMethodName" SG_ 1267 RZCU_NM_RMStoNOS_CHCANFD "RZCU_NM_RMStoNOS_CHCANFD";
BA_ "ISignalName" SG_ 1267 RZCU_NM_RMStoNOS_CHCANFD "IRZCU_NM_RMStoNOS_CHCANFD";
BA_ "SysSignalName" SG_ 1267 RZCU_NM_RMStoNOS_CHCANFD "RZCU_NM_RMStoNOS_CHCANFD";
BA_ "CompuMethodName" SG_ 1267 RZCU_NM_RSStoNOS_CHCANFD "RZCU_NM_RSStoNOS_CHCANFD";
BA_ "ISignalName" SG_ 1267 RZCU_NM_RSStoNOS_CHCANFD "IRZCU_NM_RSStoNOS_CHCANFD";
BA_ "SysSignalName" SG_ 1267 RZCU_NM_RSStoNOS_CHCANFD "RZCU_NM_RSStoNOS_CHCANFD";
BA_ "CompuMethodName" SG_ 1267 RZCU_NM_RSStoRMS_CHCANFD "RZCU_NM_RSStoRMS_CHCANFD";
BA_ "ISignalName" SG_ 1267 RZCU_NM_RSStoRMS_CHCANFD "IRZCU_NM_RSStoRMS_CHCANFD";
BA_ "SysSignalName" SG_ 1267 RZCU_NM_RSStoRMS_CHCANFD "RZCU_NM_RSStoRMS_CHCANFD";
BA_ "CompuMethodName" SG_ 1267 RZCU_NM_NOStoRMS_CHCANFD "RZCU_NM_NOStoRMS_CHCANFD";
BA_ "ISignalName" SG_ 1267 RZCU_NM_NOStoRMS_CHCANFD "IRZCU_NM_NOStoRMS_CHCANFD";
BA_ "SysSignalName" SG_ 1267 RZCU_NM_NOStoRMS_CHCANFD "RZCU_NM_NOStoRMS_CHCANFD";
BA_ "CompuMethodName" SG_ 1267 RZCU_NM_NOSSta_CHCANFD "RZCU_NM_NOSSta_CHCANFD";
BA_ "ISignalName" SG_ 1267 RZCU_NM_NOSSta_CHCANFD "IRZCU_NM_NOSSta_CHCANFD";
BA_ "SysSignalName" SG_ 1267 RZCU_NM_NOSSta_CHCANFD "RZCU_NM_NOSSta_CHCANFD";
BA_ "CompuMethodName" SG_ 1267 RZCU_NM_RMSSta_CHCANFD "RZCU_NM_RMSSta_CHCANFD";
BA_ "ISignalName" SG_ 1267 RZCU_NM_RMSSta_CHCANFD "IRZCU_NM_RMSSta_CHCANFD";
BA_ "SysSignalName" SG_ 1267 RZCU_NM_RMSSta_CHCANFD "RZCU_NM_RMSSta_CHCANFD";
BA_ "CompuMethodName" SG_ 1267 RZCU_NWI_CHCANFD "RZCU_NWI_CHCANFD";
BA_ "ISignalName" SG_ 1267 RZCU_NWI_CHCANFD "IRZCU_NWI_CHCANFD";
BA_ "LongName" SG_ 1267 RZCU_NWI_CHCANFD "RZCU CHCANFD Network_Wakeup_Indication";
BA_ "SysSignalName" SG_ 1267 RZCU_NWI_CHCANFD "RZCU_NWI_CHCANFD";
BA_ "CompuMethodName" SG_ 1267 RZCU_NOI_CHCANFD "RZCU_NOI_CHCANFD";
BA_ "ISignalName" SG_ 1267 RZCU_NOI_CHCANFD "IRZCU_NOI_CHCANFD";
BA_ "SysSignalName" SG_ 1267 RZCU_NOI_CHCANFD "RZCU_NOI_CHCANFD";
BA_ "CompuMethodName" SG_ 1267 RZCU_NKI_CHCANFD "RZCU_NKI_CHCANFD";
BA_ "ISignalName" SG_ 1267 RZCU_NKI_CHCANFD "IRZCU_NKI_CHCANFD";
BA_ "LongName" SG_ 1267 RZCU_NKI_CHCANFD "RZCU CHCANFD Network Keep Indication";
BA_ "SysSignalName" SG_ 1267 RZCU_NKI_CHCANFD "RZCU_NKI_CHCANFD";
BA_ "CompuMethodName" SG_ 143 RZCU_ZONE_10ms_Group64_CRC "RZCU_ZONE_10ms_Group64_CRC";
BA_ "ISignalName" SG_ 143 RZCU_ZONE_10ms_Group64_CRC "IRZCU_ZONE_10ms_Group64_CRC";
BA_ "SysSignalName" SG_ 143 RZCU_ZONE_10ms_Group64_CRC "RZCU_ZONE_10ms_Group64_CRC";
BA_ "CompuMethodName" SG_ 143 RZCU_ZONE_10ms_Group64_RC "RZCU_ZONE_10ms_Group64_RC";
BA_ "ISignalName" SG_ 143 RZCU_ZONE_10ms_Group64_RC "IRZCU_ZONE_10ms_Group64_RC";
BA_ "SysSignalName" SG_ 143 RZCU_ZONE_10ms_Group64_RC "RZCU_ZONE_10ms_Group64_RC";
BA_ "CompuMethodName" SG_ 143 AngularRateXsecinfoV "AngularRateXsecinfoV";
BA_ "ISignalName" SG_ 143 AngularRateXsecinfoV "IAngularRateXsecinfoV";
BA_ "LongName" SG_ 143 AngularRateXsecinfoV "Angularrate_X Valid";
BA_ "SysSignalName" SG_ 143 AngularRateXsecinfoV "AngularRateXsecinfoV";
BA_ "CompuMethodName" SG_ 143 AccelerationZsecinfoV "AccelerationZsecinfoV";
BA_ "ISignalName" SG_ 143 AccelerationZsecinfoV "IAccelerationZsecinfoV";
BA_ "LongName" SG_ 143 AccelerationZsecinfoV "Acceleration_Z Valid";
BA_ "SysSignalName" SG_ 143 AccelerationZsecinfoV "AccelerationZsecinfoV";
BA_ "CompuMethodName" SG_ 143 AccelerationYsecinfoV "AccelerationYsecinfoV";
BA_ "ISignalName" SG_ 143 AccelerationYsecinfoV "IAccelerationYsecinfoV";
BA_ "LongName" SG_ 143 AccelerationYsecinfoV "Acceleration_Y Valid";
BA_ "SysSignalName" SG_ 143 AccelerationYsecinfoV "AccelerationYsecinfoV";
BA_ "CompuMethodName" SG_ 143 AccelerationXsecinfoV "AccelerationXsecinfoV";
BA_ "ISignalName" SG_ 143 AccelerationXsecinfoV "IAccelerationXsecinfoV";
BA_ "LongName" SG_ 143 AccelerationXsecinfoV "Acceleration_X Valid";
BA_ "SysSignalName" SG_ 143 AccelerationXsecinfoV "AccelerationXsecinfoV";
BA_ "CompuMethodName" SG_ 143 AccelerationXsecinfo "AccelerationXsecinfo";
BA_ "ISignalName" SG_ 143 AccelerationXsecinfo "IAccelerationXsecinfo";
BA_ "LongName" SG_ 143 AccelerationXsecinfo "Acceleration_X";
BA_ "SysSignalName" SG_ 143 AccelerationXsecinfo "AccelerationXsecinfo";
BA_ "CompuMethodName" SG_ 143 AccelerationYsecinfo "AccelerationYsecinfo";
BA_ "ISignalName" SG_ 143 AccelerationYsecinfo "IAccelerationYsecinfo";
BA_ "LongName" SG_ 143 AccelerationYsecinfo "Acceleration_Y";
BA_ "SysSignalName" SG_ 143 AccelerationYsecinfo "AccelerationYsecinfo";
BA_ "CompuMethodName" SG_ 143 AccelerationZsecinfo "AccelerationZsecinfo";
BA_ "ISignalName" SG_ 143 AccelerationZsecinfo "IAccelerationZsecinfo";
BA_ "LongName" SG_ 143 AccelerationZsecinfo "Acceleration_Z";
BA_ "SysSignalName" SG_ 143 AccelerationZsecinfo "AccelerationZsecinfo";
BA_ "CompuMethodName" SG_ 143 AngularRateXsecinfo "AngularRateXsecinfo";
BA_ "ISignalName" SG_ 143 AngularRateXsecinfo "IAngularRateXsecinfo";
BA_ "LongName" SG_ 143 AngularRateXsecinfo "Angularrate_X";
BA_ "SysSignalName" SG_ 143 AngularRateXsecinfo "AngularRateXsecinfo";
BA_ "CompuMethodName" SG_ 143 AngularRateYsecinfo "AngularRateYsecinfo";
BA_ "ISignalName" SG_ 143 AngularRateYsecinfo "IAngularRateYsecinfo";
BA_ "LongName" SG_ 143 AngularRateYsecinfo "Angularrate_Y";
BA_ "SysSignalName" SG_ 143 AngularRateYsecinfo "AngularRateYsecinfo";
BA_ "CompuMethodName" SG_ 143 AngularRateZsecinfo "AngularRateZsecinfo";
BA_ "ISignalName" SG_ 143 AngularRateZsecinfo "IAngularRateZsecinfo";
BA_ "LongName" SG_ 143 AngularRateZsecinfo "Angularrate_Z";
BA_ "SysSignalName" SG_ 143 AngularRateZsecinfo "AngularRateZsecinfo";
BA_ "CompuMethodName" SG_ 143 IMUTmp "IMUTmp";
BA_ "ISignalName" SG_ 143 IMUTmp "IIMUTmp";
BA_ "LongName" SG_ 143 IMUTmp "IMU Temperature";
BA_ "SysSignalName" SG_ 143 IMUTmp "IMUTmp";
BA_ "CompuMethodName" SG_ 143 TireBlowoutStabCtrlSts "TireBlowoutStabCtrlSts";
BA_ "ISignalName" SG_ 143 TireBlowoutStabCtrlSts "ITireBlowoutStabCtrlSts";
BA_ "LongName" SG_ 143 TireBlowoutStabCtrlSts "Tire_Blowout_Stability_Control_Status";
BA_ "SysSignalName" SG_ 143 TireBlowoutStabCtrlSts "TireBlowoutStabCtrlSts";
BA_ "CompuMethodName" SG_ 143 AngularRateZsecinfoV "AngularRateZsecinfoV";
BA_ "ISignalName" SG_ 143 AngularRateZsecinfoV "IAngularRateZsecinfoV";
BA_ "LongName" SG_ 143 AngularRateZsecinfoV "Angularrate_Z Valid";
BA_ "SysSignalName" SG_ 143 AngularRateZsecinfoV "AngularRateZsecinfoV";
BA_ "CompuMethodName" SG_ 143 AngularRateYsecinfoV "AngularRateYsecinfoV";
BA_ "ISignalName" SG_ 143 AngularRateYsecinfoV "IAngularRateYsecinfoV";
BA_ "LongName" SG_ 143 AngularRateYsecinfoV "Angularrate_Y Valid";
BA_ "SysSignalName" SG_ 143 AngularRateYsecinfoV "AngularRateYsecinfoV";
BA_ "CompuMethodName" SG_ 143 IMUseq "IMUseq";
BA_ "ISignalName" SG_ 143 IMUseq "IIMUseq";
BA_ "LongName" SG_ 143 IMUseq "Imu Messages Sequence";
BA_ "SysSignalName" SG_ 143 IMUseq "IMUseq";
BA_ "CompuMethodName" SG_ 143 RZCU_ZONE_10ms_Group64_Reserved1 "RZCU_ZONE_10ms_Group64_Reserved1";
BA_ "GenSigStartValue" SG_ 143 RZCU_ZONE_10ms_Group64_Reserved1 15;
BA_ "ISignalName" SG_ 143 RZCU_ZONE_10ms_Group64_Reserved1 "IRZCU_ZONE_10ms_Group64_Reserved1";
BA_ "SysSignalName" SG_ 143 RZCU_ZONE_10ms_Group64_Reserved1 "RZCU_ZONE_10ms_Group64_Reserved1";
BA_ "CompuMethodName" SG_ 143 TireBlowoutPos "TireBlowoutPos";
BA_ "ISignalName" SG_ 143 TireBlowoutPos "ITireBlowoutPos";
BA_ "LongName" SG_ 143 TireBlowoutPos "Tire_Blowout_Position";
BA_ "SysSignalName" SG_ 143 TireBlowoutPos "TireBlowoutPos";
BA_ "CompuMethodName" SG_ 143 RZCU_ZONE_10ms_Group64_Reserved2 "RZCU_ZONE_10ms_Group64_Reserved2";
BA_ "GenSigStartValue" SG_ 143 RZCU_ZONE_10ms_Group64_Reserved2 255;
BA_ "ISignalName" SG_ 143 RZCU_ZONE_10ms_Group64_Reserved2 "IRZCU_ZONE_10ms_Group64_Reserved2";
BA_ "SysSignalName" SG_ 143 RZCU_ZONE_10ms_Group64_Reserved2 "RZCU_ZONE_10ms_Group64_Reserved2";
BA_ "CompuMethodName" SG_ 143 RZCU_ZONE_10ms_Group64_Reserved3 "RZCU_ZONE_10ms_Group64_Reserved3";
BA_ "GenSigStartValue" SG_ 143 RZCU_ZONE_10ms_Group64_Reserved3 255;
BA_ "ISignalName" SG_ 143 RZCU_ZONE_10ms_Group64_Reserved3 "IRZCU_ZONE_10ms_Group64_Reserved3";
BA_ "SysSignalName" SG_ 143 RZCU_ZONE_10ms_Group64_Reserved3 "RZCU_ZONE_10ms_Group64_Reserved3";
BA_ "CompuMethodName" SG_ 143 RZCU_ZONE_10ms_Group64_Reserved4 "RZCU_ZONE_10ms_Group64_Reserved4";
BA_ "GenSigStartValue" SG_ 143 RZCU_ZONE_10ms_Group64_Reserved4 255;
BA_ "ISignalName" SG_ 143 RZCU_ZONE_10ms_Group64_Reserved4 "IRZCU_ZONE_10ms_Group64_Reserved4";
BA_ "SysSignalName" SG_ 143 RZCU_ZONE_10ms_Group64_Reserved4 "RZCU_ZONE_10ms_Group64_Reserved4";
BA_ "CompuMethodName" SG_ 143 RZCU_ZONE_10ms_Group64_Reserved5 "RZCU_ZONE_10ms_Group64_Reserved5";
BA_ "GenSigStartValue" SG_ 143 RZCU_ZONE_10ms_Group64_Reserved5 255;
BA_ "ISignalName" SG_ 143 RZCU_ZONE_10ms_Group64_Reserved5 "IRZCU_ZONE_10ms_Group64_Reserved5";
BA_ "SysSignalName" SG_ 143 RZCU_ZONE_10ms_Group64_Reserved5 "RZCU_ZONE_10ms_Group64_Reserved5";
BA_ "CompuMethodName" SG_ 143 RZCU_ZONE_10ms_Group64_Reserved6 "RZCU_ZONE_10ms_Group64_Reserved6";
BA_ "GenSigStartValue" SG_ 143 RZCU_ZONE_10ms_Group64_Reserved6 255;
BA_ "ISignalName" SG_ 143 RZCU_ZONE_10ms_Group64_Reserved6 "IRZCU_ZONE_10ms_Group64_Reserved6";
BA_ "SysSignalName" SG_ 143 RZCU_ZONE_10ms_Group64_Reserved6 "RZCU_ZONE_10ms_Group64_Reserved6";
BA_ "CompuMethodName" SG_ 1216 ZXD_NM_BSMtoRMS_CHCANFD "ZXD_NM_BSMtoRMS_CHCANFD";
BA_ "ISignalName" SG_ 1216 ZXD_NM_BSMtoRMS_CHCANFD "IZXD_NM_BSMtoRMS_CHCANFD";
BA_ "LongName" SG_ 1216 ZXD_NM_BSMtoRMS_CHCANFD "ZXD_NM_BSMtoRMS_CHCANFD";
BA_ "SysSignalName" SG_ 1216 ZXD_NM_BSMtoRMS_CHCANFD "ZXD_NM_BSMtoRMS_CHCANFD";
BA_ "CompuMethodName" SG_ 1216 ZXD_NM_PBSMtoRMS_CHCANFD "ZXD_NM_PBSMtoRMS_CHCANFD";
BA_ "ISignalName" SG_ 1216 ZXD_NM_PBSMtoRMS_CHCANFD "IZXD_NM_PBSMtoRMS_CHCANFD";
BA_ "LongName" SG_ 1216 ZXD_NM_PBSMtoRMS_CHCANFD "ZXD_NM_PBSMtoRMS_CHCANFD";
BA_ "SysSignalName" SG_ 1216 ZXD_NM_PBSMtoRMS_CHCANFD "ZXD_NM_PBSMtoRMS_CHCANFD";
BA_ "CompuMethodName" SG_ 1216 ZXD_NM_RMStoNOS_CHCANFD "ZXD_NM_RMStoNOS_CHCANFD";
BA_ "ISignalName" SG_ 1216 ZXD_NM_RMStoNOS_CHCANFD "IZXD_NM_RMStoNOS_CHCANFD";
BA_ "LongName" SG_ 1216 ZXD_NM_RMStoNOS_CHCANFD "ZXD_NM_RMStoNOS_CHCANFD";
BA_ "SysSignalName" SG_ 1216 ZXD_NM_RMStoNOS_CHCANFD "ZXD_NM_RMStoNOS_CHCANFD";
BA_ "CompuMethodName" SG_ 1216 ZXD_NM_RSStoNOS_CHCANFD "ZXD_NM_RSStoNOS_CHCANFD";
BA_ "ISignalName" SG_ 1216 ZXD_NM_RSStoNOS_CHCANFD "IZXD_NM_RSStoNOS_CHCANFD";
BA_ "LongName" SG_ 1216 ZXD_NM_RSStoNOS_CHCANFD "ZXD_NM_RSStoNOS_CHCANFD";
BA_ "SysSignalName" SG_ 1216 ZXD_NM_RSStoNOS_CHCANFD "ZXD_NM_RSStoNOS_CHCANFD";
BA_ "CompuMethodName" SG_ 1216 ZXD_NM_RSStoRMS_CHCANFD "ZXD_NM_RSStoRMS_CHCANFD";
BA_ "ISignalName" SG_ 1216 ZXD_NM_RSStoRMS_CHCANFD "IZXD_NM_RSStoRMS_CHCANFD";
BA_ "LongName" SG_ 1216 ZXD_NM_RSStoRMS_CHCANFD "ZXD_NM_RSStoRMS_CHCANFD";
BA_ "SysSignalName" SG_ 1216 ZXD_NM_RSStoRMS_CHCANFD "ZXD_NM_RSStoRMS_CHCANFD";
BA_ "CompuMethodName" SG_ 1216 ZXD_NM_NOStoRMS_CHCANFD "ZXD_NM_NOStoRMS_CHCANFD";
BA_ "ISignalName" SG_ 1216 ZXD_NM_NOStoRMS_CHCANFD "IZXD_NM_NOStoRMS_CHCANFD";
BA_ "LongName" SG_ 1216 ZXD_NM_NOStoRMS_CHCANFD "ZXD_NM_NOStoRMS_CHCANFD";
BA_ "SysSignalName" SG_ 1216 ZXD_NM_NOStoRMS_CHCANFD "ZXD_NM_NOStoRMS_CHCANFD";
BA_ "CompuMethodName" SG_ 1216 ZXD_NM_NOSSta_CHCANFD "ZXD_NM_NOSSta_CHCANFD";
BA_ "ISignalName" SG_ 1216 ZXD_NM_NOSSta_CHCANFD "IZXD_NM_NOSSta_CHCANFD";
BA_ "LongName" SG_ 1216 ZXD_NM_NOSSta_CHCANFD "ZXD_NM_NOSSta_CHCANFD";
BA_ "SysSignalName" SG_ 1216 ZXD_NM_NOSSta_CHCANFD "ZXD_NM_NOSSta_CHCANFD";
BA_ "CompuMethodName" SG_ 1216 ZXD_NM_RMSSta_CHCANFD "ZXD_NM_RMSSta_CHCANFD";
BA_ "ISignalName" SG_ 1216 ZXD_NM_RMSSta_CHCANFD "IZXD_NM_RMSSta_CHCANFD";
BA_ "LongName" SG_ 1216 ZXD_NM_RMSSta_CHCANFD "ZXD_NM_RMSSta_CHCANFD";
BA_ "SysSignalName" SG_ 1216 ZXD_NM_RMSSta_CHCANFD "ZXD_NM_RMSSta_CHCANFD";
BA_ "CompuMethodName" SG_ 1216 ZXD_NWI_CHCANFD "ZXD_NWI_CHCANFD";
BA_ "ISignalName" SG_ 1216 ZXD_NWI_CHCANFD "IZXD_NWI_CHCANFD";
BA_ "LongName" SG_ 1216 ZXD_NWI_CHCANFD "ZXD CHCANFD Network_Wakeup_Indication";
BA_ "SysSignalName" SG_ 1216 ZXD_NWI_CHCANFD "ZXD_NWI_CHCANFD";
BA_ "CompuMethodName" SG_ 1216 ZXD_NOI_CHCANFD "ZXD_NOI_CHCANFD";
BA_ "ISignalName" SG_ 1216 ZXD_NOI_CHCANFD "IZXD_NOI_CHCANFD";
BA_ "LongName" SG_ 1216 ZXD_NOI_CHCANFD "ZXD CHCANFD Network Operation Indication";
BA_ "SysSignalName" SG_ 1216 ZXD_NOI_CHCANFD "ZXD_NOI_CHCANFD";
BA_ "CompuMethodName" SG_ 1216 ZXD_NKI_CHCANFD "ZXD_NKI_CHCANFD";
BA_ "ISignalName" SG_ 1216 ZXD_NKI_CHCANFD "IZXD_NKI_CHCANFD";
BA_ "LongName" SG_ 1216 ZXD_NKI_CHCANFD "ZXD CHCANFD Network Keep Indication";
BA_ "SysSignalName" SG_ 1216 ZXD_NKI_CHCANFD "ZXD_NKI_CHCANFD";
BA_ "CompuMethodName" SG_ 2164461571 EPS_010ms_Group03_CRC "EPS_010ms_Group03_CRC";
BA_ "ISignalName" SG_ 2164461571 EPS_010ms_Group03_CRC "IEPS_010ms_Group03_CRC";
BA_ "LongName" SG_ 2164461571 EPS_010ms_Group03_CRC "EPS_010ms_Group03_CRC";
BA_ "SysSignalName" SG_ 2164461571 EPS_010ms_Group03_CRC "EPS_010ms_Group03_CRC";
BA_ "CompuMethodName" SG_ 2164461571 EPS_010ms_Group03_RC "EPS_010ms_Group03_RC";
BA_ "ISignalName" SG_ 2164461571 EPS_010ms_Group03_RC "IEPS_010ms_Group03_RC";
BA_ "LongName" SG_ 2164461571 EPS_010ms_Group03_RC "EPS_010ms_Group03_RC";
BA_ "SysSignalName" SG_ 2164461571 EPS_010ms_Group03_RC "EPS_010ms_Group03_RC";
BA_ "CompuMethodName" SG_ 2164461571 EPSAESReqResp "EPSAESReqResp";
BA_ "ISignalName" SG_ 2164461571 EPSAESReqResp "IEPSAESReqResp";
BA_ "LongName" SG_ 2164461571 EPSAESReqResp "Steering_AES_Request_Response";
BA_ "SysSignalName" SG_ 2164461571 EPSAESReqResp "EPSAESReqResp";
BA_ "CompuMethodName" SG_ 2164461571 EPSAESStsInh "EPSAESStsInh";
BA_ "ISignalName" SG_ 2164461571 EPSAESStsInh "IEPSAESStsInh";
BA_ "LongName" SG_ 2164461571 EPSAESStsInh "Electric_Power_Steering_AES_Request_Response_Inhibit_Reason";
BA_ "SysSignalName" SG_ 2164461571 EPSAESStsInh "EPSAESStsInh";
BA_ "CompuMethodName" SG_ 2164461571 EPSAESReqTorResp "EPSAESReqTorResp";
BA_ "GenSigStartValue" SG_ 2164461571 EPSAESReqTorResp 1024;
BA_ "ISignalName" SG_ 2164461571 EPSAESReqTorResp "IEPSAESReqTorResp";
BA_ "LongName" SG_ 2164461571 EPSAESReqTorResp "Electric_Power_Steering_AES_Request_Torque_Response";
BA_ "SysSignalName" SG_ 2164461571 EPSAESReqTorResp "EPSAESReqTorResp";
BA_ "CompuMethodName" SG_ 2164461571 EPS_010ms_Group03_Reserved1 "EPS_010ms_Group03_Reserved1";
BA_ "GenSigStartValue" SG_ 2164461571 EPS_010ms_Group03_Reserved1 1;
BA_ "ISignalName" SG_ 2164461571 EPS_010ms_Group03_Reserved1 "IEPS_010ms_Group03_Reserved1";
BA_ "SysSignalName" SG_ 2164461571 EPS_010ms_Group03_Reserved1 "EPS_010ms_Group03_Reserved1";
BA_ "CompuMethodName" SG_ 2164461571 EPSVMCAngRespSts "EPSVMCAngRespSts";
BA_ "ISignalName" SG_ 2164461571 EPSVMCAngRespSts "IEPSVMCAngRespSts";
BA_ "LongName" SG_ 2164461571 EPSVMCAngRespSts "Electric_Power_Steering_VMC_Angle_Response_Status";
BA_ "SysSignalName" SG_ 2164461571 EPSVMCAngRespSts "EPSVMCAngRespSts";
BA_ "CompuMethodName" SG_ 2164461571 EPSAESReqTorRespV "EPSAESReqTorRespV";
BA_ "ISignalName" SG_ 2164461571 EPSAESReqTorRespV "IEPSAESReqTorRespV";
BA_ "LongName" SG_ 2164461571 EPSAESReqTorRespV "Electric_Power_Steering_AES_Request_Torque_Response_Validity";
BA_ "SysSignalName" SG_ 2164461571 EPSAESReqTorRespV "EPSAESReqTorRespV";
BA_ "CompuMethodName" SG_ 2164461571 EPSVMCRespStsInh "EPSVMCRespStsInh";
BA_ "ISignalName" SG_ 2164461571 EPSVMCRespStsInh "IEPSVMCRespStsInh";
BA_ "LongName" SG_ 2164461571 EPSVMCRespStsInh "Electric_Power_Steering_VMC_Request_Response_Inhibit_Reason";
BA_ "SysSignalName" SG_ 2164461571 EPSVMCRespStsInh "EPSVMCRespStsInh";
BA_ "CompuMethodName" SG_ 2164461571 EPS_010ms_Group03_Reserved2 "EPS_010ms_Group03_Reserved2";
BA_ "GenSigStartValue" SG_ 2164461571 EPS_010ms_Group03_Reserved2 63;
BA_ "ISignalName" SG_ 2164461571 EPS_010ms_Group03_Reserved2 "IEPS_010ms_Group03_Reserved2";
BA_ "SysSignalName" SG_ 2164461571 EPS_010ms_Group03_Reserved2 "EPS_010ms_Group03_Reserved2";
BA_ "CompuMethodName" SG_ 2164461571 EPSVMCCodrivingSts "EPSVMCCodrivingSts";
BA_ "ISignalName" SG_ 2164461571 EPSVMCCodrivingSts "IEPSVMCCodrivingSts";
BA_ "LongName" SG_ 2164461571 EPSVMCCodrivingSts "Electric_Power_Steering_VMC_Codriving_Status";
BA_ "SysSignalName" SG_ 2164461571 EPSVMCCodrivingSts "EPSVMCCodrivingSts";
BA_ "CompuMethodName" SG_ 2164461571 EPS_010ms_Group03_Reserved3 "EPS_010ms_Group03_Reserved3";
BA_ "GenSigStartValue" SG_ 2164461571 EPS_010ms_Group03_Reserved3 255;
BA_ "ISignalName" SG_ 2164461571 EPS_010ms_Group03_Reserved3 "IEPS_010ms_Group03_Reserved3";
BA_ "SysSignalName" SG_ 2164461571 EPS_010ms_Group03_Reserved3 "EPS_010ms_Group03_Reserved3";
BA_ "CompuMethodName" SG_ 2164729093 EPS_10ms_Group01_CRC "EPS_10ms_Group01_CRC";
BA_ "ISignalName" SG_ 2164729093 EPS_10ms_Group01_CRC "IEPS_10ms_Group01_CRC";
BA_ "LongName" SG_ 2164729093 EPS_10ms_Group01_CRC "EPS_10ms_Group01_CRC";
BA_ "SysSignalName" SG_ 2164729093 EPS_10ms_Group01_CRC "EPS_10ms_Group01_CRC";
BA_ "CompuMethodName" SG_ 2164729093 EPS_10ms_Group01_RC "EPS_10ms_Group01_RC";
BA_ "ISignalName" SG_ 2164729093 EPS_10ms_Group01_RC "IEPS_10ms_Group01_RC";
BA_ "LongName" SG_ 2164729093 EPS_10ms_Group01_RC "EPS_10ms_Group01_RC";
BA_ "SysSignalName" SG_ 2164729093 EPS_10ms_Group01_RC "EPS_10ms_Group01_RC";
BA_ "CompuMethodName" SG_ 2164729093 ActuRoadWhlAngV "ActuRoadWhlAngV";
BA_ "ISignalName" SG_ 2164729093 ActuRoadWhlAngV "IActuRoadWhlAngV";
BA_ "LongName" SG_ 2164729093 ActuRoadWhlAngV "Actual Road Wheel Angle Validity";
BA_ "SysSignalName" SG_ 2164729093 ActuRoadWhlAngV "ActuRoadWhlAngV";
BA_ "CompuMethodName" SG_ 2164729093 ADASStrgDlvrdToqV "ADASStrgDlvrdToqV";
BA_ "ISignalName" SG_ 2164729093 ADASStrgDlvrdToqV "IADASStrgDlvrdToqV";
BA_ "LongName" SG_ 2164729093 ADASStrgDlvrdToqV "Advanced Driver Assistance System Steering Delivered Torque Validity";
BA_ "SysSignalName" SG_ 2164729093 ADASStrgDlvrdToqV "ADASStrgDlvrdToqV";
BA_ "CompuMethodName" SG_ 2164729093 EPSDrvngMdCtrlInh "EPSDrvngMdCtrlInh";
BA_ "GenSigStartValue" SG_ 2164729093 EPSDrvngMdCtrlInh 1;
BA_ "ISignalName" SG_ 2164729093 EPSDrvngMdCtrlInh "IEPSDrvngMdCtrlInh";
BA_ "LongName" SG_ 2164729093 EPSDrvngMdCtrlInh "Electric Power Steering Driving Mode Control Inhibit";
BA_ "SysSignalName" SG_ 2164729093 EPSDrvngMdCtrlInh "EPSDrvngMdCtrlInh";
BA_ "CompuMethodName" SG_ 2164729093 DrvrStrgDlvrdToqV "DrvrStrgDlvrdToqV";
BA_ "ISignalName" SG_ 2164729093 DrvrStrgDlvrdToqV "IDrvrStrgDlvrdToqV";
BA_ "LongName" SG_ 2164729093 DrvrStrgDlvrdToqV "Driver Steering Delivered Torque Validity";
BA_ "SysSignalName" SG_ 2164729093 DrvrStrgDlvrdToqV "DrvrStrgDlvrdToqV";
BA_ "CompuMethodName" SG_ 2164729093 ActuPnonAng "ActuPnonAng";
BA_ "GenSigStartValue" SG_ 2164729093 ActuPnonAng 32768;
BA_ "ISignalName" SG_ 2164729093 ActuPnonAng "IActuPnonAng";
BA_ "LongName" SG_ 2164729093 ActuPnonAng "Actual Pinion Angle";
BA_ "SysSignalName" SG_ 2164729093 ActuPnonAng "ActuPnonAng";
BA_ "CompuMethodName" SG_ 2164729093 ActuRoadWhlAng "ActuRoadWhlAng";
BA_ "GenSigStartValue" SG_ 2164729093 ActuRoadWhlAng 32600;
BA_ "ISignalName" SG_ 2164729093 ActuRoadWhlAng "IActuRoadWhlAng";
BA_ "LongName" SG_ 2164729093 ActuRoadWhlAng "Actual Road Wheel Angle";
BA_ "SysSignalName" SG_ 2164729093 ActuRoadWhlAng "ActuRoadWhlAng";
BA_ "CompuMethodName" SG_ 2164729093 StrgCustSetngDspCmd "StrgCustSetngDspCmd";
BA_ "ISignalName" SG_ 2164729093 StrgCustSetngDspCmd "IStrgCustSetngDspCmd";
BA_ "LongName" SG_ 2164729093 StrgCustSetngDspCmd "Steering Customization Setting Display Command";
BA_ "SysSignalName" SG_ 2164729093 StrgCustSetngDspCmd "StrgCustSetngDspCmd";
BA_ "CompuMethodName" SG_ 2164729093 EPSPriyChnlFlrSts "EPSPriyChnlFlrSts";
BA_ "ISignalName" SG_ 2164729093 EPSPriyChnlFlrSts "IEPSPriyChnlFlrSts";
BA_ "LongName" SG_ 2164729093 EPSPriyChnlFlrSts "Electric Power Steering Primary Channel Failure Status";
BA_ "SysSignalName" SG_ 2164729093 EPSPriyChnlFlrSts "EPSPriyChnlFlrSts";
BA_ "CompuMethodName" SG_ 2164729093 EPSFlrSts "EPSFlrSts";
BA_ "ISignalName" SG_ 2164729093 EPSFlrSts "IEPSFlrSts";
BA_ "LongName" SG_ 2164729093 EPSFlrSts "Electric Power Steering Failure Status";
BA_ "SysSignalName" SG_ 2164729093 EPSFlrSts "EPSFlrSts";
BA_ "CompuMethodName" SG_ 2164729093 EPSCurntDrvMd "EPSCurntDrvMd";
BA_ "ISignalName" SG_ 2164729093 EPSCurntDrvMd "IEPSCurntDrvMd";
BA_ "LongName" SG_ 2164729093 EPSCurntDrvMd "Eps Current Drive Mode";
BA_ "SysSignalName" SG_ 2164729093 EPSCurntDrvMd "EPSCurntDrvMd";
BA_ "CompuMethodName" SG_ 2164729093 ActuPnonAngV "ActuPnonAngV";
BA_ "ISignalName" SG_ 2164729093 ActuPnonAngV "IActuPnonAngV";
BA_ "LongName" SG_ 2164729093 ActuPnonAngV "Actual Pinion Angle Validity";
BA_ "SysSignalName" SG_ 2164729093 ActuPnonAngV "ActuPnonAngV";
BA_ "CompuMethodName" SG_ 2164729093 EPSToqValAldMaxV "EPSToqValAldMaxV";
BA_ "ISignalName" SG_ 2164729093 EPSToqValAldMaxV "IEPSToqValAldMaxV";
BA_ "LongName" SG_ 2164729093 EPSToqValAldMaxV "Electric Power Steering Torque Value Allowed Maximum Validity";
BA_ "SysSignalName" SG_ 2164729093 EPSToqValAldMaxV "EPSToqValAldMaxV";
BA_ "CompuMethodName" SG_ 2164729093 EPSLimMotToqV "EPSLimMotToqV";
BA_ "GenSigStartValue" SG_ 2164729093 EPSLimMotToqV 1;
BA_ "ISignalName" SG_ 2164729093 EPSLimMotToqV "IEPSLimMotToqV";
BA_ "LongName" SG_ 2164729093 EPSLimMotToqV "Electric_Power_Steering_Limited_Motor_Torque_Validity";
BA_ "SysSignalName" SG_ 2164729093 EPSLimMotToqV "EPSLimMotToqV";
BA_ "CompuMethodName" SG_ 2164729093 EPSActRetMotToqV "EPSActRetMotToqV";
BA_ "GenSigStartValue" SG_ 2164729093 EPSActRetMotToqV 1;
BA_ "ISignalName" SG_ 2164729093 EPSActRetMotToqV "IEPSActRetMotToqV";
BA_ "LongName" SG_ 2164729093 EPSActRetMotToqV "Electric_Power_Steering_Active_Return_Motor_Torque_Validity";
BA_ "SysSignalName" SG_ 2164729093 EPSActRetMotToqV "EPSActRetMotToqV";
BA_ "CompuMethodName" SG_ 2164729093 EPS_10ms_Group01_Reserved1 "EPS_10ms_Group01_Reserved1";
BA_ "GenSigStartValue" SG_ 2164729093 EPS_10ms_Group01_Reserved1 1;
BA_ "ISignalName" SG_ 2164729093 EPS_10ms_Group01_Reserved1 "IEPS_10ms_Group01_Reserved1";
BA_ "SysSignalName" SG_ 2164729093 EPS_10ms_Group01_Reserved1 "EPS_10ms_Group01_Reserved1";
BA_ "CompuMethodName" SG_ 2164729093 ChLKAAngReqResp "ChLKAAngReqResp";
BA_ "ISignalName" SG_ 2164729093 ChLKAAngReqResp "IChLKAAngReqResp";
BA_ "LongName" SG_ 2164729093 ChLKAAngReqResp "Chassis Lane Keeping Assist Angle Request Response";
BA_ "SysSignalName" SG_ 2164729093 ChLKAAngReqResp "ChLKAAngReqResp";
BA_ "CompuMethodName" SG_ 2164729093 EPS_10ms_Group01_Reserved2 "EPS_10ms_Group01_Reserved2";
BA_ "GenSigStartValue" SG_ 2164729093 EPS_10ms_Group01_Reserved2 15;
BA_ "ISignalName" SG_ 2164729093 EPS_10ms_Group01_Reserved2 "IEPS_10ms_Group01_Reserved2";
BA_ "SysSignalName" SG_ 2164729093 EPS_10ms_Group01_Reserved2 "EPS_10ms_Group01_Reserved2";
BA_ "CompuMethodName" SG_ 2164729093 EPSToqValAldMinV "EPSToqValAldMinV";
BA_ "ISignalName" SG_ 2164729093 EPSToqValAldMinV "IEPSToqValAldMinV";
BA_ "LongName" SG_ 2164729093 EPSToqValAldMinV "Electric Power Steering Torque Value Allowed Minimum Validity";
BA_ "SysSignalName" SG_ 2164729093 EPSToqValAldMinV "EPSToqValAldMinV";
BA_ "CompuMethodName" SG_ 2164729093 CHLKAHptResp "CHLKAHptResp";
BA_ "ISignalName" SG_ 2164729093 CHLKAHptResp "ICHLKAHptResp";
BA_ "LongName" SG_ 2164729093 CHLKAHptResp "Lane Keeping Assist Haptic Response";
BA_ "SysSignalName" SG_ 2164729093 CHLKAHptResp "CHLKAHptResp";
BA_ "CompuMethodName" SG_ 2164729093 EPS_10ms_Group01_Reserved3 "EPS_10ms_Group01_Reserved3";
BA_ "GenSigStartValue" SG_ 2164729093 EPS_10ms_Group01_Reserved3 255;
BA_ "ISignalName" SG_ 2164729093 EPS_10ms_Group01_Reserved3 "IEPS_10ms_Group01_Reserved3";
BA_ "SysSignalName" SG_ 2164729093 EPS_10ms_Group01_Reserved3 "EPS_10ms_Group01_Reserved3";
BA_ "CompuMethodName" SG_ 2164729093 ADASStrgDlvrdToq "ADASStrgDlvrdToq";
BA_ "GenSigStartValue" SG_ 2164729093 ADASStrgDlvrdToq 1024;
BA_ "ISignalName" SG_ 2164729093 ADASStrgDlvrdToq "IADASStrgDlvrdToq";
BA_ "LongName" SG_ 2164729093 ADASStrgDlvrdToq "Advanced Driver Assistance System Steering Delivered Torque";
BA_ "SysSignalName" SG_ 2164729093 ADASStrgDlvrdToq "ADASStrgDlvrdToq";
BA_ "CompuMethodName" SG_ 2164729093 EPS_10ms_Group01_Reserved4 "EPS_10ms_Group01_Reserved4";
BA_ "GenSigStartValue" SG_ 2164729093 EPS_10ms_Group01_Reserved4 3;
BA_ "ISignalName" SG_ 2164729093 EPS_10ms_Group01_Reserved4 "IEPS_10ms_Group01_Reserved4";
BA_ "SysSignalName" SG_ 2164729093 EPS_10ms_Group01_Reserved4 "EPS_10ms_Group01_Reserved4";
BA_ "CompuMethodName" SG_ 2164729093 ChLKAToqReqResp "ChLKAToqReqResp";
BA_ "ISignalName" SG_ 2164729093 ChLKAToqReqResp "IChLKAToqReqResp";
BA_ "LongName" SG_ 2164729093 ChLKAToqReqResp "Chassis Lane Keeping Assist Torque Request Response";
BA_ "SysSignalName" SG_ 2164729093 ChLKAToqReqResp "ChLKAToqReqResp";
BA_ "CompuMethodName" SG_ 2164729093 EPSToqValAldMax "EPSToqValAldMax";
BA_ "GenSigStartValue" SG_ 2164729093 EPSToqValAldMax 1024;
BA_ "ISignalName" SG_ 2164729093 EPSToqValAldMax "IEPSToqValAldMax";
BA_ "LongName" SG_ 2164729093 EPSToqValAldMax "Electric Power Steering Torque Value Allowed Maximum";
BA_ "SysSignalName" SG_ 2164729093 EPSToqValAldMax "EPSToqValAldMax";
BA_ "CompuMethodName" SG_ 2164729093 EPSCoDrivingSts "EPSCoDrivingSts";
BA_ "GenSigStartValue" SG_ 2164729093 EPSCoDrivingSts 3;
BA_ "ISignalName" SG_ 2164729093 EPSCoDrivingSts "IEPSCoDrivingSts";
BA_ "LongName" SG_ 2164729093 EPSCoDrivingSts "Electric Power Steering Coperation Driving Status";
BA_ "SysSignalName" SG_ 2164729093 EPSCoDrivingSts "EPSCoDrivingSts";
BA_ "CompuMethodName" SG_ 2164729093 EPS_10ms_Group01_Reserved5 "EPS_10ms_Group01_Reserved5";
BA_ "GenSigStartValue" SG_ 2164729093 EPS_10ms_Group01_Reserved5 7;
BA_ "ISignalName" SG_ 2164729093 EPS_10ms_Group01_Reserved5 "IEPS_10ms_Group01_Reserved5";
BA_ "SysSignalName" SG_ 2164729093 EPS_10ms_Group01_Reserved5 "EPS_10ms_Group01_Reserved5";
BA_ "CompuMethodName" SG_ 2164729093 EPSToqValAldMin "EPSToqValAldMin";
BA_ "GenSigStartValue" SG_ 2164729093 EPSToqValAldMin 1024;
BA_ "ISignalName" SG_ 2164729093 EPSToqValAldMin "IEPSToqValAldMin";
BA_ "LongName" SG_ 2164729093 EPSToqValAldMin "Electric Power Steering Torque Value Allowed Minimum";
BA_ "SysSignalName" SG_ 2164729093 EPSToqValAldMin "EPSToqValAldMin";
BA_ "CompuMethodName" SG_ 2164729093 EPS_10ms_Group01_Reserved6 "EPS_10ms_Group01_Reserved6";
BA_ "GenSigStartValue" SG_ 2164729093 EPS_10ms_Group01_Reserved6 31;
BA_ "ISignalName" SG_ 2164729093 EPS_10ms_Group01_Reserved6 "IEPS_10ms_Group01_Reserved6";
BA_ "SysSignalName" SG_ 2164729093 EPS_10ms_Group01_Reserved6 "EPS_10ms_Group01_Reserved6";
BA_ "CompuMethodName" SG_ 2164729093 EPSActRetMotToq "EPSActRetMotToq";
BA_ "ISignalName" SG_ 2164729093 EPSActRetMotToq "IEPSActRetMotToq";
BA_ "LongName" SG_ 2164729093 EPSActRetMotToq "Electric_Power_Steering_Active_Return_Motor_Torque";
BA_ "SysSignalName" SG_ 2164729093 EPSActRetMotToq "EPSActRetMotToq";
BA_ "CompuMethodName" SG_ 2164729093 EPS_10ms_Group01_Reserved7 "EPS_10ms_Group01_Reserved7";
BA_ "GenSigStartValue" SG_ 2164729093 EPS_10ms_Group01_Reserved7 255;
BA_ "ISignalName" SG_ 2164729093 EPS_10ms_Group01_Reserved7 "IEPS_10ms_Group01_Reserved7";
BA_ "SysSignalName" SG_ 2164729093 EPS_10ms_Group01_Reserved7 "EPS_10ms_Group01_Reserved7";
BA_ "CompuMethodName" SG_ 2164729093 DrvrStrgDlvrdToq "DrvrStrgDlvrdToq";
BA_ "GenSigStartValue" SG_ 2164729093 DrvrStrgDlvrdToq 2048;
BA_ "ISignalName" SG_ 2164729093 DrvrStrgDlvrdToq "IDrvrStrgDlvrdToq";
BA_ "LongName" SG_ 2164729093 DrvrStrgDlvrdToq "Driver Steering Delivered Torque";
BA_ "SysSignalName" SG_ 2164729093 DrvrStrgDlvrdToq "DrvrStrgDlvrdToq";
BA_ "CompuMethodName" SG_ 2164729093 EPS_10ms_Group01_Reserved8 "EPS_10ms_Group01_Reserved8";
BA_ "GenSigStartValue" SG_ 2164729093 EPS_10ms_Group01_Reserved8 15;
BA_ "ISignalName" SG_ 2164729093 EPS_10ms_Group01_Reserved8 "IEPS_10ms_Group01_Reserved8";
BA_ "SysSignalName" SG_ 2164729093 EPS_10ms_Group01_Reserved8 "EPS_10ms_Group01_Reserved8";
BA_ "CompuMethodName" SG_ 2164729093 EPS_10ms_Group01_Reserved9 "EPS_10ms_Group01_Reserved9";
BA_ "GenSigStartValue" SG_ 2164729093 EPS_10ms_Group01_Reserved9 255;
BA_ "ISignalName" SG_ 2164729093 EPS_10ms_Group01_Reserved9 "IEPS_10ms_Group01_Reserved9";
BA_ "SysSignalName" SG_ 2164729093 EPS_10ms_Group01_Reserved9 "EPS_10ms_Group01_Reserved9";
BA_ "CompuMethodName" SG_ 2164729093 EPSLimMotToq "EPSLimMotToq";
BA_ "ISignalName" SG_ 2164729093 EPSLimMotToq "IEPSLimMotToq";
BA_ "LongName" SG_ 2164729093 EPSLimMotToq "Electric_Power_Steering_Limited_Motor_Torque";
BA_ "SysSignalName" SG_ 2164729093 EPSLimMotToq "EPSLimMotToq";
BA_ "CompuMethodName" SG_ 2164729094 EPS_10ms_Group02_CRC "EPS_10ms_Group02_CRC";
BA_ "ISignalName" SG_ 2164729094 EPS_10ms_Group02_CRC "IEPS_10ms_Group02_CRC";
BA_ "LongName" SG_ 2164729094 EPS_10ms_Group02_CRC "EPS_10ms_Group02_CRC";
BA_ "SysSignalName" SG_ 2164729094 EPS_10ms_Group02_CRC "EPS_10ms_Group02_CRC";
BA_ "CompuMethodName" SG_ 2164729094 EPS_10ms_Group02_RC "EPS_10ms_Group02_RC";
BA_ "ISignalName" SG_ 2164729094 EPS_10ms_Group02_RC "IEPS_10ms_Group02_RC";
BA_ "LongName" SG_ 2164729094 EPS_10ms_Group02_RC "EPS_10ms_Group02_RC";
BA_ "SysSignalName" SG_ 2164729094 EPS_10ms_Group02_RC "EPS_10ms_Group02_RC";
BA_ "CompuMethodName" SG_ 2164729094 EPSAIPkgAngReqResp "EPSAIPkgAngReqResp";
BA_ "GenSigStartValue" SG_ 2164729094 EPSAIPkgAngReqResp 7;
BA_ "ISignalName" SG_ 2164729094 EPSAIPkgAngReqResp "IEPSAIPkgAngReqResp";
BA_ "LongName" SG_ 2164729094 EPSAIPkgAngReqResp "Electric Power Steering Ai Parking Angle Request Response";
BA_ "SysSignalName" SG_ 2164729094 EPSAIPkgAngReqResp "EPSAIPkgAngReqResp";
BA_ "CompuMethodName" SG_ 2164729094 EPSAIPkgAngReqRespInh "EPSAIPkgAngReqRespInh";
BA_ "ISignalName" SG_ 2164729094 EPSAIPkgAngReqRespInh "IEPSAIPkgAngReqRespInh";
BA_ "LongName" SG_ 2164729094 EPSAIPkgAngReqRespInh "Electric Power Steering Ai Parking Angle Request Response Inhibit Reason";
BA_ "SysSignalName" SG_ 2164729094 EPSAIPkgAngReqRespInh "EPSAIPkgAngReqRespInh";
BA_ "CompuMethodName" SG_ 2164729094 EPSAIPltAngRespStsInh "EPSAIPltAngRespStsInh";
BA_ "ISignalName" SG_ 2164729094 EPSAIPltAngRespStsInh "IEPSAIPltAngRespStsInh";
BA_ "LongName" SG_ 2164729094 EPSAIPltAngRespStsInh "Electric_Power_Steering_Ai_Pilot_Angle_Request_Response_Inhibit_Reason";
BA_ "SysSignalName" SG_ 2164729094 EPSAIPltAngRespStsInh "EPSAIPltAngRespStsInh";
BA_ "CompuMethodName" SG_ 2164729094 EPS_10ms_Group02_Reserved1 "EPS_10ms_Group02_Reserved1";
BA_ "GenSigStartValue" SG_ 2164729094 EPS_10ms_Group02_Reserved1 7;
BA_ "ISignalName" SG_ 2164729094 EPS_10ms_Group02_Reserved1 "IEPS_10ms_Group02_Reserved1";
BA_ "SysSignalName" SG_ 2164729094 EPS_10ms_Group02_Reserved1 "EPS_10ms_Group02_Reserved1";
BA_ "CompuMethodName" SG_ 2164729094 EPSAIPltAvlLvl "EPSAIPltAvlLvl";
BA_ "ISignalName" SG_ 2164729094 EPSAIPltAvlLvl "IEPSAIPltAvlLvl";
BA_ "LongName" SG_ 2164729094 EPSAIPltAvlLvl "Electric Power Steering Ai Pilot Availablity Level";
BA_ "SysSignalName" SG_ 2164729094 EPSAIPltAvlLvl "EPSAIPltAvlLvl";
BA_ "CompuMethodName" SG_ 2164729094 EPSAIPltAngRespSts "EPSAIPltAngRespSts";
BA_ "ISignalName" SG_ 2164729094 EPSAIPltAngRespSts "IEPSAIPltAngRespSts";
BA_ "LongName" SG_ 2164729094 EPSAIPltAngRespSts "Electric Power Steering Ai Pilot Angle Response Status";
BA_ "SysSignalName" SG_ 2164729094 EPSAIPltAngRespSts "EPSAIPltAngRespSts";
BA_ "CompuMethodName" SG_ 2164729094 ActuRoadWhlAngGrdV "ActuRoadWhlAngGrdV";
BA_ "ISignalName" SG_ 2164729094 ActuRoadWhlAngGrdV "IActuRoadWhlAngGrdV";
BA_ "LongName" SG_ 2164729094 ActuRoadWhlAngGrdV "Actual Road Wheel Angle Gradient Validity";
BA_ "SysSignalName" SG_ 2164729094 ActuRoadWhlAngGrdV "ActuRoadWhlAngGrdV";
BA_ "CompuMethodName" SG_ 2164729094 EPS_10ms_Group02_Reserved2 "EPS_10ms_Group02_Reserved2";
BA_ "GenSigStartValue" SG_ 2164729094 EPS_10ms_Group02_Reserved2 63;
BA_ "ISignalName" SG_ 2164729094 EPS_10ms_Group02_Reserved2 "IEPS_10ms_Group02_Reserved2";
BA_ "SysSignalName" SG_ 2164729094 EPS_10ms_Group02_Reserved2 "EPS_10ms_Group02_Reserved2";
BA_ "CompuMethodName" SG_ 2164729094 EPSAIPltCtrlChannel "EPSAIPltCtrlChannel";
BA_ "ISignalName" SG_ 2164729094 EPSAIPltCtrlChannel "IEPSAIPltCtrlChannel";
BA_ "LongName" SG_ 2164729094 EPSAIPltCtrlChannel "EPSAIPltCtrlChannel";
BA_ "SysSignalName" SG_ 2164729094 EPSAIPltCtrlChannel "EPSAIPltCtrlChannel";
BA_ "CompuMethodName" SG_ 2164729094 ActuRoadWhlAngGrd "ActuRoadWhlAngGrd";
BA_ "GenSigStartValue" SG_ 2164729094 ActuRoadWhlAngGrd 32600;
BA_ "ISignalName" SG_ 2164729094 ActuRoadWhlAngGrd "IActuRoadWhlAngGrd";
BA_ "LongName" SG_ 2164729094 ActuRoadWhlAngGrd "Actual Road Wheel Angle Gradient";
BA_ "SysSignalName" SG_ 2164729094 ActuRoadWhlAngGrd "ActuRoadWhlAngGrd";
BA_ "CompuMethodName" SG_ 2164729108 EPS_10ms_Group05_CRC "EPS_10ms_Group05_CRC";
BA_ "ISignalName" SG_ 2164729108 EPS_10ms_Group05_CRC "IEPS_10ms_Group05_CRC";
BA_ "LongName" SG_ 2164729108 EPS_10ms_Group05_CRC "EPS_10ms_Group05_CRC";
BA_ "SysSignalName" SG_ 2164729108 EPS_10ms_Group05_CRC "EPS_10ms_Group05_CRC";
BA_ "CompuMethodName" SG_ 2164729108 EPS_10ms_Group05_RC "EPS_10ms_Group05_RC";
BA_ "ISignalName" SG_ 2164729108 EPS_10ms_Group05_RC "IEPS_10ms_Group05_RC";
BA_ "LongName" SG_ 2164729108 EPS_10ms_Group05_RC "EPS_10ms_Group05_RC";
BA_ "SysSignalName" SG_ 2164729108 EPS_10ms_Group05_RC "EPS_10ms_Group05_RC";
BA_ "CompuMethodName" SG_ 2164729108 StrgWhlAngSnsrFlt "StrgWhlAngSnsrFlt";
BA_ "ISignalName" SG_ 2164729108 StrgWhlAngSnsrFlt "IStrgWhlAngSnsrFlt";
BA_ "LongName" SG_ 2164729108 StrgWhlAngSnsrFlt "Steering Wheel Angle Sensor Fault";
BA_ "SysSignalName" SG_ 2164729108 StrgWhlAngSnsrFlt "StrgWhlAngSnsrFlt";
BA_ "CompuMethodName" SG_ 2164729108 StrgWhlAngV "StrgWhlAngV";
BA_ "ISignalName" SG_ 2164729108 StrgWhlAngV "IStrgWhlAngV";
BA_ "LongName" SG_ 2164729108 StrgWhlAngV "Steering Wheel Angle Validity";
BA_ "SysSignalName" SG_ 2164729108 StrgWhlAngV "StrgWhlAngV";
BA_ "CompuMethodName" SG_ 2164729108 StrgWhlAngSnsrMultCapb "StrgWhlAngSnsrMultCapb";
BA_ "ISignalName" SG_ 2164729108 StrgWhlAngSnsrMultCapb "IStrgWhlAngSnsrMultCapb";
BA_ "LongName" SG_ 2164729108 StrgWhlAngSnsrMultCapb "Steering Wheel Angle Sensor Multiturn Capable";
BA_ "SysSignalName" SG_ 2164729108 StrgWhlAngSnsrMultCapb "StrgWhlAngSnsrMultCapb";
BA_ "CompuMethodName" SG_ 2164729108 StrgWhlAngSnsrInid "StrgWhlAngSnsrInid";
BA_ "ISignalName" SG_ 2164729108 StrgWhlAngSnsrInid "IStrgWhlAngSnsrInid";
BA_ "LongName" SG_ 2164729108 StrgWhlAngSnsrInid "Steering Wheel Angle Sensor Initialized";
BA_ "SysSignalName" SG_ 2164729108 StrgWhlAngSnsrInid "StrgWhlAngSnsrInid";
BA_ "CompuMethodName" SG_ 2164729108 StrgWhlAng "StrgWhlAng";
BA_ "ISignalName" SG_ 2164729108 StrgWhlAng "IStrgWhlAng";
BA_ "LongName" SG_ 2164729108 StrgWhlAng "Steering Wheel Angle";
BA_ "SysSignalName" SG_ 2164729108 StrgWhlAng "StrgWhlAng";
BA_ "CompuMethodName" SG_ 2164729108 StrgWhlAngGrd "StrgWhlAngGrd";
BA_ "ISignalName" SG_ 2164729108 StrgWhlAngGrd "IStrgWhlAngGrd";
BA_ "LongName" SG_ 2164729108 StrgWhlAngGrd "Steering Wheel Angle Gradient";
BA_ "SysSignalName" SG_ 2164729108 StrgWhlAngGrd "StrgWhlAngGrd";
BA_ "CompuMethodName" SG_ 2164729108 EPS_10ms_Group05_Reserved1 "EPS_10ms_Group05_Reserved1";
BA_ "GenSigStartValue" SG_ 2164729108 EPS_10ms_Group05_Reserved1 3;
BA_ "ISignalName" SG_ 2164729108 EPS_10ms_Group05_Reserved1 "IEPS_10ms_Group05_Reserved1";
BA_ "SysSignalName" SG_ 2164729108 EPS_10ms_Group05_Reserved1 "EPS_10ms_Group05_Reserved1";
BA_ "CompuMethodName" SG_ 2164729108 StrgWhlAngSnsrCalSts "StrgWhlAngSnsrCalSts";
BA_ "ISignalName" SG_ 2164729108 StrgWhlAngSnsrCalSts "IStrgWhlAngSnsrCalSts";
BA_ "LongName" SG_ 2164729108 StrgWhlAngSnsrCalSts "Steering Wheel Angle Sensor Calibration Status";
BA_ "SysSignalName" SG_ 2164729108 StrgWhlAngSnsrCalSts "StrgWhlAngSnsrCalSts";
BA_ "CompuMethodName" SG_ 2164729108 EPS_10ms_Group05_Reserved2 "EPS_10ms_Group05_Reserved2";
BA_ "GenSigStartValue" SG_ 2164729108 EPS_10ms_Group05_Reserved2 255;
BA_ "ISignalName" SG_ 2164729108 EPS_10ms_Group05_Reserved2 "IEPS_10ms_Group05_Reserved2";
BA_ "SysSignalName" SG_ 2164729108 EPS_10ms_Group05_Reserved2 "EPS_10ms_Group05_Reserved2";
BA_ "CompuMethodName" SG_ 2164729108 EPS_10ms_Group05_Reserved3 "EPS_10ms_Group05_Reserved3";
BA_ "GenSigStartValue" SG_ 2164729108 EPS_10ms_Group05_Reserved3 255;
BA_ "ISignalName" SG_ 2164729108 EPS_10ms_Group05_Reserved3 "IEPS_10ms_Group05_Reserved3";
BA_ "SysSignalName" SG_ 2164729108 EPS_10ms_Group05_Reserved3 "EPS_10ms_Group05_Reserved3";
BA_ "CompuMethodName" SG_ 2164729095 IBS_10ms_Group04_CRC "IBS_10ms_Group04_CRC";
BA_ "ISignalName" SG_ 2164729095 IBS_10ms_Group04_CRC "IIBS_10ms_Group04_CRC";
BA_ "LongName" SG_ 2164729095 IBS_10ms_Group04_CRC "IBS_10ms_Group04_CRC";
BA_ "SysSignalName" SG_ 2164729095 IBS_10ms_Group04_CRC "IBS_10ms_Group04_CRC";
BA_ "CompuMethodName" SG_ 2164729095 IBS_10ms_Group04_RC "IBS_10ms_Group04_RC";
BA_ "ISignalName" SG_ 2164729095 IBS_10ms_Group04_RC "IIBS_10ms_Group04_RC";
BA_ "LongName" SG_ 2164729095 IBS_10ms_Group04_RC "IBS_10ms_Group04_RC";
BA_ "SysSignalName" SG_ 2164729095 IBS_10ms_Group04_RC "IBS_10ms_Group04_RC";
BA_ "CompuMethodName" SG_ 2164729095 IBS_10ms_Group04_Reserved1 "IBS_10ms_Group04_Reserved1";
BA_ "GenSigStartValue" SG_ 2164729095 IBS_10ms_Group04_Reserved1 15;
BA_ "ISignalName" SG_ 2164729095 IBS_10ms_Group04_Reserved1 "IIBS_10ms_Group04_Reserved1";
BA_ "SysSignalName" SG_ 2164729095 IBS_10ms_Group04_Reserved1 "IBS_10ms_Group04_Reserved1";
BA_ "CompuMethodName" SG_ 2164729095 BrkPdlPos "BrkPdlPos";
BA_ "ISignalName" SG_ 2164729095 BrkPdlPos "IBrkPdlPos";
BA_ "LongName" SG_ 2164729095 BrkPdlPos "Brake Pedal Position";
BA_ "SysSignalName" SG_ 2164729095 BrkPdlPos "BrkPdlPos";
BA_ "CompuMethodName" SG_ 2164729095 IBS_10ms_Group04_Reserved3 "IBS_10ms_Group04_Reserved3";
BA_ "GenSigStartValue" SG_ 2164729095 IBS_10ms_Group04_Reserved3 15;
BA_ "ISignalName" SG_ 2164729095 IBS_10ms_Group04_Reserved3 "IIBS_10ms_Group04_Reserved3";
BA_ "SysSignalName" SG_ 2164729095 IBS_10ms_Group04_Reserved3 "IBS_10ms_Group04_Reserved3";
BA_ "CompuMethodName" SG_ 2164729095 EPBSysBrkLghtsReqdA "EPBSysBrkLghtsReqdA";
BA_ "ISignalName" SG_ 2164729095 EPBSysBrkLghtsReqdA "IEPBSysBrkLghtsReqdA";
BA_ "SysSignalName" SG_ 2164729095 EPBSysBrkLghtsReqdA "EPBSysBrkLghtsReqdA";
BA_ "CompuMethodName" SG_ 2164729095 IBS_10ms_Group04_Reserved2 "IBS_10ms_Group04_Reserved2";
BA_ "GenSigStartValue" SG_ 2164729095 IBS_10ms_Group04_Reserved2 1;
BA_ "ISignalName" SG_ 2164729095 IBS_10ms_Group04_Reserved2 "IIBS_10ms_Group04_Reserved2";
BA_ "SysSignalName" SG_ 2164729095 IBS_10ms_Group04_Reserved2 "IBS_10ms_Group04_Reserved2";
BA_ "CompuMethodName" SG_ 2164729095 BrkSysBrkLghtsReqd "BrkSysBrkLghtsReqd";
BA_ "ISignalName" SG_ 2164729095 BrkSysBrkLghtsReqd "IBrkSysBrkLghtsReqd";
BA_ "LongName" SG_ 2164729095 BrkSysBrkLghtsReqd "Brake System Brake Lights Requested";
BA_ "SysSignalName" SG_ 2164729095 BrkSysBrkLghtsReqd "BrkSysBrkLghtsReqd";
BA_ "CompuMethodName" SG_ 2164729095 BrkPdlPosV "BrkPdlPosV";
BA_ "ISignalName" SG_ 2164729095 BrkPdlPosV "IBrkPdlPosV";
BA_ "LongName" SG_ 2164729095 BrkPdlPosV "Brake Pedal Position Validity";
BA_ "SysSignalName" SG_ 2164729095 BrkPdlPosV "BrkPdlPosV";
BA_ "CompuMethodName" SG_ 2164729095 ChSysEnToqReqProtn "ChSysEnToqReqProtn";
BA_ "ISignalName" SG_ 2164729095 ChSysEnToqReqProtn "IChSysEnToqReqProtn";
BA_ "SysSignalName" SG_ 2164729095 ChSysEnToqReqProtn "ChSysEnToqReqProtn";
BA_ "CompuMethodName" SG_ 2164729095 IBS_10ms_Group04_Reserved4 "IBS_10ms_Group04_Reserved4";
BA_ "GenSigStartValue" SG_ 2164729095 IBS_10ms_Group04_Reserved4 3;
BA_ "ISignalName" SG_ 2164729095 IBS_10ms_Group04_Reserved4 "IIBS_10ms_Group04_Reserved4";
BA_ "SysSignalName" SG_ 2164729095 IBS_10ms_Group04_Reserved4 "IBS_10ms_Group04_Reserved4";
BA_ "CompuMethodName" SG_ 2164729095 IBS_10ms_Group04_Reserved5 "IBS_10ms_Group04_Reserved5";
BA_ "GenSigStartValue" SG_ 2164729095 IBS_10ms_Group04_Reserved5 255;
BA_ "ISignalName" SG_ 2164729095 IBS_10ms_Group04_Reserved5 "IIBS_10ms_Group04_Reserved5";
BA_ "SysSignalName" SG_ 2164729095 IBS_10ms_Group04_Reserved5 "IBS_10ms_Group04_Reserved5";
BA_ "CompuMethodName" SG_ 2164729095 IBS_10ms_Group04_Reserved6 "IBS_10ms_Group04_Reserved6";
BA_ "GenSigStartValue" SG_ 2164729095 IBS_10ms_Group04_Reserved6 255;
BA_ "ISignalName" SG_ 2164729095 IBS_10ms_Group04_Reserved6 "IIBS_10ms_Group04_Reserved6";
BA_ "SysSignalName" SG_ 2164729095 IBS_10ms_Group04_Reserved6 "IBS_10ms_Group04_Reserved6";
BA_ "CompuMethodName" SG_ 2164729097 IBS_20ms_Group10_CRC "IBS_20ms_Group10_CRC";
BA_ "ISignalName" SG_ 2164729097 IBS_20ms_Group10_CRC "IIBS_20ms_Group10_CRC";
BA_ "LongName" SG_ 2164729097 IBS_20ms_Group10_CRC "IBS_20ms_Group10_CRC";
BA_ "SysSignalName" SG_ 2164729097 IBS_20ms_Group10_CRC "IBS_20ms_Group10_CRC";
BA_ "CompuMethodName" SG_ 2164729097 IBS_20ms_Group10_RC "IBS_20ms_Group10_RC";
BA_ "ISignalName" SG_ 2164729097 IBS_20ms_Group10_RC "IIBS_20ms_Group10_RC";
BA_ "LongName" SG_ 2164729097 IBS_20ms_Group10_RC "IBS_20ms_Group10_RC";
BA_ "SysSignalName" SG_ 2164729097 IBS_20ms_Group10_RC "IBS_20ms_Group10_RC";
BA_ "CompuMethodName" SG_ 2164729097 BrkPdlDrvrAppdPrsV "BrkPdlDrvrAppdPrsV";
BA_ "ISignalName" SG_ 2164729097 BrkPdlDrvrAppdPrsV "IBrkPdlDrvrAppdPrsV";
BA_ "LongName" SG_ 2164729097 BrkPdlDrvrAppdPrsV "Brake Pedal Driver Applied Pressure Validity";
BA_ "SysSignalName" SG_ 2164729097 BrkPdlDrvrAppdPrsV "BrkPdlDrvrAppdPrsV";
BA_ "CompuMethodName" SG_ 2164729097 BrkPdlDrvrAppdPrsDetV "BrkPdlDrvrAppdPrsDetV";
BA_ "ISignalName" SG_ 2164729097 BrkPdlDrvrAppdPrsDetV "IBrkPdlDrvrAppdPrsDetV";
BA_ "LongName" SG_ 2164729097 BrkPdlDrvrAppdPrsDetV "Brake_Pedal_Driver_Applied_Pressure_Detected_Validity";
BA_ "SysSignalName" SG_ 2164729097 BrkPdlDrvrAppdPrsDetV "BrkPdlDrvrAppdPrsDetV";
BA_ "CompuMethodName" SG_ 2164729097 BrkPdlDrvrAppdPrsDet "BrkPdlDrvrAppdPrsDet";
BA_ "ISignalName" SG_ 2164729097 BrkPdlDrvrAppdPrsDet "IBrkPdlDrvrAppdPrsDet";
BA_ "LongName" SG_ 2164729097 BrkPdlDrvrAppdPrsDet "Brake_Pedal_Driver_Applied_Pressure_Detected";
BA_ "SysSignalName" SG_ 2164729097 BrkPdlDrvrAppdPrsDet "BrkPdlDrvrAppdPrsDet";
BA_ "CompuMethodName" SG_ 2164729097 BrkDiscTemSts "BrkDiscTemSts";
BA_ "ISignalName" SG_ 2164729097 BrkDiscTemSts "IBrkDiscTemSts";
BA_ "LongName" SG_ 2164729097 BrkDiscTemSts "Brake Disc Temperature Status";
BA_ "SysSignalName" SG_ 2164729097 BrkDiscTemSts "BrkDiscTemSts";
BA_ "CompuMethodName" SG_ 2164729097 BrkPdlDrvrAppdPrs "BrkPdlDrvrAppdPrs";
BA_ "ISignalName" SG_ 2164729097 BrkPdlDrvrAppdPrs "IBrkPdlDrvrAppdPrs";
BA_ "LongName" SG_ 2164729097 BrkPdlDrvrAppdPrs "Brake Pedal Driver Applied Pressure";
BA_ "SysSignalName" SG_ 2164729097 BrkPdlDrvrAppdPrs "BrkPdlDrvrAppdPrs";
BA_ "CompuMethodName" SG_ 2164729097 BrkPdlMdlSts "BrkPdlMdlSts";
BA_ "ISignalName" SG_ 2164729097 BrkPdlMdlSts "IBrkPdlMdlSts";
BA_ "LongName" SG_ 2164729097 BrkPdlMdlSts "Brake Pedal Model Status";
BA_ "SysSignalName" SG_ 2164729097 BrkPdlMdlSts "BrkPdlMdlSts";
BA_ "CompuMethodName" SG_ 2164729097 DrvrReqOtptRodTrvlSts "DrvrReqOtptRodTrvlSts";
BA_ "ISignalName" SG_ 2164729097 DrvrReqOtptRodTrvlSts "IDrvrReqOtptRodTrvlSts";
BA_ "LongName" SG_ 2164729097 DrvrReqOtptRodTrvlSts "Driver Request Output Rod Travel Status";
BA_ "SysSignalName" SG_ 2164729097 DrvrReqOtptRodTrvlSts "DrvrReqOtptRodTrvlSts";
BA_ "CompuMethodName" SG_ 2164729097 BrkPdlSimltdPrsV "BrkPdlSimltdPrsV";
BA_ "ISignalName" SG_ 2164729097 BrkPdlSimltdPrsV "IBrkPdlSimltdPrsV";
BA_ "LongName" SG_ 2164729097 BrkPdlSimltdPrsV "Brake Pedal Simulated Pressure Validity";
BA_ "SysSignalName" SG_ 2164729097 BrkPdlSimltdPrsV "BrkPdlSimltdPrsV";
BA_ "CompuMethodName" SG_ 2164729097 BrkPdlAppd "BrkPdlAppd";
BA_ "ISignalName" SG_ 2164729097 BrkPdlAppd "IBrkPdlAppd";
BA_ "LongName" SG_ 2164729097 BrkPdlAppd "Brake Pedal Applied";
BA_ "SysSignalName" SG_ 2164729097 BrkPdlAppd "BrkPdlAppd";
BA_ "CompuMethodName" SG_ 2164729097 BrkPdlAppdV "BrkPdlAppdV";
BA_ "ISignalName" SG_ 2164729097 BrkPdlAppdV "IBrkPdlAppdV";
BA_ "LongName" SG_ 2164729097 BrkPdlAppdV "Brake Pedal Applied Validity";
BA_ "SysSignalName" SG_ 2164729097 BrkPdlAppdV "BrkPdlAppdV";
BA_ "CompuMethodName" SG_ 2164729097 BrkPdlSimltdPrs "BrkPdlSimltdPrs";
BA_ "ISignalName" SG_ 2164729097 BrkPdlSimltdPrs "IBrkPdlSimltdPrs";
BA_ "LongName" SG_ 2164729097 BrkPdlSimltdPrs "Brake Pedal Simulated Pressure";
BA_ "SysSignalName" SG_ 2164729097 BrkPdlSimltdPrs "BrkPdlSimltdPrs";
BA_ "CompuMethodName" SG_ 2164729097 BrkFludLvlLowV "BrkFludLvlLowV";
BA_ "ISignalName" SG_ 2164729097 BrkFludLvlLowV "IBrkFludLvlLowV";
BA_ "LongName" SG_ 2164729097 BrkFludLvlLowV "Brake Fluid Level Low Validity";
BA_ "SysSignalName" SG_ 2164729097 BrkFludLvlLowV "BrkFludLvlLowV";
BA_ "CompuMethodName" SG_ 2164729097 BrkFludLvlLow "BrkFludLvlLow";
BA_ "ISignalName" SG_ 2164729097 BrkFludLvlLow "IBrkFludLvlLow";
BA_ "LongName" SG_ 2164729097 BrkFludLvlLow "Brake Fluid Level Low";
BA_ "SysSignalName" SG_ 2164729097 BrkFludLvlLow "BrkFludLvlLow";
BA_ "CompuMethodName" SG_ 2164729097 BrkPdlMdlActSts "BrkPdlMdlActSts";
BA_ "ISignalName" SG_ 2164729097 BrkPdlMdlActSts "IBrkPdlMdlActSts";
BA_ "LongName" SG_ 2164729097 BrkPdlMdlActSts "Brake Pedal Model Actual Status";
BA_ "SysSignalName" SG_ 2164729097 BrkPdlMdlActSts "BrkPdlMdlActSts";
BA_ "CompuMethodName" SG_ 2164729097 IBS_20ms_Group10_Reserved1 "IBS_20ms_Group10_Reserved1";
BA_ "GenSigStartValue" SG_ 2164729097 IBS_20ms_Group10_Reserved1 15;
BA_ "ISignalName" SG_ 2164729097 IBS_20ms_Group10_Reserved1 "IIBS_20ms_Group10_Reserved1";
BA_ "SysSignalName" SG_ 2164729097 IBS_20ms_Group10_Reserved1 "IBS_20ms_Group10_Reserved1";
BA_ "CompuMethodName" SG_ 2164729097 DrvrReqOtptRodTrvl "DrvrReqOtptRodTrvl";
BA_ "ISignalName" SG_ 2164729097 DrvrReqOtptRodTrvl "IDrvrReqOtptRodTrvl";
BA_ "LongName" SG_ 2164729097 DrvrReqOtptRodTrvl "Driver Request Output Rod Travel";
BA_ "SysSignalName" SG_ 2164729097 DrvrReqOtptRodTrvl "DrvrReqOtptRodTrvl";
BA_ "CompuMethodName" SG_ 2164729097 IBS_20ms_Group10_Reserved2 "IBS_20ms_Group10_Reserved2";
BA_ "GenSigStartValue" SG_ 2164729097 IBS_20ms_Group10_Reserved2 15;
BA_ "ISignalName" SG_ 2164729097 IBS_20ms_Group10_Reserved2 "IIBS_20ms_Group10_Reserved2";
BA_ "SysSignalName" SG_ 2164729097 IBS_20ms_Group10_Reserved2 "IBS_20ms_Group10_Reserved2";
BA_ "CompuMethodName" SG_ 2164729104 IBS_20ms_Group13_CRC "IBS_20ms_Group13_CRC";
BA_ "ISignalName" SG_ 2164729104 IBS_20ms_Group13_CRC "IIBS_20ms_Group13_CRC";
BA_ "LongName" SG_ 2164729104 IBS_20ms_Group13_CRC "IBS_20ms_Group13_CRC";
BA_ "SysSignalName" SG_ 2164729104 IBS_20ms_Group13_CRC "IBS_20ms_Group13_CRC";
BA_ "CompuMethodName" SG_ 2164729104 IBS_20ms_Group13_RC "IBS_20ms_Group13_RC";
BA_ "ISignalName" SG_ 2164729104 IBS_20ms_Group13_RC "IIBS_20ms_Group13_RC";
BA_ "LongName" SG_ 2164729104 IBS_20ms_Group13_RC "IBS_20ms_Group13_RC";
BA_ "SysSignalName" SG_ 2164729104 IBS_20ms_Group13_RC "IBS_20ms_Group13_RC";
BA_ "CompuMethodName" SG_ 2164729104 ACCBrkngA "ACCBrkngA";
BA_ "ISignalName" SG_ 2164729104 ACCBrkngA "IACCBrkngA";
BA_ "LongName" SG_ 2164729104 ACCBrkngA "Adaptive Cruise Control Braking Active";
BA_ "SysSignalName" SG_ 2164729104 ACCBrkngA "ACCBrkngA";
BA_ "CompuMethodName" SG_ 2164729104 ChAEBDclReqResp "ChAEBDclReqResp";
BA_ "ISignalName" SG_ 2164729104 ChAEBDclReqResp "IChAEBDclReqResp";
BA_ "LongName" SG_ 2164729104 ChAEBDclReqResp "Chassis Autonomous Emergency Braking Deceleration Request Response";
BA_ "SysSignalName" SG_ 2164729104 ChAEBDclReqResp "ChAEBDclReqResp";
BA_ "CompuMethodName" SG_ 2164729104 ChACCReqFlrSts "ChACCReqFlrSts";
BA_ "ISignalName" SG_ 2164729104 ChACCReqFlrSts "IChACCReqFlrSts";
BA_ "LongName" SG_ 2164729104 ChACCReqFlrSts "Chassis Adaptive Cruise Control Request Failure Status";
BA_ "SysSignalName" SG_ 2164729104 ChACCReqFlrSts "ChACCReqFlrSts";
BA_ "CompuMethodName" SG_ 2164729104 ChACCAccReqResp "ChACCAccReqResp";
BA_ "ISignalName" SG_ 2164729104 ChACCAccReqResp "IChACCAccReqResp";
BA_ "LongName" SG_ 2164729104 ChACCAccReqResp "Chassis Adaptive Cruise Control Acceleration Request Response";
BA_ "SysSignalName" SG_ 2164729104 ChACCAccReqResp "ChACCAccReqResp";
BA_ "CompuMethodName" SG_ 2164729104 ChAEBPrflReqResp "ChAEBPrflReqResp";
BA_ "ISignalName" SG_ 2164729104 ChAEBPrflReqResp "IChAEBPrflReqResp";
BA_ "LongName" SG_ 2164729104 ChAEBPrflReqResp "Chassis Autonomous Emergency Braking Prefill Request Response";
BA_ "SysSignalName" SG_ 2164729104 ChAEBPrflReqResp "ChAEBPrflReqResp";
BA_ "CompuMethodName" SG_ 2164729104 AutodDrvngSysMdReqRespV "AutodDrvngSysMdReqRespV";
BA_ "ISignalName" SG_ 2164729104 AutodDrvngSysMdReqRespV "IAutodDrvngSysMdReqRespV";
BA_ "LongName" SG_ 2164729104 AutodDrvngSysMdReqRespV "Automated Driving System Mode Request Response Validity";
BA_ "SysSignalName" SG_ 2164729104 AutodDrvngSysMdReqRespV "AutodDrvngSysMdReqRespV";
BA_ "CompuMethodName" SG_ 2164729104 AutodDrvngSysMdReqResp "AutodDrvngSysMdReqResp";
BA_ "ISignalName" SG_ 2164729104 AutodDrvngSysMdReqResp "IAutodDrvngSysMdReqResp";
BA_ "LongName" SG_ 2164729104 AutodDrvngSysMdReqResp "Automated Driving System Mode Request Response";
BA_ "SysSignalName" SG_ 2164729104 AutodDrvngSysMdReqResp "AutodDrvngSysMdReqResp";
BA_ "CompuMethodName" SG_ 2164729104 ChAEBHydBrkAstReqResp "ChAEBHydBrkAstReqResp";
BA_ "ISignalName" SG_ 2164729104 ChAEBHydBrkAstReqResp "IChAEBHydBrkAstReqResp";
BA_ "LongName" SG_ 2164729104 ChAEBHydBrkAstReqResp "Chassis Autonomous Emergency Braking Hydraulic Brake Assist Request Response";
BA_ "SysSignalName" SG_ 2164729104 ChAEBHydBrkAstReqResp "ChAEBHydBrkAstReqResp";
BA_ "CompuMethodName" SG_ 2164729104 ChAEBBrkJerkReqResp "ChAEBBrkJerkReqResp";
BA_ "ISignalName" SG_ 2164729104 ChAEBBrkJerkReqResp "IChAEBBrkJerkReqResp";
BA_ "LongName" SG_ 2164729104 ChAEBBrkJerkReqResp "Chassis Autonomous Emergency Braking Brake Jerk Request Response";
BA_ "SysSignalName" SG_ 2164729104 ChAEBBrkJerkReqResp "ChAEBBrkJerkReqResp";
BA_ "CompuMethodName" SG_ 2164729104 SCSAutodDrvngSysSts "SCSAutodDrvngSysSts";
BA_ "ISignalName" SG_ 2164729104 SCSAutodDrvngSysSts "ISCSAutodDrvngSysSts";
BA_ "LongName" SG_ 2164729104 SCSAutodDrvngSysSts "Stability Control System Automated Driving System Status";
BA_ "SysSignalName" SG_ 2164729104 SCSAutodDrvngSysSts "SCSAutodDrvngSysSts";
BA_ "CompuMethodName" SG_ 2164729104 SCSAPAAcclAV "SCSAPAAcclAV";
BA_ "ISignalName" SG_ 2164729104 SCSAPAAcclAV "ISCSAPAAcclAV";
BA_ "LongName" SG_ 2164729104 SCSAPAAcclAV "Stability Control System Advanced Park Assist Acceleration Active Validity";
BA_ "SysSignalName" SG_ 2164729104 SCSAPAAcclAV "SCSAPAAcclAV";
BA_ "CompuMethodName" SG_ 2164729104 SCSAPAAcclA "SCSAPAAcclA";
BA_ "ISignalName" SG_ 2164729104 SCSAPAAcclA "ISCSAPAAcclA";
BA_ "LongName" SG_ 2164729104 SCSAPAAcclA "Stability Control System Advanced Park Assist Acceleration Active";
BA_ "SysSignalName" SG_ 2164729104 SCSAPAAcclA "SCSAPAAcclA";
BA_ "CompuMethodName" SG_ 2164729104 ExtnlBrkPrioV "ExtnlBrkPrioV";
BA_ "ISignalName" SG_ 2164729104 ExtnlBrkPrioV "IExtnlBrkPrioV";
BA_ "LongName" SG_ 2164729104 ExtnlBrkPrioV "External Brake Priority Validity";
BA_ "SysSignalName" SG_ 2164729104 ExtnlBrkPrioV "ExtnlBrkPrioV";
BA_ "CompuMethodName" SG_ 2164729104 ExtnlBrkPrio "ExtnlBrkPrio";
BA_ "ISignalName" SG_ 2164729104 ExtnlBrkPrio "IExtnlBrkPrio";
BA_ "LongName" SG_ 2164729104 ExtnlBrkPrio "External Brake Priority";
BA_ "SysSignalName" SG_ 2164729104 ExtnlBrkPrio "ExtnlBrkPrio";
BA_ "CompuMethodName" SG_ 2164729104 EmgcBrkReqdByIECUSts "EmgcBrkReqdByIECUSts";
BA_ "ISignalName" SG_ 2164729104 EmgcBrkReqdByIECUSts "IEmgcBrkReqdByIECUSts";
BA_ "LongName" SG_ 2164729104 EmgcBrkReqdByIECUSts "Emergency_Brake_Requested_By_Intelligent_Electric_Control_Unit_Status";
BA_ "SysSignalName" SG_ 2164729104 EmgcBrkReqdByIECUSts "EmgcBrkReqdByIECUSts";
BA_ "CompuMethodName" SG_ 2164729104 TCSDrvrItnt "TCSDrvrItnt";
BA_ "ISignalName" SG_ 2164729104 TCSDrvrItnt "ITCSDrvrItnt";
BA_ "LongName" SG_ 2164729104 TCSDrvrItnt "Traction_Control_System_Driver_Intent";
BA_ "SysSignalName" SG_ 2164729104 TCSDrvrItnt "TCSDrvrItnt";
BA_ "CompuMethodName" SG_ 2164729104 MultColBrkAvlblySts "MultColBrkAvlblySts";
BA_ "ISignalName" SG_ 2164729104 MultColBrkAvlblySts "IMultColBrkAvlblySts";
BA_ "LongName" SG_ 2164729104 MultColBrkAvlblySts "Multi_Collision_Brake_Availability_Status";
BA_ "SysSignalName" SG_ 2164729104 MultColBrkAvlblySts "MultColBrkAvlblySts";
BA_ "CompuMethodName" SG_ 2164729104 ChRCTBDclReqResp "ChRCTBDclReqResp";
BA_ "ISignalName" SG_ 2164729104 ChRCTBDclReqResp "IChRCTBDclReqResp";
BA_ "LongName" SG_ 2164729104 ChRCTBDclReqResp "Chassis Rear Cross Traffic Braking Deceleration Request Response";
BA_ "SysSignalName" SG_ 2164729104 ChRCTBDclReqResp "ChRCTBDclReqResp";
BA_ "CompuMethodName" SG_ 2164729104 SCSVehHoldAV "SCSVehHoldAV";
BA_ "ISignalName" SG_ 2164729104 SCSVehHoldAV "ISCSVehHoldAV";
BA_ "LongName" SG_ 2164729104 SCSVehHoldAV "Stability Control System Vehicle Hold A Validity";
BA_ "SysSignalName" SG_ 2164729104 SCSVehHoldAV "SCSVehHoldAV";
BA_ "CompuMethodName" SG_ 2164729104 SCSVehHoldA "SCSVehHoldA";
BA_ "ISignalName" SG_ 2164729104 SCSVehHoldA "ISCSVehHoldA";
BA_ "LongName" SG_ 2164729104 SCSVehHoldA "Stability Control System Vehicle Hold Active";
BA_ "SysSignalName" SG_ 2164729104 SCSVehHoldA "SCSVehHoldA";
BA_ "CompuMethodName" SG_ 2164729104 SCSAutodDrvngSysStsV "SCSAutodDrvngSysStsV";
BA_ "ISignalName" SG_ 2164729104 SCSAutodDrvngSysStsV "ISCSAutodDrvngSysStsV";
BA_ "LongName" SG_ 2164729104 SCSAutodDrvngSysStsV "Stability Control System Automated Driving System Status Validity";
BA_ "SysSignalName" SG_ 2164729104 SCSAutodDrvngSysStsV "SCSAutodDrvngSysStsV";
BA_ "CompuMethodName" SG_ 2164729104 VehSdslStsV "VehSdslStsV";
BA_ "ISignalName" SG_ 2164729104 VehSdslStsV "IVehSdslStsV";
BA_ "LongName" SG_ 2164729104 VehSdslStsV "Vehicle Standstill Status Valid";
BA_ "SysSignalName" SG_ 2164729104 VehSdslStsV "VehSdslStsV";
BA_ "CompuMethodName" SG_ 2164729104 ChRCTBPrflReqResp "ChRCTBPrflReqResp";
BA_ "ISignalName" SG_ 2164729104 ChRCTBPrflReqResp "IChRCTBPrflReqResp";
BA_ "LongName" SG_ 2164729104 ChRCTBPrflReqResp "Chassis Rear Cross Traffic Braking Prefill Request Response";
BA_ "SysSignalName" SG_ 2164729104 ChRCTBPrflReqResp "ChRCTBPrflReqResp";
BA_ "CompuMethodName" SG_ 2164729104 WhlBrkPrsSts "WhlBrkPrsSts";
BA_ "GenSigStartValue" SG_ 2164729104 WhlBrkPrsSts 1;
BA_ "ISignalName" SG_ 2164729104 WhlBrkPrsSts "IWhlBrkPrsSts";
BA_ "LongName" SG_ 2164729104 WhlBrkPrsSts "Wheel Brake Pressure Status";
BA_ "SysSignalName" SG_ 2164729104 WhlBrkPrsSts "WhlBrkPrsSts";
BA_ "CompuMethodName" SG_ 2164729104 BrkSysRddySysSts "BrkSysRddySysSts";
BA_ "ISignalName" SG_ 2164729104 BrkSysRddySysSts "IBrkSysRddySysSts";
BA_ "LongName" SG_ 2164729104 BrkSysRddySysSts "Brake Redundancy System Status";
BA_ "SysSignalName" SG_ 2164729104 BrkSysRddySysSts "BrkSysRddySysSts";
BA_ "CompuMethodName" SG_ 2164729104 VehSdslSts "VehSdslSts";
BA_ "ISignalName" SG_ 2164729104 VehSdslSts "IVehSdslSts";
BA_ "LongName" SG_ 2164729104 VehSdslSts "Vehicle Standstill Status";
BA_ "SysSignalName" SG_ 2164729104 VehSdslSts "VehSdslSts";
BA_ "CompuMethodName" SG_ 2164729104 ChEBADclReqResp "ChEBADclReqResp";
BA_ "ISignalName" SG_ 2164729104 ChEBADclReqResp "IChEBADclReqResp";
BA_ "SysSignalName" SG_ 2164729104 ChEBADclReqResp "ChEBADclReqResp";
BA_ "CompuMethodName" SG_ 2164729104 IBSAPASysFltSts "IBSAPASysFltSts";
BA_ "ISignalName" SG_ 2164729104 IBSAPASysFltSts "IIBSAPASysFltSts";
BA_ "LongName" SG_ 2164729104 IBSAPASysFltSts "Ibs Apa System Fault Status";
BA_ "SysSignalName" SG_ 2164729104 IBSAPASysFltSts "IBSAPASysFltSts";
VAL_ 81 TJAICASysFltSts 0 "TJAICASysFltSts_0_noerror" 1 "TJAICASysFltSts_1_performancedegradation" 2 "TJAICASysFltSts_2_systemtemporaryunavailable" 3 "TJAICASysFltSts_3_servicerequired" 4 "TJAICASysFltSts_4_Reserved" 5 "TJAICASysFltSts_5_Reserved" 6 "TJAICASysFltSts_6_Reserved" 7 "TJAICASysFltSts_7_Reserved";
VAL_ 81 ACCToqReqSts 0 "ACCToqReqSts_0__No_request" 1 "ACCToqReqSts_1__Torque_request_request" 2 "ACCToqReqSts_2_Reserved1" 3 "ACCToqReqSts_3_Reserved2";
VAL_ 81 LKASysFltSts 0 "LKASysFltSts_0_noerror" 1 "LKASysFltSts_1_performancedegradation" 2 "LKASysFltSts_2_systemtemporaryunavailable" 3 "LKASysFltSts_3_servicerequired";
VAL_ 81 TJAICASysSts 0 "TJAICASysSts_0_Off" 1 "TJAICASysSts_1_Standby" 2 "TJAICASysSts_2_Active" 3 "TJAICASysSts_3_Override" 4 "TJAICASysSts_4_Passive" 5 "TJAICASysSts_5_Degradation" 6 "TJAICASysSts_6_SafeStop" 7 "TJAICASysSts_7_Prohibition";
VAL_ 81 LKASysSts 0 "LKASysSts_0_Off" 1 "LKASysSts_1_Standby" 2 "LKASysSts_2_Active" 3 "LKASysSts_3_Override" 4 "LKASysSts_4_Active_no_warning";
VAL_ 807 TSRTrgtWarnSign 0 "TSRTrgtWarnSign_0_NoSign" 1 "TSRTrgtWarnSign_1_Dangerous_road_by_mountain_Right" 2 "TSRTrgtWarnSign_2_Dangerous_road_by_mountain_Left" 3 "TSRTrgtWarnSign_3_Town" 4 "TSRTrgtWarnSign_4_Dike_Road_Right" 5 "TSRTrgtWarnSign_5_Dike_Road_Left" 6 "TSRTrgtWarnSign_6_T_Crossover" 7 "TSRTrgtWarnSign_7_Ferry" 8 "TSRTrgtWarnSign_8_Narrowing" 9 "TSRTrgtWarnSign_9_Falling_Rocks_Left" 10 "TSRTrgtWarnSign_10_ReverseCurveL" 11 "TSRTrgtWarnSign_11_ReverseCurveR" 12 "TSRTrgtWarnSign_12_Waterway" 13 "TSRTrgtWarnSign_13_Crossroad" 14 "TSRTrgtWarnSign_14_Intersection" 15 "TSRTrgtWarnSign_15_Y_Crossing_LR" 16 "TSRTrgtWarnSign_16_Y_Crossing_RR" 17 "TSRTrgtWarnSign_17_Y_Crossing_LF" 18 "TSRTrgtWarnSign_18_Narrowing_Left" 19 "TSRTrgtWarnSign_19_Y_Crossing_RF" 20 "TSRTrgtWarnSign_20_T_Intersection" 21 "TSRTrgtWarnSign_21_T_Intersection_Left" 22 "TSRTrgtWarnSign_22_T_Intersection_Right" 23 "TSRTrgtWarnSign_23_Roundabout" 24 "TSRTrgtWarnSign_24_ContinuousBend" 25 "TSRTrgtWarnSign_25_ContinuousDownhill" 26 "TSRTrgtWarnSign_26_Uneven" 27 "TSRTrgtWarnSign_27_Rain" 28 "TSRTrgtWarnSign_28_Low_lying_Road" 29 "TSRTrgtWarnSign_29_Convex_Road" 30 "TSRTrgtWarnSign_30_Slow" 31 "TSRTrgtWarnSign_31_Uphill" 32 "TSRTrgtWarnSign_32_WarnWorks" 33 "TSRTrgtWarnSign_33_Cross_Plane" 34 "TSRTrgtWarnSign_34_AccidentProneSection" 35 "TSRTrgtWarnSign_35_Two_way_traffic" 36 "TSRTrgtWarnSign_36_WarnWildanimal" 37 "TSRTrgtWarnSign_37_Tunnel" 38 "TSRTrgtWarnSign_38_lightingIntoTunnel" 39 "TSRTrgtWarnSign_39_Arched_bridge" 40 "TSRTrgtWarnSign_40_Unguarded_railway_crossing" 41 "TSRTrgtWarnSign_41_Downhill" 42 "TSRTrgtWarnSign_42_SharpTurnR" 43 "TSRTrgtWarnSign_43_SharpTurnL" 44 "TSRTrgtWarnSign_44_Easy_slide" 45 "TSRTrgtWarnSign_45_Traffic_Light" 46 "TSRTrgtWarnSign_46_Guarded_railway_crossing" 47 "TSRTrgtWarnSign_47_Narrowing_Right" 48 "TSRTrgtWarnSign_48_Passfromright" 49 "TSRTrgtWarnSign_49_Narrow_bridge" 50 "TSRTrgtWarnSign_50_Maintaindistance" 51 "TSRTrgtWarnSign_51_ThunderStorm" 52 "TSRTrgtWarnSign_52_Warn_handicapped" 53 "TSRTrgtWarnSign_53_Tidal_driveway" 54 "TSRTrgtWarnSign_54_Fog" 55 "TSRTrgtWarnSign_55_WarnKids" 56 "TSRTrgtWarnSign_56_WarnBike" 57 "TSRTrgtWarnSign_57_WarnPed" 58 "TSRTrgtWarnSign_58_ConfluenceL" 59 "TSRTrgtWarnSign_59_ConfluenceR" 60 "TSRTrgtWarnSign_60_WarnCrosswind" 61 "TSRTrgtWarnSign_61_Snow" 62 "TSRTrgtWarnSign_62_Falling_Rocks_Right" 63 "TSRTrgtWarnSign_63_WarnRisk" 64 "TSRTrgtWarnSign_64_WarnCattle" 65 "TSRTrgtWarnSign_65_Passfromleft" 66 "TSRTrgtWarnSign_66_Passfromleftright" 67 "TSRTrgtWarnSign_67_Warnqueue" 68 "TSRTrgtWarnSign_68_SpeedHump" 69 "TSRTrgtWarnSign_69_AccidentManagement" 70 "TSRTrgtWarnSign_70_IcyRoad";
VAL_ 807 TSRTrgtBanSign 0 "TSRTrgtBanSign_0_NoSign" 1 "TSRTrgtBanSign_1_NoOvertake" 2 "TSRTrgtBanSign_2_NoAnimalPowerVehicle" 3 "TSRTrgtBanSign_3_NoBus" 4 "TSRTrgtBanSign_4_NoElectricTricycle" 5 "TSRTrgtBanSign_5_NoTurnaround" 6 "TSRTrgtBanSign_6_NoBicycle" 7 "TSRTrgtBanSign_7_NoTruckLeft" 8 "TSRTrgtBanSign_8_NoTrailer" 9 "TSRTrgtBanSign_9_NoWalkers" 10 "TSRTrgtBanSign_10_NoCar" 11 "TSRTrgtBanSign_11_NoWhistle" 12 "TSRTrgtBanSign_12_NoMotorcycle" 13 "TSRTrgtBanSign_13_NoObjectshown" 14 "TSRTrgtBanSign_14_NoStraight" 15 "TSRTrgtBanSign_15_NoRickshaw" 16 "TSRTrgtBanSign_16_NoHumanpoweredtrucks" 17 "TSRTrgtBanSign_17_NoHumanpoweredtricycles" 18 "TSRTrgtBanSign_18_NoTractor" 19 "TSRTrgtBanSign_19_NoRightTurn" 20 "TSRTrgtBanSign_20_NoLeftRightTurn" 21 "TSRTrgtBanSign_21_NoStraightRightTurn" 22 "TSRTrgtBanSign_22_NolowSpeedtruck" 23 "TSRTrgtBanSign_23_NoLeftTurn" 24 "TSRTrgtBanSign_24_NoCarTurnRight" 25 "TSRTrgtBanSign_25_NoCar" 26 "TSRTrgtBanSign_26_NoTruck" 27 "TSRTrgtBanSign_27_NoDangerousgoodvehicle" 28 "TSRTrgtBanSign_28_NoStraightLeftTurn" 29 "TSRTrgtBanSign_29_Quality_Limit" 30 "TSRTrgtBanSign_30_Axle_load_Limit" 31 "TSRTrgtBanSign_31_Custom" 32 "TSRTrgtBanSign_32_Check" 33 "TSRTrgtBanSign_33_NoParking" 34 "TSRTrgtBanSign_34_NoLongParking" 35 "TSRTrgtBanSign_35_Higth_limit_350cm" 36 "TSRTrgtBanSign_36_Width_limit_300cm" 37 "TSRTrgtBanSign_37_StopGiveWay" 38 "TSRTrgtBanSign_38_GiveWay" 39 "TSRTrgtBanSign_38_NoPass" 40 "TSRTrgtBanSign_40_OncomingGiveWay" 41 "TSRTrgtBanSign_41_NoEntry" 42 "TSRTrgtBanSign_42_RelieveNoOvertake";
VAL_ 807 TSRSwReqResp 0 "TSRSwReqResp_0_Unavailable" 1 "TSRSwReqResp_1_Off" 2 "TSRSwReqResp_2_On";
VAL_ 807 SLIFSts_IPD 0 "SLIFSts_IPD_0_Off" 1 "SLIFSts_IPD_1_Active" 2 "SLIFSts_IPD_2_Overspeed" 3 "SLIFSts_IPD_3_Standby" 4 "SLIFSts_IPD_4_Fault";
VAL_ 807 TSRSts 0 "TSRSts_0_Off" 1 "TSRSts_1_Active" 3 "TSRSts_3_Standby" 4 "TSRSts_4_Fault";
VAL_ 807 PilotSysAVCamrF1FltSts 0 "PilotSysAVCamrF1FltSts_0_NoError" 1 "PilotSysAVCamrF1FltSts_1_BlockError" 2 "PilotSysAVCamrF1FltSts_2_SystemTemporaryUnvailable" 3 "PilotSysAVCamrF1FltSts_3_ServiceRequired" 4 "PilotSysAVCamrF1FltSts_4_Reserved";
VAL_ 807 PilotSysADASFltSts 0 "PilotSysADASFltSts_0_NoError" 1 "PilotSysADASFltSts_1_TemporaryError" 2 "PilotSysADASFltSts_2_PermanentError" 3 "PilotSysADASFltSts_3_SensorBlockError" 4 "PilotSysADASFltSts_4_SensorTemporaryError" 5 "PilotSysADASFltSts_5_SensorPermanentError" 6 "PilotSysADASFltSts_6_Reserved" 7 "PilotSysADASFltSts_7_Reserved";
VAL_ 807 AIParkngSSPLotSwSts 0 "AIParkngSSPLotSwSts_0_no_reqest" 1 "AIParkngSSPLotSwSts_1_Off" 2 "AIParkngSSPLotSwSts_2_On";
VAL_ 807 PilotSysAVCamrRFltSts 0 "PilotSysAVCamrRFltSts_0_NoError" 1 "PilotSysAVCamrRFltSts_1_BlockError" 2 "PilotSysAVCamrRFltSts_2_SystemTemporaryUnvailable" 3 "PilotSysAVCamrRFltSts_3_ServiceRequired" 4 "PilotSysAVCamrRFltSts_4_Reserved";
VAL_ 807 PilotSysAVCamrF3FltSts 0 "PilotSysAVCamrF3FltSts_0_NoError" 1 "PilotSysAVCamrF3FltSts_1_BlockError" 2 "PilotSysAVCamrF3FltSts_2_SystemTemporaryUnvailable" 3 "PilotSysAVCamrF3FltSts_3_ServiceRequired" 4 "PilotSysAVCamrF3FltSts_4_Reserved";
VAL_ 807 PilotSysAVCamrFRSFltSts 0 "PilotSysAVCamrFRSFltSts_0_NoError" 1 "PilotSysAVCamrFRSFltSts_1_BlockError" 2 "PilotSysAVCamrFRSFltSts_2_SystemTemporaryUnvailable" 3 "PilotSysAVCamrFRSFltSts_3_ServiceRequired" 4 "PilotSysAVCamrFRSFltSts_4_Reserved";
VAL_ 807 PilotSysAVCamrFLSFltSts 0 "PilotSysAVCamrFLSFltSts_0_NoError" 1 "PilotSysAVCamrFLSFltSts_1_BlockError" 2 "PilotSysAVCamrFLSFltSts_2_SystemTemporaryUnvailable" 3 "PilotSysAVCamrFLSFltSts_3_ServiceRequired" 4 "PilotSysAVCamrFLSFltSts_4_Reserved";
VAL_ 807 PilotSysAVCamrRRSFltSts 0 "PilotSysAVCamrRRSFltSts_0_NoError" 1 "PilotSysAVCamrRRSFltSts_1_BlockError" 2 "PilotSysAVCamrRRSFltSts_2_SystemTemporaryUnvailable" 3 "PilotSysAVCamrRRSFltSts_3_ServiceRequired" 4 "PilotSysAVCamrRRSFltSts_4_Reserved";
VAL_ 807 PilotSysAVCamrRLSFltSts 0 "PilotSysAVCamrRLSFltSts_0_NoError" 1 "PilotSysAVCamrRLSFltSts_1_BlockError" 2 "PilotSysAVCamrRLSFltSts_2_SystemTemporaryUnvailable" 3 "PilotSysAVCamrRLSFltSts_3_ServiceRequired" 4 "PilotSysAVCamrRLSFltSts_4_Reserved";
VAL_ 807 PilotSysHDAVMCamrRFltSts 0 "PilotSysHDAVMCamrRFltSts_0_NoError" 1 "PilotSysHDAVMCamrRFltSts_1_BlockError" 2 "PilotSysHDAVMCamrRFltSts_2_SystemTemporaryUnvailable" 3 "PilotSysHDAVMCamrRFltSts_3_ServiceRequired" 4 "PilotSysHDAVMCamrRFltSts_4_Reserved";
VAL_ 807 PilotSysHDAVMCamrFFltSts 0 "PilotSysHDAVMCamrFFltSts_0_NoError" 1 "PilotSysHDAVMCamrFFltSts_1_BlockError" 2 "PilotSysHDAVMCamrFFltSts_2_SystemTemporaryUnvailable" 3 "PilotSysHDAVMCamrFFltSts_3_ServiceRequired" 4 "PilotSysHDAVMCamrFFltSts_4_Reserved";
VAL_ 807 PilotSysHDAVMCamrRHFltSts 0 "PilotSysHDAVMCamrRHFltSts_0_NoError" 1 "PilotSysHDAVMCamrRHFltSts_1_BlockError" 2 "PilotSysHDAVMCamrRHFltSts_2_SystemTemporaryUnvailable" 3 "PilotSysHDAVMCamrRHFltSts_3_ServiceRequired" 4 "PilotSysHDAVMCamrRHFltSts_4_Reserved";
VAL_ 807 PilotSysHDAVMCamrLHFltSts 0 "PilotSysHDAVMCamrLHFltSts_0_NoError" 1 "PilotSysHDAVMCamrLHFltSts_1_BlockError" 2 "PilotSysHDAVMCamrLHFltSts_2_SystemTemporaryUnvailable" 3 "PilotSysHDAVMCamrLHFltSts_3_ServiceRequired" 4 "PilotSysHDAVMCamrLHFltSts_4_Reserved";
VAL_ 807 SLIFWrnngMdResp 0 "SLIFWrnngMdResp_0__Unavailable" 1 "SLIFWrnngMdResp_1__Off" 2 "SLIFWrnngMdResp_2__Visual" 3 "SLIFWrnngMdResp_3___Audible";
VAL_ 807 PilotSysLFSDAFltSts 0 "PilotSysLFSDAFltSts_0_NoError" 1 "PilotSysLFSDAFltSts_1_BlockError" 2 "PilotSysLFSDAFltSts_2_SystemTemporaryUnvailable" 3 "PilotSysLFSDAFltSts_3_ServiceRequired" 4 "PilotSysLFSDAFltSts_4_Reserved";
VAL_ 807 PilotSysFDRFltSts 0 "PilotSysFDRFltSts_0_NoError" 1 "PilotSysFDRFltSts_1_BlockError" 2 "PilotSysFDRFltSts_2_SystemTemporaryUnvailable" 3 "PilotSysFDRFltSts_3_ServiceRequired" 4 "PilotSysFDRFltSts_4_Reserved";
VAL_ 807 TrgtSpdSrcSts_IPD 0 "TrgtSpdSrcSts_IPD_0_Undefined" 1 "TrgtSpdSrcSts_IPD_1_Camera" 2 "TrgtSpdSrcSts_IPD_2_Navigation" 3 "TrgtSpdSrcSts_IPD_3_Fault";
VAL_ 807 PilotSysLHRDAFltSts 0 "PilotSysLHRDAFltSts_0_NoError" 1 "PilotSysLHRDAFltSts_1_BlockError" 2 "PilotSysLHRDAFltSts_2_SystemTemporaryUnvailable" 3 "PilotSysLHRDAFltSts_3_ServiceRequired" 4 "PilotSysLHRDAFltSts_4_Reserved";
VAL_ 807 PilotSysRFSDAFltSts 0 "PilotSysRFSDAFltSts_0_NoError" 1 "PilotSysRFSDAFltSts_1_BlockError" 2 "PilotSysRFSDAFltSts_2_SystemTemporaryUnvailable" 3 "PilotSysRFSDAFltSts_3_ServiceRequired" 4 "PilotSysRFSDAFltSts_4_Reserved";
VAL_ 807 SLIFAudWrnng_IPD 0 "SLIFAudWrnng_IPD_0__False" 1 "SLIFAudWrnng_IPD_1__True";
VAL_ 807 SLIFUpdtInd_IPD 0 "SLIFUpdtInd_IPD_0__False" 1 "SLIFUpdtInd_IPD_1__True";
VAL_ 807 PilotSysFLIDARFltSts 0 "PilotSysFLIDARFltSts_0_NoError" 1 "PilotSysFLIDARFltSts_1_BlockError" 2 "PilotSysFLIDARFltSts_2_SystemTemporaryUnvailable" 3 "PilotSysFLIDARFltSts_3_ServiceRequired" 4 "PilotSysFLIDARFltSts_4_Reserved";
VAL_ 807 PilotSysRHRDAFltSts 0 "PilotSysRHRDAFltSts_0_NoError" 1 "PilotSysRHRDAFltSts_1_BlockError" 2 "PilotSysRHRDAFltSts_2_SystemTemporaryUnvailable" 3 "PilotSysRHRDAFltSts_3_ServiceRequired" 4 "PilotSysRHRDAFltSts_4_Reserved";
VAL_ 807 PilotSysUSSFltSts 0 "PilotSysUSSFltSts_0_NoError" 1 "PilotSysUSSFltSts_1_BlockError" 2 "PilotSysUSSFltSts_2_SystemTemporaryUnvailable" 3 "PilotSysUSSFltSts_3_ServiceRequired" 4 "PilotSysUSSFltSts_4_Reserved";
VAL_ 807 HORWarningEvtSts 0 "HORWarningEvtSts_0_default" 1 "HORWarningEvtSts_1_HORForbiddenPilot";
VAL_ 807 EORWarningEvtSts 0 "EORWarningEvtSts_0_default" 1 "EORWarningEvtSts_1_EORForbiddenPilot";
VAL_ 807 PosALCFailed 0 "PosALCFailed_0_default" 1 "PosALCFailed_1_PositiveALCFailed";
VAL_ 807 SLIFSysFltSts 0 "SLIFSysFltSts_0_NoError" 1 "SLIFSysFltSts_1_PerformanceDegradation" 2 "SLIFSysFltSts_2_SystemTemporaryUnavailable" 3 "SLIFSysFltSts_3_ServiceRequired";
VAL_ 807 ADS_ISAMsgReq 0 "ADS_ISAMsgReq_0_Nowarning" 1 "ADS_ISAMsgReq_1_MSG1" 2 "ADS_ISAMsgReq_2_MSG2" 3 "ADS_ISAMsgReq_3_MSG3" 4 "ADS_ISAMsgReq_4_MSG4" 5 "ADS_ISAMsgReq_5_MSG5" 6 "ADS_ISAMsgReq_6_MSG6" 7 "ADS_ISAMsgReq_7_MSG7" 8 "ADS_ISAMsgReq_8_MSG8" 9 "ADS_ISAMsgReq_9_MSG9";
VAL_ 807 SLIFUpdtIndResp_IPD 0 "SLIFUpdtIndResp_IPD_0_Unavailable" 1 "SLIFUpdtIndResp_IPD_1_Off" 2 "SLIFUpdtIndResp_IPD_2_On" 3 "SLIFUpdtIndResp_IPD_3_reserve";
VAL_ 807 ADS_ISASysFltSts 0 "ADS_ISASysFltSts_0_NoError" 1 "ADS_ISASysFltSts_1_PerformanceDegradation" 2 "ADS_ISASysFltSts_2_SystemTemporaryUnavailable" 3 "ADS_ISASysFltSts_3_ServiceRequired";
VAL_ 807 ADS_ISASysSts 0 "ADS_ISASysSts_0_Off" 1 "ADS_ISASysSts_1_Passive" 2 "ADS_ISASysSts_2_Active" 3 "ADS_ISASysSts_3_Overspeed" 4 "ADS_ISASysSts_4_Standby" 5 "ADS_ISASysSts_5_Fault" 6 "ADS_ISASysSts_6_reserve" 7 "ADS_ISASysSts_7_reserve";
VAL_ 807 ParkngSpdSwResp 0 "ParkngSpdSwResp_0_Default" 1 "ParkngSpdSwResp_1_LowSpeed" 2 "ParkngSpdSwResp_2_MiddleSpeed" 3 "ParkngSpdSwResp_3_HighSpeed";
VAL_ 486 FrtCarGoNotfr 0 "FrtCarGoNotfr_0_False" 1 "FrtCarGoNotfr_1_Waminglevel1" 2 "FrtCarGoNotfr_2_Warninglevel2" 3 "FrtCarGoNotfr_3_Warninglevel3";
VAL_ 486 ACCSysFltSts_SCS 0 "ACCSysFltSts_SCS_0_NoError" 1 "ACCSysFltSts_SCS_1_PerformanceDegradation" 2 "ACCSysFltSts_SCS_2_SystemTemporaryUnvailable" 3 "ACCSysFltSts_SCS_3_ServiceRequired" 4 "ACCSysFltSts_SCS_4_Reserved" 5 "ACCSysFltSts_SCS_5_Reserved" 6 "ACCSysFltSts_SCS_6_Reserved" 7 "ACCSysFltSts_SCS_7_Reserved";
VAL_ 337 AutoLaneChngRLaneSts 0 "AutoLaneChngRLaneSts_0_NoRequest" 1 "AutoLaneChngRLaneSts_1_LaneChangeInhibit" 2 "AutoLaneChngRLaneSts_2_WaitingForLaneChangeStarting" 3 "AutoLaneChngRLaneSts_3_LaneChangeInProgress" 4 "AutoLaneChngRLaneSts_4_LaneChangeSucces" 5 "AutoLaneChngRLaneSts_5_LaneChangeFailed" 6 "AutoLaneChngRLaneSts_6_LaneChangeSuppressByDriver" 7 "AutoLaneChngRLaneSts_7_ReturnToEgoLaneByDriver" 8 "AutoLaneChngRLaneSts_8_ReturnToEgoLaneByAlc" 9 "AutoLaneChngRLaneSts_9_LaneChangeManoeuvreWithRisk" 10 "AutoLaneChngRLaneSts_10_ReturnToEgoLaneSuccess" 11 "AutoLaneChngRLaneSts_11_WaitingForALCBecauseVehicleSpeedTooLow" 12 "AutoLaneChngRLaneSts_12_WaitingForALCBecauseVehicleSpeedTooHigh" 13 "AutoLaneChngRLaneSts_13_Vehiclegothroughthelane";
VAL_ 337 ESSDirInd 0 "ESSDirInd_0_Unactive" 1 "ESSDirInd_1_Left" 2 "ESSDirInd_2_Right" 3 "ESSDirInd_3_reserved";
VAL_ 337 PilotTkovMsgReq 0 "PilotTkovMsgReq_0_NoDisplay" 1 "PilotTkovMsgReq_1__1" 2 "PilotTkovMsgReq_2__2" 3 "PilotTkovMsgReq_3__3" 4 "PilotTkovMsgReq_4__4" 5 "PilotTkovMsgReq_5__5" 6 "PilotTkovMsgReq_6__6" 7 "PilotTkovMsgReq_7__7" 8 "PilotTkovMsgReq_8__8" 9 "PilotTkovMsgReq_9__9" 10 "PilotTkovMsgReq_10__10" 11 "PilotTkovMsgReq_11__11" 12 "PilotTkovMsgReq_12__12" 13 "PilotTkovMsgReq_13__12" 14 "PilotTkovMsgReq_14__14" 15 "PilotTkovMsgReq_15__15";
VAL_ 337 NOPSysSts_ZPD 0 "NOPSysSts_ZPD_0_Off" 1 "NOPSysSts_ZPD_1_Passive" 2 "NOPSysSts_ZPD_2_Standby" 3 "NOPSysSts_ZPD_3_HandsOn_active" 4 "NOPSysSts_ZPD_4_HandsFree_active" 5 "NOPSysSts_ZPD_5_Wait_for_driver_to_confirm" 6 "NOPSysSts_ZPD_6_ALC_Active" 7 "NOPSysSts_ZPD_7_Override" 8 "NOPSysSts_ZPD_8_TOR" 9 "NOPSysSts_ZPD_9_Prohibit" 10 "NOPSysSts_ZPD_10_Fault" 11 "NOPSysSts_ZPD_11_SafeStop";
VAL_ 337 PrkgDstCtrlSwResp 0 "PrkgDstCtrlSwResp_0_Unavailable" 1 "PrkgDstCtrlSwResp_1_ON" 2 "PrkgDstCtrlSwResp_2_OFF";
VAL_ 337 ALCSysSts 0 "ALCSysSts_0_Off" 1 "ALCSysSts_1_Standby" 2 "ALCSysSts_2_ActiveRequest" 3 "ALCSysSts_3_ActiveControl" 4 "ALCSysSts_4_Passive" 5 "ALCSysSts_5_LaneChangeReturning" 6 "ALCSysSts_6_TOR" 7 "ALCSysSts_7_Reserve";
VAL_ 337 ALCSysFltSts 0 "ALCSysFltSts_0_No_error" 1 "ALCSysFltSts_1_Performance_degradation" 2 "ALCSysFltSts_2_System_temporary_unavailable" 3 "ALCSysFltSts_3_Service_required" 4 "ALCSysFltSts_4_Reserved";
VAL_ 337 AutoLaneChngLLaneSts 0 "AutoLaneChngLLaneSts_0_NoRequest" 1 "AutoLaneChngLLaneSts_1_LaneChangeInhibit" 2 "AutoLaneChngLLaneSts_2_WaitingForLaneChangeStarting" 3 "AutoLaneChngLLaneSts_3_LaneChangeInProgress" 4 "AutoLaneChngLLaneSts_4_LaneChangeSucces" 5 "AutoLaneChngLLaneSts_5_LaneChangeFailed" 6 "AutoLaneChngLLaneSts_6_LaneChangeSuppressByDriver" 7 "AutoLaneChngLLaneSts_7_ReturnToEgoLaneByDriver" 8 "AutoLaneChngLLaneSts_8_ReturnToEgoLaneByAlc" 9 "AutoLaneChngLLaneSts_9_LaneChangeManoeuvreWithRisk" 10 "AutoLaneChngLLaneSts_10_ReturnToEgoLaneSuccess" 11 "AutoLaneChngRLaneSts_11_WaitingForALCBecauseVehicleSpeedTooLow" 12 "AutoLaneChngRLaneSts_12_WaitingForALCBecauseVehicleSpeedTooHigh" 13 "AutoLaneChngRLaneSts_13_Vehiclegothroughthelane";
VAL_ 337 ESSSysSts 0 "ESSSysSts_0_Off" 1 "ESSSysSts_1_StandBy" 2 "ESSSysSts_2_Passive" 3 "ESSSysSts_3_Active" 4 "ESSSysSts_4_Disable" 5 "ESSSysSts_5_reserved" 6 "ESSSysSts_6_reserved";
VAL_ 337 ESSSysFltSts 0 "ESSSysFltSts_0_NoError" 1 "ESSSysFltSts_1_PerformanceDegradation" 2 "ESSSysFltSts_2_SystemTemporaryUnvailable" 3 "ESSSysFltSts_3_ServiceRequired" 4 "ESSSysFltSts_4_Reserved" 5 "ESSSysFltSts_5_Reserved" 6 "ESSSysFltSts_6_Reserved" 7 "ESSSysFltSts_7_Reserved";
VAL_ 337 ESSDrvrTkovReq 0 "ESSDrvrTkovReq_0_False" 1 "ESSDrvrTkovReq_1_True";
VAL_ 337 Parkngslottype 0 "ParkngSlotType_0__null" 1 "ParkngSlotType_1_left_vertical" 2 "ParkngSlotType_2_left_parallel" 3 "ParkngSlotType_3_right_vertical" 4 "ParkngSlotType_4_right_parallel";
VAL_ 337 NOPSysFltSts 0 "NOPSysFltSts_0_No_error" 1 "NOPSysFltSts_1_Performance_degradation" 2 "NOPSysFltSts_2_System_temporary_unavailable" 3 "NOPSysFltSts_3_Service_required" 4 "NOPSysFltSts_4_Reserved";
VAL_ 733 KeepPwrRsnIPD 0 "KeepPwrRsnIPD_0_Unknown" 1 "KeepPwrRsnIPD_1_Off" 2 "KeepPwrRsnIPD_2_On" 3 "KeepPwrRsnIPD_3__LPM_SnsrOff" 4 "KeepPwrRsnIPD_4_SnsrOff" 5 "KeepPwrRsnIPD_5_Reserved" 6 "KeepPwrRsnIPD_6_Reserved" 7 "KeepPwrRsnIPD_7_Reserved" 8 "KeepPwrRsnIPD_8_Reserved" 9 "KeepPwrRsnIPD_9_GoingDown" 10 "KeepPwrRsnIPD_10_off_SuperECO" 11 "KeepPwrRsnIPD_11_Reserved" 12 "KeepPwrRsnIPD_12_Reserved" 13 "KeepPwrRsnIPD_13_Reserved" 14 "KeepPwrRsnIPD_14_Reserved" 15 "KeepPwrRsnIPD_15_Reserved";
VAL_ 733 SysPwrMdCtrl 0 "SysPwrMdCtrl_0_NoRequest" 1 "SysPwrMdCtrl_1_Accessory" 2 "SysPwrMdCtrl_2_Run" 3 "SysPwrMdCtrl_3_Crank_Request" 4 "SysPwrMdCtrl_4_Change_to_normal_mode" 5 "SysPwrMdCtrl_5_Change_to_AD_mode" 6 "SysPwrMdCtrl_6_OFF";
VAL_ 733 APAEnRunReq 0 "APAEnRunReq_0_No_request" 1 "APAEnRunReq_1_Request";
VAL_ 733 LADSAFnInd 0 "LADSAFnInd_0_IDLE" 1 "LADSAFnInd_1_RADS" 2 "LADSAFnInd_2_ESSSwap_Park" 3 "LADSAFnInd_3_NPA" 4 "LADSAFnInd_4_AVP" 5 "LADSAFnInd_5_Remember_Build_Map" 6 "LADSAFnInd_6_Remember_Summon" 7 "LADSAFnInd_7_Remember_ParkIn" 8 "LADSAFnInd_8_RemoteOnekeyParkIn_Super" 9 "LADSAFnInd_9_ParkIn_super" 10 "LADSAFnInd_10_ParkIn" 11 "LADSAFnInd_11_ParkOut" 12 "LADSAFnInd_12_NRCD" 13 "LADSAFnInd_13_RemoteOnekeyParkIn" 14 "LADSAFnInd_14_RemoteOnekeyParkOut" 15 "LADSAFnInd_15_NCP";
VAL_ 590 RoadProfileShockDetectedL1 0 "RoadProfileShockDetectedL1_0_NotDetected" 1 "RoadProfileShockDetectedL1_1_SpeedBump" 2 "RoadProfileShockDetectedL1_2_Manhole_cover" 3 "RoadProfileShockDetectedL1_3_reserved" 4 "RoadProfileShockDetectedL1_4_reserved" 5 "RoadProfileShockDetectedL1_5_reserved" 6 "RoadProfileShockDetectedL1_6_reserved" 7 "RoadProfileShockDetectedL1_7_reserved" 8 "RoadProfileShockDetectedL1_8_reserved" 9 "RoadProfileShockDetectedL1_9_reserved" 10 "RoadProfileShockDetectedL1_10_reserved" 11 "RoadProfileShockDetectedL1_11_reserved" 12 "RoadProfileShockDetectedL1_12_reserved" 13 "RoadProfileShockDetectedL1_13_reserved" 14 "RoadProfileShockDetectedL1_14_reserved" 15 "RoadProfileShockDetectedL1_15_reserved";
VAL_ 590 RoadProfileShockDetectedL2 0 "RoadProfileShockDetectedL2_0_NotDetected" 1 "RoadProfileShockDetectedL2_1_SpeedBump" 2 "RoadProfileShockDetectedL2_2_Manhole_cover" 3 "RoadProfileShockDetectedL2_3_reserved" 4 "RoadProfileShockDetectedL2_4_reserved" 5 "RoadProfileShockDetectedL2_5_reserved" 6 "RoadProfileShockDetectedL2_6_reserved" 7 "RoadProfileShockDetectedL2_7_reserved" 8 "RoadProfileShockDetectedL2_8_reserved" 9 "RoadProfileShockDetectedL2_9_reserved" 10 "RoadProfileShockDetectedL2_10_reserved" 11 "RoadProfileShockDetectedL2_11_reserved" 12 "RoadProfileShockDetectedL2_12_reserved" 13 "RoadProfileShockDetectedL2_13_reserved" 14 "RoadProfileShockDetectedL2_14_reserved" 15 "RoadProfileShockDetectedL2_15_reserved";
VAL_ 590 RoadProfileShockDetectedL3 0 "RoadProfileShockDetectedL3_0_NotDetected" 1 "RoadProfileShockDetectedL3_1_SpeedBump" 2 "RoadProfileShockDetectedL3_2_Manhole_cover" 3 "RoadProfileShockDetectedL3_3_reserved" 4 "RoadProfileShockDetectedL3_4_reserved" 5 "RoadProfileShockDetectedL3_5_reserved" 6 "RoadProfileShockDetectedL3_6_reserved" 7 "RoadProfileShockDetectedL3_7_reserved" 8 "RoadProfileShockDetectedL3_8_reserved" 9 "RoadProfileShockDetectedL3_9_reserved" 10 "RoadProfileShockDetectedL3_10_reserved" 11 "RoadProfileShockDetectedL3_11_reserved" 12 "RoadProfileShockDetectedL3_12_reserved" 13 "RoadProfileShockDetectedL3_13_reserved" 14 "RoadProfileShockDetectedL3_14_reserved" 15 "RoadProfileShockDetectedL3_15_reserved";
VAL_ 590 PrvOutSts 0 "PrvOutSts_0_Disable" 1 "PrvOutSts_1_Normal" 2 "PrvOutSts_2_Passive" 3 "PrvOutSts_3_reserved";
VAL_ 590 RoadProfileShockDetectedR1 0 "RoadProfileShockDetectedR1_0_NotDetected" 1 "RoadProfileShockDetectedR1_1_SpeedBump" 2 "RoadProfileShockDetectedR1_2_Manhole_cover" 3 "RoadProfileShockDetectedR1_3_reserved" 4 "RoadProfileShockDetectedR1_4_reserved" 5 "RoadProfileShockDetectedR1_5_reserved" 6 "RoadProfileShockDetectedR1_6_reserved" 7 "RoadProfileShockDetectedR1_7_reserved" 8 "RoadProfileShockDetectedR1_8_reserved" 9 "RoadProfileShockDetectedR1_9_reserved" 10 "RoadProfileShockDetectedR1_10_reserved" 11 "RoadProfileShockDetectedR1_11_reserved" 12 "RoadProfileShockDetectedR1_12_reserved" 13 "RoadProfileShockDetectedR1_13_reserved" 14 "RoadProfileShockDetectedR1_14_reserved" 15 "RoadProfileShockDetectedR1_15_reserved";
VAL_ 590 RoadProfileShockDetectedR3 0 "RoadProfileShockDetectedR3_0_NotDetected" 1 "RoadProfileShockDetectedR3_1_SpeedBump" 2 "RoadProfileShockDetectedR3_2_Manhole_cover" 3 "RoadProfileShockDetectedR3_3_reserved" 4 "RoadProfileShockDetectedR3_4_reserved" 5 "RoadProfileShockDetectedR3_5_reserved" 6 "RoadProfileShockDetectedR3_6_reserved" 7 "RoadProfileShockDetectedR3_7_reserved" 8 "RoadProfileShockDetectedR3_8_reserved" 9 "RoadProfileShockDetectedR3_9_reserved" 10 "RoadProfileShockDetectedR3_10_reserved" 11 "RoadProfileShockDetectedR3_11_reserved" 12 "RoadProfileShockDetectedR3_12_reserved" 13 "RoadProfileShockDetectedR3_13_reserved" 14 "RoadProfileShockDetectedR3_14_reserved" 15 "RoadProfileShockDetectedR3_15_reserved";
VAL_ 590 RoadProfileShockDetectedR2 0 "RoadProfileShockDetectedR2_0_NotDetected" 1 "RoadProfileShockDetectedR2_1_SpeedBump" 2 "RoadProfileShockDetectedR2_2_Manhole_cover" 3 "RoadProfileShockDetectedR2_3_reserved" 4 "RoadProfileShockDetectedR2_4_reserved" 5 "RoadProfileShockDetectedR2_5_reserved" 6 "RoadProfileShockDetectedR2_6_reserved" 7 "RoadProfileShockDetectedR2_7_reserved" 8 "RoadProfileShockDetectedR2_8_reserved" 9 "RoadProfileShockDetectedR2_9_reserved" 10 "RoadProfileShockDetectedR2_10_reserved" 11 "RoadProfileShockDetectedR2_11_reserved" 12 "RoadProfileShockDetectedR2_12_reserved" 13 "RoadProfileShockDetectedR2_13_reserved" 14 "RoadProfileShockDetectedR2_14_reserved" 15 "RoadProfileShockDetectedR2_15_reserved";
VAL_ 1202 IPD_NM_BSMtoRMS_CHCANFD 0 "IPD_NM_BSMtoRMS_CHCANFD_0_False" 1 "IPD_NM_BSMtoRMS_CHCANFD_1_True";
VAL_ 1202 IPD_NM_PBSMtoRMS_CHCANFD 0 "IPD_NM_PBSMtoRMS_CHCANFD_0_False" 1 "IPD_NM_PBSMtoRMS_CHCANFD_1_True";
VAL_ 1202 IPD_NM_RMStoNOS_CHCANFD 0 "IPD_NM_RMStoNOS_CHCANFD_0_False" 1 "IPD_NM_RMStoNOS_CHCANFD_1_True";
VAL_ 1202 IPD_NM_RSStoNOS_CHCANFD 0 "IPD_NM_RSStoNOS_CHCANFD_0_False" 1 "IPD_NM_RSStoNOS_CHCANFD_1_True";
VAL_ 1202 IPD_NM_RSStoRMS_CHCANFD 0 "IPD_NM_RSStoRMS_CHCANFD_0_False" 1 "IPD_NM_RSStoRMS_CHCANFD_1_True";
VAL_ 1202 IPD_NM_NOStoRMS_CHCANFD 0 "IPD_NM_NOStoRMS_CHCANFD_0_False" 1 "IPD_NM_NOStoRMS_CHCANFD_1_True";
VAL_ 1202 IPD_NM_NOSSta_CHCANFD 0 "IPD_NM_NOSSta_CHCANFD_0_False" 1 "IPD_NM_NOSSta_CHCANFD_1_True";
VAL_ 1202 IPD_NM_RMSSta_CHCANFD 0 "IPD_NM_RMSSta_CHCANFD_0_False" 1 "IPD_NM_RMSSta_CHCANFD_1_True";
VAL_ 1202 IPD_NWI_CHCANFD 0 "IPD_NWI_CHCANFD_0_NoWakeNetworkSource" 1 "IPD_NWI_CHCANFD_1_PowerModeIsNonOFF" 2 "IPD_NWI_CHCANFD_2_OnboardChargerConnected";
VAL_ 1202 IPD_NOI_CHCANFD 0 "IPD_NOI_CHCANFD_0_NoRequest" 65535 "IPD_NOI_CHCANFD_65535_AllNetworkOperationActive";
VAL_ 1202 IPD_NKI_CHCANFD 0 "IPD_NKI_CHCANFD_0_NoRequest" 1 "IPD_NKI_CHCANFD_1_PowerModeIsNonOFF" 2 "IPD_NKI_CHCANFD_2_DOW" 3 "IPD_NKI_CHCANFD_3_RPA";
VAL_ 1267 RZCU_NM_BSMtoRMS_CHCANFD 0 "RZCU_NM_BSMtoRMS_CHCANFD_0_False" 1 "RZCU_NM_BSMtoRMS_CHCANFD_1_True";
VAL_ 1267 RZCU_NM_PBSMtoRMS_CHCANFD 0 "RZCU_NM_PBSMtoRMS_CHCANFD_0_False" 1 "RZCU_NM_PBSMtoRMS_CHCANFD_1_True";
VAL_ 1267 RZCU_NM_RMStoNOS_CHCANFD 0 "RZCU_NM_RMStoNOS_CHCANFD_0_False" 1 "RZCU_NM_RMStoNOS_CHCANFD_1_True";
VAL_ 1267 RZCU_NM_RSStoNOS_CHCANFD 0 "RZCU_NM_RSStoNOS_CHCANFD_0_False" 1 "RZCU_NM_RSStoNOS_CHCANFD_1_True";
VAL_ 1267 RZCU_NM_RSStoRMS_CHCANFD 0 "RZCU_NM_RSStoRMS_CHCANFD_0_False" 1 "RZCU_NM_RSStoRMS_CHCANFD_1_True";
VAL_ 1267 RZCU_NM_NOStoRMS_CHCANFD 0 "RZCU_NM_NOStoRMS_CHCANFD_0_False" 1 "RZCU_NM_NOStoRMS_CHCANFD_1_True";
VAL_ 1267 RZCU_NM_NOSSta_CHCANFD 0 "RZCU_NM_NOSSta_CHCANFD_0_False" 1 "RZCU_NM_NOSSta_CHCANFD_1_True";
VAL_ 1267 RZCU_NM_RMSSta_CHCANFD 0 "RZCU_NM_RMSSta_CHCANFD_0_False" 1 "RZCU_NM_RMSSta_CHCANFD_1_True";
VAL_ 1267 RZCU_NWI_CHCANFD 0 "RZCU_NWI_CHCANFD_0_NoWakeNetworkSource" 1 "RZCU_NWI_CHCANFD_1_PowerModeIsRuncrank" 2 "RZCU_NWI_CHCANFD_2_ThermalFaultActive" 5 "RZCU_NWI_CHCANFD_5_OffboardChargerConnected" 8 "RZCU_NWI_CHCANFD_8_PLGOpenDetectByPriMarySwitch" 9 "RZCU_NWI_CHCANFD_9_PLGCloseDetectByPriMarySwitch" 10 "RZCU_NWI_CHCANFD_10_PLGOpenDetectBySecondarySwitch" 12 "RZCU_NWI_CHCANFD_12_PwrlftgtCloseRequest" 15 "RZCU_NWI_CHCANFD_15_EasyLdSwthReqRequest" 16 "RZCU_NWI_CHCANFD_16_ChrgFlapDoorAjarSwActive" 17 "RZCU_NWI_CHCANFD_17_RrSeatBrkSwActive";
VAL_ 1267 RZCU_NOI_CHCANFD 0 "RZCU_NOI_CHCANFD_0_NoRequest" 65535 "RZCU_NOI_CHCANFD_65535_AllNetworkOperationActive";
VAL_ 1267 RZCU_NKI_CHCANFD 0 "RZCU_NKI_CHCANFD_0_NoRequest" 1 "RZCU_NKI_CHCANFD_1_PowerModeIsNonOFF" 2 "RZCU_NKI_CHCANFD_2_ThermalFaultActive" 16 "RZCU_NKI_CHCANFD_16_HVBulid" 256 "RZCU_NKI_CHCANFD_256_RWSActive" 512 "RZCU_NKI_CHCANFD_512_ChargerFlapTimeWindow" 1024 "RZCU_NKI_CHCANFD_1024_EasyLdSwthReqRequest";
VAL_ 143 AngularRateXsecinfoV 0 "AngularRateXsecinfoV_0_Valid" 1 "AngularRateXsecinfoV_1_Invalid";
VAL_ 143 AccelerationZsecinfoV 0 "AccelerationZecinfoV_0_Valid" 1 "AccelerationZsecinfoV_1_Invalid";
VAL_ 143 AccelerationYsecinfoV 0 "AccelerationYsecinfoV_0_Valid" 1 "AccelerationYsecinfoV_1_Invalid";
VAL_ 143 AccelerationXsecinfoV 0 "AccelerationXsecinfoV_0_Valid" 1 "AccelerationXsecinfoV_1_Invalid";
VAL_ 143 TireBlowoutStabCtrlSts 0 "TireBlowoutStabCtrlSts_0_Inactive" 1 "TireBlowoutStabCtrlSts_1_Active";
VAL_ 143 AngularRateZsecinfoV 0 "AngularRateZsecinfoV_0_Valid" 1 "AngularRateZsecinfoV_1_Invalid";
VAL_ 143 AngularRateYsecinfoV 0 "AngularRateYsecinfoV_0_Valid" 1 "AngularRateYsecinfoV_1_Invalid";
VAL_ 143 TireBlowoutPos 0 "TireBlowoutPos_0_No_Tire_Blowout" 1 "TireBlowoutPos_1_FL_Tire_Blowout" 2 "TireBlowoutPos_2_FR_Tire_Blowout" 3 "TireBlowoutPos_3_FL_FR_Tire_Blowout" 4 "TireBlowoutPos_4_RL_Tire_Blowout" 5 "TireBlowoutPos_5_FL_RL_Tire_Blowout" 6 "TireBlowoutPos_6_FR_RL_Tire_Blowout" 7 "TireBlowoutPos_7_FL_FR_RL_Tire_Blowout" 8 "TireBlowoutPos_8_RR_Tire_Blowout" 9 "TireBlowoutPos_9_FL_RR_Tire_Blowout" 10 "TireBlowoutPos_10_FR_RR_Tire_Blowout" 11 "TireBlowoutPos_11_FL_FR_RR_Tire_Blowout" 12 "TireBlowoutPos_12_RL_RR_Tire_Blowout" 13 "TireBlowoutPos_13_FL_RL_RR_Tire_Blowout" 14 "TireBlowoutPos_14_FR_RL_RR_Tire_Blowout" 15 "TireBlowoutPos_15_FL_FR_RL_RR_Tire_Blowout";
VAL_ 1216 ZXD_NM_BSMtoRMS_CHCANFD 0 "ZXD_NM_BSMtoRMS_CHCANFD_0_False" 1 "ZXD_NM_BSMtoRMS_CHCANFD_1_True";
VAL_ 1216 ZXD_NM_PBSMtoRMS_CHCANFD 0 "ZXD_NM_PBSMtoRMS_CHCANFD_0_False" 1 "ZXD_NM_PBSMtoRMS_CHCANFD_1_True";
VAL_ 1216 ZXD_NM_RMStoNOS_CHCANFD 0 "ZXD_NM_RMStoNOS_CHCANFD_0_False" 1 "ZXD_NM_RMStoNOS_CHCANFD_1_True";
VAL_ 1216 ZXD_NM_RSStoNOS_CHCANFD 0 "ZXD_NM_RSStoNOS_CHCANFD_0_False" 1 "ZXD_NM_RSStoNOS_CHCANFD_1_True";
VAL_ 1216 ZXD_NM_RSStoRMS_CHCANFD 0 "ZXD_NM_RSStoRMS_CHCANFD_0_False" 1 "ZXD_NM_RSStoRMS_CHCANFD_1_True";
VAL_ 1216 ZXD_NM_NOStoRMS_CHCANFD 0 "ZXD_NM_NOStoRMS_CHCANFD_0_False" 1 "ZXD_NM_NOStoRMS_CHCANFD_1_True";
VAL_ 1216 ZXD_NM_NOSSta_CHCANFD 0 "ZXD_NM_NOSSta_CHCANFD_0_False" 1 "ZXD_NM_NOSSta_CHCANFD_1_True";
VAL_ 1216 ZXD_NM_RMSSta_CHCANFD 0 "ZXD_NM_RMSSta_CHCANFD_0_False" 1 "ZXD_NM_RMSSta_CHCANFD_1_True";
VAL_ 1216 ZXD_NWI_CHCANFD 0 "ZXD_NWI_CHCANFD_0_NoWakeNetworkSource" 1 "ZXD_NWI_CHCANFD_1_PowerModeIsNonOFF";
VAL_ 1216 ZXD_NOI_CHCANFD 0 "ZXD_NOI_CHCANFD_0_NoRequest" 65535 "ZXD_NOI_CHCANFD_65535_AllNetworkOperationActive";
VAL_ 1216 ZXD_NKI_CHCANFD 0 "ZXD_NKI_CHCANFD_0_NoRequest" 1 "ZXD_NKI_CHCANFD_1_PowerModeIsNonOFF";
VAL_ 2164461571 EPSAESReqResp 0 "EPSAESResp_0_Inhibit" 1 "EPSAESReqResp_1_Available" 2 "EPSAESReqResp_2_Active" 3 "EPSAESReqResp_3_Abort" 4 "EPSAESReqResp_4_ReplyForControl" 5 "EPSAESReqResp_5_Reserve" 6 "EPSAESReqResp_6_Reserve" 7 "EPSAESResp_7_Failure" 8 "EPSAESResp_8_Reserve";
VAL_ 2164461571 EPSAESStsInh 0 "EPSAIPkgAngReqResp_0_Inhibit" 1 "EPSAIPkgAngReqResp_1_Available" 2 "EPSAIPkgAngReqResp_2_Active" 3 "EPSAIPkgAngReqResp_3_Abort" 4 "EPSAIPkgAngReqResp_4_ReplyForControl" 5 "EPSAIPkgAngReqResp_5_Reserve" 6 "EPSAIPkgAngReqResp_6_Reserve" 7 "EPSAIPkgAngReqResp_7_Failure" 8 "EPSAIPkgAngReqResp_8_Reserve";
VAL_ 2164461571 EPSVMCAngRespSts 0 "EPSVMCAngRespSts_0_Init" 1 "EPSVMCAngRespSts_1_Off" 2 "EPSVMCAngRespSts_2_Ready" 3 "EPSVMCAngRespSts_3_Fadeln" 4 "EPSVMCAngRespSts_4_Active" 5 "EPSVMCAngRespSts_5_FadeOut" 6 "EPSVMCAngRespSts_6_Error" 7 "EPSVMCAngRespSts_7_Reserved";
VAL_ 2164461571 EPSAESReqTorRespV 0 "EPSAESReqTorV_0_Valid" 1 "EPSAESReqTorV_1_Invalid";
VAL_ 2164461571 EPSVMCRespStsInh 0 "EPSVMCRespStsInh_0_NormalOperation" 1 "EPSVMCRespStsInh_1_OverSpeed" 2 "EPSVMCRespStsInh_2_DriverInterference" 4 "EPSVMCRespStsInh_4_AbnormalCanInput" 8 "EPSVMCRespStsInh_8_Reserve" 16 "EPSVMCRespStsInh_16_EpsFailure" 32 "EPSVMCRespStsInh_32_Reserve" 64 "EPSVMCRespStsInh_64_Reserve" 128 "EPSVMCRespStsInh_128_Reserve";
VAL_ 2164461571 EPSVMCCodrivingSts 0 "EPSVMCCodrivingSts_0_Unavaliable" 1 "EPSVMCCodrivingSts_1_Non_Co_DrivingMode" 2 "EPSVMCCodrivingSts_2_Co_DrivingMode" 3 "EPSVMCCodrivingSts_3_Reserved";
VAL_ 2164729093 ActuRoadWhlAngV 0 "ActuRoadWhlAngV_0_Valid" 1 "ActuRoadWhlAngV_1_Invalid";
VAL_ 2164729093 ADASStrgDlvrdToqV 0 "ADASStrgDlvrdToqV_0_Valid" 1 "ADASStrgDlvrdToqV_1_Invalid";
VAL_ 2164729093 EPSDrvngMdCtrlInh 0 "EPSDrvngMdCtrlInh_0_False" 1 "EPSDrvngMdCtrlInh_1_True";
VAL_ 2164729093 DrvrStrgDlvrdToqV 0 "DrvrStrgDlvrdToqV_0_Valid" 1 "DrvrStrgDlvrdToqV_1_Invalid";
VAL_ 2164729093 StrgCustSetngDspCmd 0 "StrgCustSetngDspCmd_0_FunctionDisable" 1 "StrgCustSetngDspCmd_1_ComfortableMode" 2 "StrgCustSetngDspCmd_2_NormalMode" 3 "StrgCustSetngDspCmd_3_SportMode";
VAL_ 2164729093 EPSPriyChnlFlrSts 0 "EPSPriyChnlFlrSts_0_NoFailure" 1 "EPSPriyChnlFlrSts_1_LightLevelFailure" 2 "EPSPriyChnlFlrSts_2_HeavyLevelFailure";
VAL_ 2164729093 EPSFlrSts 0 "EPSFlrSts_0_EpsNoFailure_indicationOff" 1 "EPSFlrSts_1_EpsLightLevelFailureIndication_orange" 2 "EPSFlrSts_2_EpsHeavyLevelFailureIndication_red" 3 "EPSFlrSts_3_Invalid";
VAL_ 2164729093 EPSCurntDrvMd 0 "EPSCurntDrvMd_0_ADASMode" 1 "EPSCurntDrvMd_1_ComfortableMode" 2 "EPSCurntDrvMd_2_NormalMode" 3 "EPSCurntDrvMd_3_SportMode";
VAL_ 2164729093 ActuPnonAngV 0 "ActuPnonAngV_0_Valid" 1 "ActuPnonAngV_1_Invalid";
VAL_ 2164729093 EPSToqValAldMaxV 0 "EPSToqValAldMaxV_0_Valid" 1 "EPSToqValAldMaxV_1_Invalid";
VAL_ 2164729093 EPSLimMotToqV 0 "EPSLimMotToqV_0_Valid" 1 "EPSLimMotToqV_1_Invalid";
VAL_ 2164729093 EPSActRetMotToqV 0 "EPSActRetMotToqV_0_Valid" 1 "EPSActRetMotToqV_1_Invalid";
VAL_ 2164729093 ChLKAAngReqResp 0 "ChLKAAngReqResp_0_NoRequest" 1 "ChLKAAngReqResp_1_RequestHonored" 2 "ChLKAAngReqResp_2_LostArbitrary" 3 "ChLKAAngReqResp_3_ControlNotAllowedForFailure" 4 "ChLKAAngReqResp_4_Pre_conditionNotSatisfied" 5 "ChLKAAngReqResp_5_Initialization" 6 "ChLKAAngReqResp_6_EMA" 7 "ChLKAAngReqResp_7_Reserved";
VAL_ 2164729093 EPSToqValAldMinV 0 "EPSToqValAldMinV_0_Valid" 1 "EPSToqValAldMinV_1_Invalid";
VAL_ 2164729093 CHLKAHptResp 0 "CHLKAHptResp_0_NoRequest" 1 "CHLKAHptResp_1_RequestHonored" 2 "CHLKAHptResp_2_LostArbitrary" 3 "CHLKAHptResp_3_ControlNotAllowedForFailure" 4 "CHLKAHptResp_4_Pre_conditionNotSatisfied" 5 "CHLKAHptResp_5_Initialization";
VAL_ 2164729093 ChLKAToqReqResp 0 "ChLKAToqReqResp_0_NoRequest" 1 "ChLKAToqReqResp_1_RequestHonored" 2 "ChLKAToqReqResp_2_LostArbitrary" 3 "ChLKAToqReqResp_3_ControlNotAllowedForFailure" 4 "ChLKAToqReqResp_4_Pre_conditionNotSatisfied" 5 "ChLKAToqReqResp_5_Initialization" 6 "ChLKAToqReqResp_6_Reserved" 7 "ChLKAToqReqResp_7_Reserved";
VAL_ 2164729093 EPSCoDrivingSts 0 "EPSCoDrivingSts_0_Unavaliable" 1 "EPSCoDrivingSts_1_Non_Co_DrivingMode" 2 "EPSCoDrivingSts_2_Co_DrivingMode" 3 "EPSCoDrivingSts_3_Reserved";
VAL_ 2164729094 EPSAIPkgAngReqResp 0 "EPSAIPkgAngReqResp_0_Inhibit" 1 "EPSAIPkgAngReqResp_1_Available" 2 "EPSAIPkgAngReqResp_2_Active" 3 "EPSAIPkgAngReqResp_3_Abort" 4 "EPSAIPkgAngReqResp_4_ReplyForControl" 5 "EPSAIPkgAngReqResp_5_Reserve" 6 "EPSAIPkgAngReqResp_6_Reserve" 7 "EPSAIPkgAngReqResp_7_Failure" 8 "EPSAIPkgAngReqResp_8_Reserve";
VAL_ 2164729094 EPSAIPkgAngReqRespInh 0 "EPSAIPkgAngReqRespInh_0_NormalOperation" 1 "EPSAIPkgAngReqRespInh_1_OverSpeed" 2 "EPSAIPkgAngReqRespInh_2_DriverInterference" 4 "EPSAIPkgAngReqRespInh_4_AbnormalCanInput" 8 "EPSAIPkgAngReqRespInh_8_ExcessAngleDeviation" 16 "EPSAIPkgAngReqRespInh_16_EpsFailure" 32 "EPSAIPkgAngReqRespInh_32_Reserve" 64 "EPSAIPkgAngReqRespInh_64_Reserve" 128 "EPSAIPkgAngReqRespInh_128_Reserve";
VAL_ 2164729094 EPSAIPltAngRespStsInh 0 "EPSAIPltAngRespStsInh_0_NormalOperation" 1 "EPSAIPltAngRespStsInh_1_OverSpeed" 2 "EPSAIPltAngRespStsInh_2_DriverInterference" 4 "EPSAIPltAngRespStsInh_4_AbnormalCanInputtoFVCM" 8 "EPSAIPltAngRespStsInh_8_AbnormalCanInputtoZXD" 16 "EPSAIPltAngRespStsInh_10_EpsFailure" 18 "EPSAIPltAngRespStsInh_12_AbnormalCanInputtoFVCMandZXD" 32 "EPSAIPltAngRespStsInh_20_Reserve" 64 "EPSAIPltAngRespStsInh_40_Reserve" 128 "EPSAIPltAngRespStsInh_80_Reserve";
VAL_ 2164729094 EPSAIPltAvlLvl 0 "EPSAIPltAvlLvl_0_HadNotAvailable" 1 "EPSAIPltAvlLvl_1_HadAvailableDegraded" 2 "EPSAIPltAvlLvl_2_HadAvailable" 3 "EPSAIPltAvlLvl_3_Minor_Error";
VAL_ 2164729094 EPSAIPltAngRespSts 0 "EPSAIPltAngRespSts_0_Init" 1 "EPSAIPltAngRespSts_1_Off" 2 "EPSAIPltAngRespSts_2_Ready" 3 "EPSAIPltAngRespSts_3_Fadeln" 4 "EPSAIPltAngRespSts_4_HO_Active" 5 "EPSAIPltAngRespSts_5_Emergency_function_active" 6 "EPSAIPltAngRespSts_6_Error" 7 "EPSAIPltAngRespSts_7_HF_active";
VAL_ 2164729094 ActuRoadWhlAngGrdV 0 "ActuRoadWhlAngGrdV_0_Valid" 1 "ActuRoadWhlAngGrdV_1_Invalid";
VAL_ 2164729094 EPSAIPltCtrlChannel 0 "EPSAIPltCtrlChannel_0_Primary" 1 "EPSAIPltCtrlChannel_1_Secondary";
VAL_ 2164729094 ActuRoadWhlAngGrd 65535 "ActuRoadWhlAngGrd_65535_error_mark";
VAL_ 2164729108 StrgWhlAngSnsrFlt 0 "StrgWhlAngSnsrFlt_0_False" 1 "StrgWhlAngSnsrFlt_1_True";
VAL_ 2164729108 StrgWhlAngV 0 "StrgWhlAngV_0_Valid" 1 "StrgWhlAngV_1_Invalid";
VAL_ 2164729108 StrgWhlAngSnsrMultCapb 0 "StrgWhlAngSnsrMultCapb_0_False" 1 "StrgWhlAngSnsrMultCapb_1_True";
VAL_ 2164729108 StrgWhlAngSnsrInid 0 "StrgWhlAngSnsrInid_0_False" 1 "StrgWhlAngSnsrInid_1_True";
VAL_ 2164729108 StrgWhlAng 65535 "StrgWhlAng_65535_ErrorMark";
VAL_ 2164729108 StrgWhlAngGrd 4095 "StrgWhlAngGrd_4095_ErrorMark";
VAL_ 2164729108 StrgWhlAngSnsrCalSts 0 "StrgWhlAngSnsrCalSts_0_Unknown" 1 "StrgWhlAngSnsrCalSts_1_Estimated" 2 "StrgWhlAngSnsrCalSts_2_Calibrated" 3 "StrgWhlAngSnsrCalSts_3_Unknown";
VAL_ 2164729095 EPBSysBrkLghtsReqdA 0 "EPBSysBrkLghtsReqdA_0_False" 1 "EPBSysBrkLghtsReqdA_1_True";
VAL_ 2164729095 BrkSysBrkLghtsReqd 0 "BrkSysBrkLghtsReqd_0_False" 1 "BrkSysBrkLghtsReqd_1_True";
VAL_ 2164729095 BrkPdlPosV 0 "BrkPdlPosV_0_Valid" 1 "BrkPdlPosV_1_Invalid";
VAL_ 2164729097 BrkPdlDrvrAppdPrsV 0 "BrkPdlDrvrAppdPrsV_0_Valid" 1 "BrkPdlDrvrAppdPrsV_1_Invalid";
VAL_ 2164729097 BrkPdlDrvrAppdPrsDetV 0 "BrkPdlDrvrAppdPrsDetV_0_Valid" 1 "BrkPdlDrvrAppdPrsDetV_1_Invalid";
VAL_ 2164729097 BrkPdlDrvrAppdPrsDet 0 "BrkPdlDrvrAppdPrsDet_0_False" 1 "BrkPdlDrvrAppdPrsDet_1_True";
VAL_ 2164729097 BrkDiscTemSts 0 "BrkDiscTemSts_0_Not_high" 1 "BrkDiscTemSts_1_Temperature_too_high";
VAL_ 2164729097 BrkPdlMdlSts 0 "BrkPdlMdlSts_0_Normal" 1 "BrkPdlMdlSts_1_comfort" 2 "BrkPdlMdlSts_2_sport" 3 "BrkPdlMdlSts_3_Reserve";
VAL_ 2164729097 DrvrReqOtptRodTrvlSts 0 "DrvrReqOtptRodTrvlSts_0_Init" 1 "DrvrReqOtptRodTrvlSts_1_Normal" 2 "DrvrReqOtptRodTrvlSts_2_Faulty";
VAL_ 2164729097 BrkPdlSimltdPrsV 0 "BrkPdlSimltdPrsV_0_Valid" 1 "BrkPdlSimltdPrsV_1_Invalid";
VAL_ 2164729097 BrkPdlAppd 0 "BrkPdlAppd_0_BrakePedalNotApplied" 1 "BrkPdlAppd_1_BrakePedalApplied";
VAL_ 2164729097 BrkPdlAppdV 0 "BrkPdlAppdV_0_Init" 1 "BrkPdlAppdV_1_Normal" 2 "BrkPdlAppdV_2_Faulty";
VAL_ 2164729097 BrkFludLvlLowV 0 "BrkFludLvlLowV_0_Valid" 1 "BrkFludLvlLowV_1_Invalid";
VAL_ 2164729097 BrkFludLvlLow 0 "BrkFludLvlLow_0_False" 1 "BrkFludLvlLow_1_True";
VAL_ 2164729097 BrkPdlMdlActSts 0 "BrkPdlMdlActSts_0_Normal" 1 "BrkPdlMdlActSts_1_comfort" 2 "BrkPdlMdlActSts_2_sport" 3 "BrkPdlMdlActSts_3_Reserve";
VAL_ 2164729104 ACCBrkngA 0 "ACCBrkngA_0_False" 1 "ACCBrkngA_1_True";
VAL_ 2164729104 ChAEBDclReqResp 0 "ChAEBDclReqResp_0_no_request" 1 "ChAEBDclReqResp_1_request_honored" 2 "ChAEBDclReqResp_2_lost_arbitration" 3 "ChAEBDclReqResp_3_control_not_allowed_for_error" 4 "ChAEBDclReqResp_4_pre_condition_not_satisfied" 5 "ChAEBDclReqResp_5_Request_received_no_fault_but_not_honoured" 6 "ChAEBDclReqResp_6_Reserved" 7 "ChAEBDclReqResp_7_Reserved";
VAL_ 2164729104 ChACCReqFlrSts 0 "ChACCReqFlrSts_0_No_error" 1 "ChACCReqFlrSts_1_reversible_error" 2 "ChACCReqFlrSts_2_irreversible_error" 3 "ChACCReqFlrSts_3_not_defined";
VAL_ 2164729104 ChACCAccReqResp 0 "ChACCAccReqResp_0_no_request" 1 "ChACCAccReqResp_1_request_honored" 2 "ChACCAccReqResp_2_lost_arbitration" 3 "ChACCAccReqResp_3_control_not_allowed_for_error" 4 "ChACCAccReqResp_4_pre_condition_not_satisfied" 5 "ChACCAccReqResp_5_Request_received_no_fault_but_not_honoured" 6 "ChACCAccReqResp_6_Reserved" 7 "ChACCAccReqResp_7_Reserved";
VAL_ 2164729104 ChAEBPrflReqResp 0 "ChAEBPrflReqResp_0_no_request" 1 "ChAEBPrflReqResp_1_request_honored" 2 "ChAEBPrflReqResp_2_lost_arbitration" 3 "ChAEBPrflReqResp_3_control_not_allowed_for_error" 4 "ChAEBPrflReqResp_4_pre_condition_not_satisfied" 5 "ChAEBPrflReqResp_5_Request_received_no_fault_but_not_honoured" 6 "ChAEBPrflReqResp_6_Reserved" 7 "ChAEBPrflReqResp_7_Reserved";
VAL_ 2164729104 AutodDrvngSysMdReqRespV 0 "AutodDrvngSysMdReqRespV_0_Valid" 1 "AutodDrvngSysMdReqRespV_1_Invalid";
VAL_ 2164729104 AutodDrvngSysMdReqResp 0 "AutodDrvngSysMdReqResp_0_NoRequest" 1 "AutodDrvngSysMdReqResp_1_ReqestHonred";
VAL_ 2164729104 ChAEBHydBrkAstReqResp 0 "ChAEBHydBrkAstReqResp_0_no_request" 1 "ChAEBHydBrkAstReqResp_1_request_honored" 2 "ChAEBHydBrkAstReqResp_2_lost_arbitration" 3 "ChAEBHydBrkAstReqResp_3_control_not_allowed_for_error" 4 "ChAEBHydBrkAstReqResp_4_pre_condition_not_satisfied" 5 "ChAEBHydBrkAstReqResp_5_Request_received_no_fault_but_not_honoured" 6 "ChAEBHydBrkAstReqResp_6_Reserved" 7 "ChAEBHydBrkAstReqResp_7_Reserved";
VAL_ 2164729104 ChAEBBrkJerkReqResp 0 "ChAEBBrkJerkReqResp_0_no_request" 1 "ChAEBBrkJerkReqResp_1_request_honored" 2 "ChAEBBrkJerkReqResp_2_lost_arbitration" 3 "ChAEBBrkJerkReqResp_3_control_not_allowed_for_error" 4 "ChAEBBrkJerkReqResp_4_pre_condition_not_satisfied" 5 "ChAEBBrkJerkReqResp_5_Request_received_no_fault_but_not_honoured" 6 "ChAEBBrkJerkReqResp_6_reserved6" 7 "ChAEBBrkJerkReqResp_7_reserved7";
VAL_ 2164729104 SCSAutodDrvngSysSts 0 "SCSAutodDrvngSysSts_0_TemporaryNotAvailable" 1 "SCSAutodDrvngSysSts_1_TemporaryNotReleased" 2 "SCSAutodDrvngSysSts_2_PermanentNotAvailable" 3 "SCSAutodDrvngSysSts_3_FullAvailable" 4 "SCSAutodDrvngSysSts_4_RedudancyLost" 5 "SCSAutodDrvngSysSts_5_FailOperation";
VAL_ 2164729104 SCSAPAAcclAV 0 "SCSAPAAcclAV_0_Valid" 1 "SCSAPAAcclAV_1_Invalid";
VAL_ 2164729104 SCSAPAAcclA 0 "SCSAPAAcclA_0_Inactive" 1 "SCSAPAAcclA_1_Active";
VAL_ 2164729104 ExtnlBrkPrioV 0 "ExtnlBrkPrioV_0_Valid" 1 "ExtnlBrkPrioV_1_Invalid";
VAL_ 2164729104 ExtnlBrkPrio 0 "ExtnlBrkPrio_0_EBR_NotDominate" 1 "ExtnlBrkPrio_1_EBR_Dominate";
VAL_ 2164729104 EmgcBrkReqdByIECUSts 0 "EmgcBrkReqdByIECUSts_0_False" 1 "EmgcBrkReqdByIECUSts_1_True";
VAL_ 2164729104 TCSDrvrItnt 0 "TCSDrvrItnt_0_Disabled" 1 "TCSDrvrItnt_1_Enabled";
VAL_ 2164729104 MultColBrkAvlblySts 0 "MultColBrkAvlblySts_0_Unavailable" 1 "MultColBrkAvlblySts_1_Available";
VAL_ 2164729104 ChRCTBDclReqResp 0 "ChRCTBDclReqResp_0_no_request" 1 "ChRCTBDclReqResp_1_request_honored" 2 "ChRCTBDclReqResp_2_lost_arbitration" 3 "ChRCTBDclReqResp_3_control_not_allowed_for_error" 4 "ChRCTBDclReqResp_4_pre_condition_not_satisfied" 5 "ChRCTBDclReqResp_5_request_received_not_fault_but_not_honored" 6 "ChRCTBDclReqResp_6_reserved" 7 "ChRCTBDclReqResp_7_reserved";
VAL_ 2164729104 SCSVehHoldAV 0 "SCSVehHoldAV_0_Valid" 1 "SCSVehHoldAV_1_Invalid";
VAL_ 2164729104 SCSVehHoldA 0 "SCSVehHoldA_0_NotActivelyHeld" 1 "SCSVehHoldA_1_ActivelyHeld";
VAL_ 2164729104 SCSAutodDrvngSysStsV 0 "SCSAutodDrvngSysStsV_0_Valid" 1 "SCSAutodDrvngSysStsV_1_Invalid";
VAL_ 2164729104 VehSdslStsV 0 "VehSdslStsV_0_Valid" 1 "VehSdslStsV_1_Invalid";
VAL_ 2164729104 ChRCTBPrflReqResp 0 "ChRCTBPrflReqResp_0_no_request" 1 "ChRCTBPrflReqResp_1_request_honored" 2 "ChRCTBPrflReqResp_2_lost_arbitration" 3 "ChRCTBPrflReqResp_3_control_not_allowed_for_error" 4 "ChRCTBPrflReqResp_4_pre_condition_not_satisfied" 5 "ChRCTBPrflReqResp_5_reserved" 6 "ChRCTBPrflReqResp_6_reserved" 7 "ChRCTBPrflReqResp_7_reserved";
VAL_ 2164729104 WhlBrkPrsSts 0 "WhlBrkPrsSts_0_Exist_brake_force" 1 "WhlBrkPrsSts_1_No_brake_force";
VAL_ 2164729104 BrkSysRddySysSts 0 "BrkSysRddySysSts_0_FullAvailable" 1 "BrkSysRddySysSts_1_NotAvailable";
VAL_ 2164729104 VehSdslSts 0 "VehSdslSts_0_not_standstill" 1 "VehSdslSts_1_standstill" 2 "VehSdslSts_2_invalid_short_unavailability_max_3s" 3 "VehSdslSts_3_reserved";
VAL_ 2164729104 ChEBADclReqResp 0 "ChEBADclReqResp_0_NoRequest" 1 "ChEBADclReqResp_1_RequestHonored" 2 "ChEBADclReqResp_2_LostArbitration" 3 "ChEBADclReqResp_3_ControlNotAllowedForError" 4 "ChEBADclReqResp_4_Pre_conditionNotSatisfied" 6 "ChEBADclReqResp_6_reserved" 7 "ChEBADclReqResp_7_reserved";
VAL_ 2164729104 IBSAPASysFltSts 0 "IBSAPASysFltSts_0_FullAvailable" 1 "IBSAPASysFltSts_1_NotAvailable";
SIG_GROUP_ 98 IICBAD_ZONE_10ms_Group20 1 : ICBAD_ZONE_10ms_Group20_CRC ICBAD_ZONE_10ms_Group20_RC ICBAD_ZONE_10ms_Group20_Reserved0 ICBAD_ZONE_10ms_Group20_Reserved1 ICBAD_ZONE_10ms_Group20_Reserved2 ICBAD_ZONE_10ms_Group20_Reserved3 ICBAD_ZONE_10ms_Group20_Reserved4 ICBAD_ZONE_10ms_Group20_Reserved5 LKAToqReqValMax LKAToqReqValMin;
SIG_GROUP_ 81 IICBAD_ZONE_20ms_Group13 1 : ACCToqReqSts ACCToqReqVal ICBAD_ZONE_20ms_Group13_CRC ICBAD_ZONE_20ms_Group13_RC ICBAD_ZONE_20ms_Group13_Reserved0 ICBAD_ZONE_20ms_Group13_Reserved1 ICBAD_ZONE_20ms_Group13_Reserved2 ICBAD_ZONE_20ms_Group13_Reserved3 ICBAD_ZONE_20ms_Group13_Reserved4 ICBAD_ZONE_20ms_Group13_Reserved5 LKASysFltSts LKASysSts TJAICASysFltSts TJAICASysSts;
SIG_GROUP_ 486 IIPD_20ms_Group43 1 : ACCAccReqToqVal ACCSysFltSts_SCS FrtCarGoNotfr IPD_20ms_Group43_CRC IPD_20ms_Group43_RC IPD_20ms_Group43_Reserved1 IPD_20ms_Group43_Reserved2 IPD_20ms_Group43_Reserved3 IPD_20ms_Group43_Reserved4 IPD_20ms_Group43_Reserved5;
SIG_GROUP_ 337 IIPD_20ms_Group60 1 : ALCSysFltSts ALCSysSts APASCSToqReqVal APAVehCrdnatAzmth APAVehCrdnatPosX APAVehCrdnatPosY AutoLaneChngLLaneSts AutoLaneChngRLaneSts ESSDirInd ESSDrvrTkovReq ESSSysFltSts ESSSysSts IPD_20ms_Group60_CRC IPD_20ms_Group60_RC IPD_20ms_Group60_Reserved1 IPD_20ms_Group60_Reserved10 IPD_20ms_Group60_Reserved11 IPD_20ms_Group60_Reserved2 IPD_20ms_Group60_Reserved4 IPD_20ms_Group60_Reserved5 IPD_20ms_Group60_Reserved6 IPD_20ms_Group60_Reserved7 IPD_20ms_Group60_Reserved8 IPD_20ms_Group60_Reserved9 NOPSysFltSts NOPSysSts_ZPD Parkngslottype PilotTkovMsgReq PrkgDstCtrlSwResp;
SIG_GROUP_ 733 IIPD_50ms_Group49 1 : APAEnRunReq IPD_50ms_Group49_CRC IPD_50ms_Group49_RC IPD_50ms_Group49_Reserved1 IPD_50ms_Group49_Reserved2 IPD_50ms_Group49_Reserved3 IPD_50ms_Group49_Reserved4 IPD_50ms_Group49_Reserved5 IPD_50ms_Group49_Reserved6 KeepPwrRsnIPD LADSAFnInd SysPwrMdCtrl;
SIG_GROUP_ 143 IRZCU_ZONE_10ms_Group64 1 : AccelerationXsecinfo AccelerationXsecinfoV AccelerationYsecinfo AccelerationYsecinfoV AccelerationZsecinfo AccelerationZsecinfoV AngularRateXsecinfo AngularRateXsecinfoV AngularRateYsecinfo AngularRateYsecinfoV AngularRateZsecinfo AngularRateZsecinfoV IMUTmp IMUseq RZCU_ZONE_10ms_Group64_CRC RZCU_ZONE_10ms_Group64_RC RZCU_ZONE_10ms_Group64_Reserved1 RZCU_ZONE_10ms_Group64_Reserved2 RZCU_ZONE_10ms_Group64_Reserved3 RZCU_ZONE_10ms_Group64_Reserved4 RZCU_ZONE_10ms_Group64_Reserved5 RZCU_ZONE_10ms_Group64_Reserved6 TireBlowoutPos TireBlowoutStabCtrlSts;
